VERSION "created by canmatrix"

NS_ :

BS_:

BU_: TCM iBooster HCU CIM SCM Right_Hand_Control Left_Hand_Control GPS VCM IC_2 XM GMRS Radio_CANtool Diagnostic_Tool_Digital_Wrench Information_System_Controller_1 STEERING_CONTROLLER VEHICLE_SECURITY RADIO_Hub ABS Battery_Management_Cntrl_2 Battery_Management_Cntrl_1 Auxiliary_Power_Unit_2 Auxiliary_Power_Unit_1 Electric_Propulsion_Cntrl_Unit_4 Electric_Propulsion_Cntrl_Unit_3 Electric_Propulsion_Cntrl_Unit_2 Electric_Propulsion_Cntrl_Unit_1 ECM IC

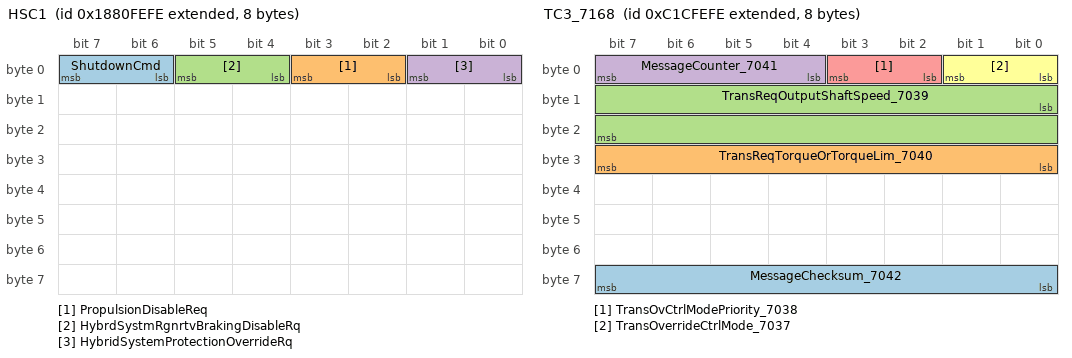
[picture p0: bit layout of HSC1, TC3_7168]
BO_ 2558590718 HSC1: 8 Vector__XXX
 SG_ ShutdownCmd : 6|2@1+ (1,0) [0.0|3.0] "" Vector__XXX
 SG_ PropulsionDisableReq : 2|2@1+ (1,0) [0.0|3.0] "" Vector__XXX
 SG_ HybrdSystmRgnrtvBrakingDisableRq : 4|2@1+ (1,0) [0.0|3.0] "" Vector__XXX
 SG_ HybridSystemProtectionOverrideRq : 0|2@1+ (1,0) [0.0|3.0] "" Vector__XXX

BO_ 2350776062 EIC_7424: 8 Vector__XXX
 SG_ EngTimingAdvance_7355 : 0|16@1+ (0.0078125,-200) [-200.0|301.99] "deg" Vector__XXX

BO_ 2350710526 TC3_7168: 8 Vector__XXX
 SG_ MessageChecksum_7042 : 56|8@1+ (1,0) [0.0|255.0] "" Vector__XXX
 SG_ TransReqTorqueOrTorqueLim_7040 : 24|8@1+ (1,-125) [-125.0|125.0] "%" Vector__XXX
 SG_ TransReqOutputShaftSpeed_7039 : 8|16@1+ (0.25,-8031.75) [-8031.375|8031.375] "rpm" Vector__XXX
 SG_ MessageCounter_7041 : 4|4@1+ (1,0) [0.0|15.0] "" Vector__XXX
 SG_ TransOvCtrlModePriority_7038 : 2|2@1+ (1,0) [0.0|3.0] "" Vector__XXX
 SG_ TransOverrideCtrlMode_7037 : 0|2@1+ (1,0) [0.0|3.0] "" Vector__XXX

BO_ 2582642430 PropA2: 8 Vector__XXX
 SG_ ManufacturerSpecificInformation : 0|64@1+ (1,0) [0.0|0.0] "" Vector__XXX

BO_ 2566836734 DM09: 8 Vector__XXX

BO_ 2566801918 GBSD: 8 Vector__XXX
 SG_ GroundBasedDirection : 56|2@1+ (1,0) [0.0|0.0] "" Vector__XXX
 SG_ GroundBasedImplementDistance : 16|32@1+ (1,0) [0.0|0.0] "" Vector__XXX
 SG_ GroundBasedImplementSpeed : 0|16@1+ (1,0) [0.0|0.0] "" Vector__XXX

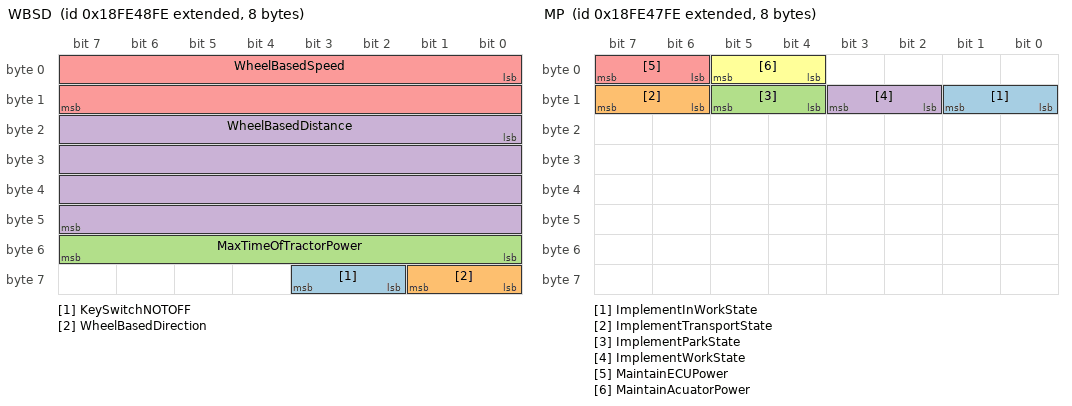
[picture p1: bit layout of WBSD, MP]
BO_ 2566801662 WBSD: 8 Vector__XXX
 SG_ KeySwitchNOTOFF : 58|2@1+ (1,0) [0.0|0.0] "" Vector__XXX
 SG_ WheelBasedDirection : 56|2@1+ (1,0) [0.0|0.0] "" Vector__XXX
 SG_ MaxTimeOfTractorPower : 48|8@1+ (1,0) [0.0|0.0] "" Vector__XXX
 SG_ WheelBasedDistance : 16|32@1+ (1,0) [0.0|0.0] "" Vector__XXX
 SG_ WheelBasedSpeed : 0|16@1+ (1,0) [0.0|0.0] "" Vector__XXX

BO_ 2566801406 MP: 8 Vector__XXX
 SG_ ImplementInWorkState : 8|2@1+ (1,0) [0.0|0.0] "" Vector__XXX
 SG_ ImplementTransportState : 14|2@1+ (1,0) [0.0|0.0] "" Vector__XXX
 SG_ ImplementParkState : 12|2@1+ (1,0) [0.0|0.0] "" Vector__XXX
 SG_ ImplementWorkState : 10|2@1+ (1,0) [0.0|0.0] "" Vector__XXX
 SG_ MaintainECUPower : 6|2@1+ (1,0) [0.0|0.0] "" Vector__XXX
 SG_ MaintainAcuatorPower : 4|2@1+ (1,0) [0.0|0.0] "" Vector__XXX

BO_ 2566801150 FHS: 8 Vector__XXX
 SG_ FrontDraft : 24|16@1+ (1,0) [0.0|0.0] "" Vector__XXX
 SG_ FrontNominalLowerLinkForce : 16|8@1+ (1,0) [0.0|0.0] "" Vector__XXX
 SG_ FrontHitchInworkIndication : 14|2@1+ (1,0) [0.0|0.0] "" Vector__XXX
 SG_ FrontHitchPos : 0|8@1+ (1,0) [0.0|0.0] "" Vector__XXX

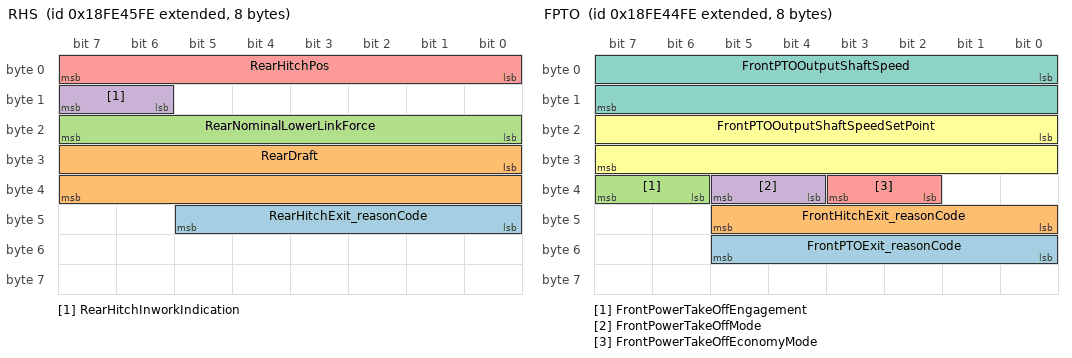
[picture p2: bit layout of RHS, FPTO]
BO_ 2566800894 RHS: 8 Vector__XXX
 SG_ RearHitchExit_reasonCode : 40|6@1+ (1,0) [0.0|0.0] "" Vector__XXX
 SG_ RearDraft : 24|16@1+ (1,0) [0.0|0.0] "" Vector__XXX
 SG_ RearNominalLowerLinkForce : 16|8@1+ (1,0) [0.0|0.0] "" Vector__XXX
 SG_ RearHitchInworkIndication : 14|2@1+ (1,0) [0.0|0.0] "" Vector__XXX
 SG_ RearHitchPos : 0|8@1+ (1,0) [0.0|0.0] "" Vector__XXX

BO_ 2566800638 FPTO: 8 Vector__XXX
 SG_ FrontPTOExit_reasonCode : 48|6@1+ (1,0) [0.0|0.0] "" Vector__XXX
 SG_ FrontHitchExit_reasonCode : 40|6@1+ (1,0) [0.0|0.0] "" Vector__XXX
 SG_ FrontPowerTakeOffEngagement : 38|2@1+ (1,0) [0.0|0.0] "" Vector__XXX
 SG_ FrontPowerTakeOffMode : 36|2@1+ (1,0) [0.0|0.0] "" Vector__XXX
 SG_ FrontPowerTakeOffEconomyMode : 34|2@1+ (1,0) [0.0|0.0] "" Vector__XXX
 SG_ FrontPTOOutputShaftSpeedSetPoint : 16|16@1+ (1,0) [0.0|0.0] "" Vector__XXX
 SG_ FrontPTOOutputShaftSpeed : 0|16@1+ (1,0) [0.0|0.0] "" Vector__XXX

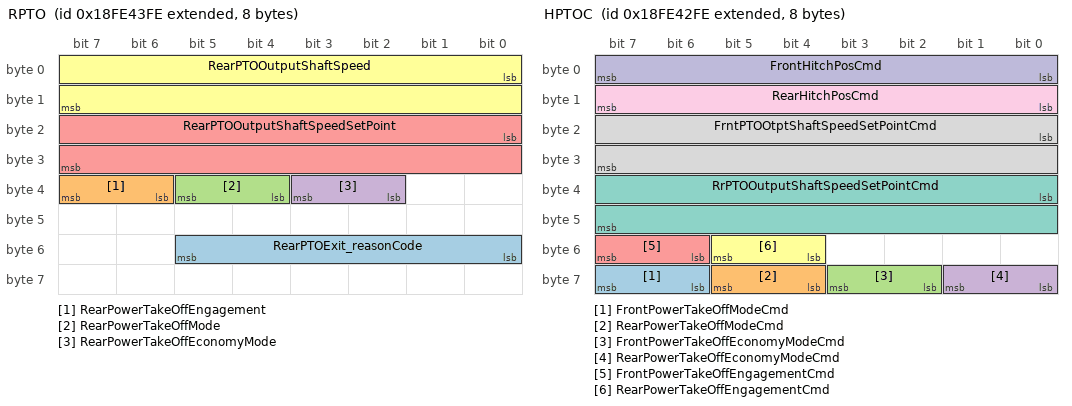
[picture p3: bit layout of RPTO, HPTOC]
BO_ 2566800382 RPTO: 8 Vector__XXX
 SG_ RearPTOExit_reasonCode : 48|6@1+ (1,0) [0.0|0.0] "" Vector__XXX
 SG_ RearPowerTakeOffEngagement : 38|2@1+ (1,0) [0.0|0.0] "" Vector__XXX
 SG_ RearPowerTakeOffMode : 36|2@1+ (1,0) [0.0|0.0] "" Vector__XXX
 SG_ RearPowerTakeOffEconomyMode : 34|2@1+ (1,0) [0.0|0.0] "" Vector__XXX
 SG_ RearPTOOutputShaftSpeedSetPoint : 16|16@1+ (1,0) [0.0|0.0] "" Vector__XXX
 SG_ RearPTOOutputShaftSpeed : 0|16@1+ (1,0) [0.0|0.0] "" Vector__XXX

BO_ 2566800126 HPTOC: 8 Vector__XXX
 SG_ FrontPowerTakeOffModeCmd : 62|2@1+ (1,0) [0.0|0.0] "" Vector__XXX
 SG_ RearPowerTakeOffModeCmd : 60|2@1+ (1,0) [0.0|0.0] "" Vector__XXX
 SG_ FrontPowerTakeOffEconomyModeCmd : 58|2@1+ (1,0) [0.0|0.0] "" Vector__XXX
 SG_ RearPowerTakeOffEconomyModeCmd : 56|2@1+ (1,0) [0.0|0.0] "" Vector__XXX
 SG_ FrontPowerTakeOffEngagementCmd : 54|2@1+ (1,0) [0.0|0.0] "" Vector__XXX
 SG_ RearPowerTakeOffEngagementCmd : 52|2@1+ (1,0) [0.0|0.0] "" Vector__XXX
 SG_ RrPTOOutputShaftSpeedSetPointCmd : 32|16@1+ (1,0) [0.0|0.0] "" Vector__XXX
 SG_ FrntPTOOtptShaftSpeedSetPointCmd : 16|16@1+ (1,0) [0.0|0.0] "" Vector__XXX
 SG_ RearHitchPosCmd : 8|8@1+ (1,0) [0.0|0.0] "" Vector__XXX
 SG_ FrontHitchPosCmd : 0|8@1+ (1,0) [0.0|0.0] "" Vector__XXX

BO_ 2566799358 AV15C: 8 Vector__XXX
 SG_ AuxValve15FailSafeModeCmd : 22|2@1+ (1,0) [0.0|0.0] "" Vector__XXX
 SG_ AuxValve15StateCmd : 16|4@1+ (1,0) [0.0|0.0] "" Vector__XXX
 SG_ AuxValve15PortFlowCmd : 0|8@1+ (1,0) [0.0|0.0] "" Vector__XXX

BO_ 2566799102 AV14C: 8 Vector__XXX
 SG_ AuxValve14FailSafeModeCmd : 22|2@1+ (1,0) [0.0|0.0] "" Vector__XXX
 SG_ AuxValve14StateCmd : 16|4@1+ (1,0) [0.0|0.0] "" Vector__XXX
 SG_ AuxValve14PortFlowCmd : 0|8@1+ (1,0) [0.0|0.0] "" Vector__XXX

BO_ 2566798846 AV13C: 8 Vector__XXX
 SG_ AuxValve13FailSafeModeCmd : 22|2@1+ (1,0) [0.0|0.0] "" Vector__XXX
 SG_ AuxValve13StateCmd : 16|4@1+ (1,0) [0.0|0.0] "" Vector__XXX
 SG_ AuxValve13PortFlowCmd : 0|8@1+ (1,0) [0.0|0.0] "" Vector__XXX

BO_ 2566798590 AV12C: 8 Vector__XXX
 SG_ AuxValve12FailSafeModeCmd : 22|2@1+ (1,0) [0.0|0.0] "" Vector__XXX
 SG_ AuxValve12StateCmd : 16|4@1+ (1,0) [0.0|0.0] "" Vector__XXX
 SG_ AuxValve12PortFlowCmd : 0|8@1+ (1,0) [0.0|0.0] "" Vector__XXX

BO_ 2566798334 AV11C: 8 Vector__XXX
 SG_ AuxValve11FailSafeModeCmd : 22|2@1+ (1,0) [0.0|0.0] "" Vector__XXX
 SG_ AuxValve11StateCmd : 16|4@1+ (1,0) [0.0|0.0] "" Vector__XXX
 SG_ AuxValve11PortFlowCmd : 0|8@1+ (1,0) [0.0|0.0] "" Vector__XXX

BO_ 2566798078 AV10C: 8 Vector__XXX
 SG_ AuxValve10FailSafeModeCmd : 22|2@1+ (1,0) [0.0|0.0] "" Vector__XXX
 SG_ AuxValve10StateCmd : 16|4@1+ (1,0) [0.0|0.0] "" Vector__XXX
 SG_ AuxValve10PortFlowCmd : 0|8@1+ (1,0) [0.0|0.0] "" Vector__XXX

BO_ 2566797822 AV09C: 8 Vector__XXX
 SG_ AuxValve9FailSafeModeCmd : 22|2@1+ (1,0) [0.0|0.0] "" Vector__XXX
 SG_ AuxValve9StateCmd : 16|4@1+ (1,0) [0.0|0.0] "" Vector__XXX
 SG_ AuxValve9PortFlowCmd : 0|8@1+ (1,0) [0.0|0.0] "" Vector__XXX

BO_ 2566797566 AV08C: 8 Vector__XXX
 SG_ AuxValve8FailSafeModeCmd : 22|2@1+ (1,0) [0.0|0.0] "" Vector__XXX
 SG_ AuxValve8StateCmd : 16|4@1+ (1,0) [0.0|0.0] "" Vector__XXX
 SG_ AuxValve8PortFlowCmd : 0|8@1+ (1,0) [0.0|0.0] "" Vector__XXX

BO_ 2566797310 AV07C: 8 Vector__XXX
 SG_ AuxValve7FailSafeModeCmd : 22|2@1+ (1,0) [0.0|0.0] "" Vector__XXX
 SG_ AuxValve7StateCmd : 16|4@1+ (1,0) [0.0|0.0] "" Vector__XXX
 SG_ AuxValve7PortFlowCmd : 0|8@1+ (1,0) [0.0|0.0] "" Vector__XXX

BO_ 2566797054 AV06C: 8 Vector__XXX
 SG_ AuxValve6FailSafeModeCmd : 22|2@1+ (1,0) [0.0|0.0] "" Vector__XXX
 SG_ AuxValve6StateCmd : 16|4@1+ (1,0) [0.0|0.0] "" Vector__XXX
 SG_ AuxValve6PortFlowCmd : 0|8@1+ (1,0) [0.0|0.0] "" Vector__XXX

BO_ 2566796798 AV05C: 8 Vector__XXX
 SG_ AuxValve5FailSafeModeCmd : 22|2@1+ (1,0) [0.0|0.0] "" Vector__XXX
 SG_ AuxValve5StateCmd : 16|4@1+ (1,0) [0.0|0.0] "" Vector__XXX
 SG_ AuxValve5PortFlowCmd : 0|8@1+ (1,0) [0.0|0.0] "" Vector__XXX

BO_ 2566796542 AV04C: 8 Vector__XXX
 SG_ AuxValve4FailSafeModeCmd : 22|2@1+ (1,0) [0.0|0.0] "" Vector__XXX
 SG_ AuxValve4StateCmd : 16|4@1+ (1,0) [0.0|0.0] "" Vector__XXX
 SG_ AuxValve4PortFlowCmd : 0|8@1+ (1,0) [0.0|0.0] "" Vector__XXX

BO_ 2566796286 AV03C: 8 Vector__XXX
 SG_ AuxValve3FailSafeModeCmd : 22|2@1+ (1,0) [0.0|0.0] "" Vector__XXX
 SG_ AuxValve3StateCmd : 16|4@1+ (1,0) [0.0|0.0] "" Vector__XXX
 SG_ AuxValve3PortFlowCmd : 0|8@1+ (1,0) [0.0|0.0] "" Vector__XXX

BO_ 2566796030 AV02C: 8 Vector__XXX
 SG_ AuxValve2FailSafeModeCmd : 22|2@1+ (1,0) [0.0|0.0] "" Vector__XXX
 SG_ AuxValve2StateCmd : 16|4@1+ (1,0) [0.0|0.0] "" Vector__XXX
 SG_ AuxValve2PortFlowCmd : 0|8@1+ (1,0) [0.0|0.0] "" Vector__XXX

BO_ 2566795774 AV01C: 8 Vector__XXX
 SG_ AuxValve1FailSafeModeCmd : 22|2@1+ (1,0) [0.0|0.0] "" Vector__XXX
 SG_ AuxValve1StateCmd : 16|4@1+ (1,0) [0.0|0.0] "" Vector__XXX
 SG_ AuxValve1PortFlowCmd : 0|8@1+ (1,0) [0.0|0.0] "" Vector__XXX

BO_ 2566795518 AV00C: 8 Vector__XXX
 SG_ AuxValve0FailSafeModeCmd : 22|2@1+ (1,0) [0.0|0.0] "" Vector__XXX
 SG_ AuxValve0StateCmd : 16|4@1+ (1,0) [0.0|0.0] "" Vector__XXX
 SG_ AuxValve0PortFlowCmd : 0|8@1+ (1,0) [0.0|0.0] "" Vector__XXX

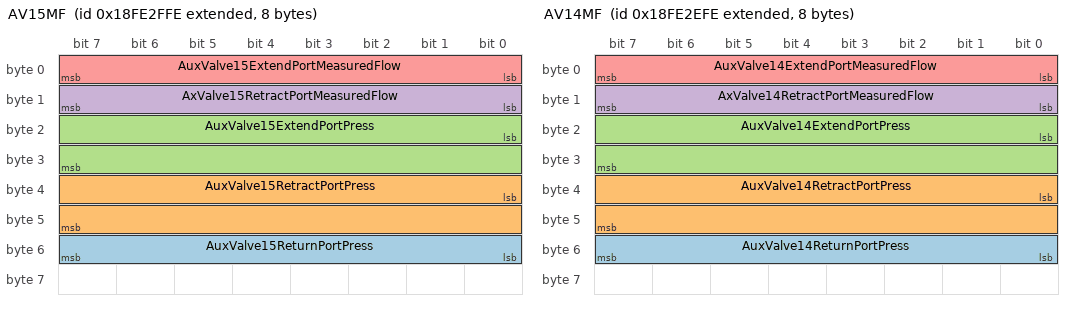
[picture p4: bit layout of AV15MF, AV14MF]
BO_ 2566795262 AV15MF: 8 Vector__XXX
 SG_ AuxValve15ReturnPortPress : 48|8@1+ (1,0) [0.0|0.0] "" Vector__XXX
 SG_ AuxValve15RetractPortPress : 32|16@1+ (1,0) [0.0|0.0] "" Vector__XXX
 SG_ AuxValve15ExtendPortPress : 16|16@1+ (1,0) [0.0|0.0] "" Vector__XXX
 SG_ AxValve15RetractPortMeasuredFlow : 8|8@1+ (1,0) [0.0|0.0] "" Vector__XXX
 SG_ AuxValve15ExtendPortMeasuredFlow : 0|8@1+ (1,0) [0.0|0.0] "" Vector__XXX

BO_ 2566795006 AV14MF: 8 Vector__XXX
 SG_ AuxValve14ReturnPortPress : 48|8@1+ (1,0) [0.0|0.0] "" Vector__XXX
 SG_ AuxValve14RetractPortPress : 32|16@1+ (1,0) [0.0|0.0] "" Vector__XXX
 SG_ AuxValve14ExtendPortPress : 16|16@1+ (1,0) [0.0|0.0] "" Vector__XXX
 SG_ AxValve14RetractPortMeasuredFlow : 8|8@1+ (1,0) [0.0|0.0] "" Vector__XXX
 SG_ AuxValve14ExtendPortMeasuredFlow : 0|8@1+ (1,0) [0.0|0.0] "" Vector__XXX

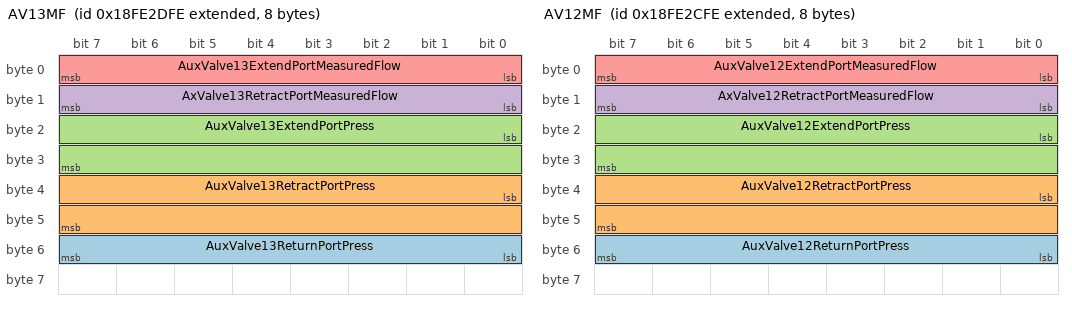
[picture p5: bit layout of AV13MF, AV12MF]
BO_ 2566794750 AV13MF: 8 Vector__XXX
 SG_ AuxValve13ReturnPortPress : 48|8@1+ (1,0) [0.0|0.0] "" Vector__XXX
 SG_ AuxValve13RetractPortPress : 32|16@1+ (1,0) [0.0|0.0] "" Vector__XXX
 SG_ AuxValve13ExtendPortPress : 16|16@1+ (1,0) [0.0|0.0] "" Vector__XXX
 SG_ AxValve13RetractPortMeasuredFlow : 8|8@1+ (1,0) [0.0|0.0] "" Vector__XXX
 SG_ AuxValve13ExtendPortMeasuredFlow : 0|8@1+ (1,0) [0.0|0.0] "" Vector__XXX

BO_ 2566794494 AV12MF: 8 Vector__XXX
 SG_ AuxValve12ReturnPortPress : 48|8@1+ (1,0) [0.0|0.0] "" Vector__XXX
 SG_ AuxValve12RetractPortPress : 32|16@1+ (1,0) [0.0|0.0] "" Vector__XXX
 SG_ AuxValve12ExtendPortPress : 16|16@1+ (1,0) [0.0|0.0] "" Vector__XXX
 SG_ AxValve12RetractPortMeasuredFlow : 8|8@1+ (1,0) [0.0|0.0] "" Vector__XXX
 SG_ AuxValve12ExtendPortMeasuredFlow : 0|8@1+ (1,0) [0.0|0.0] "" Vector__XXX

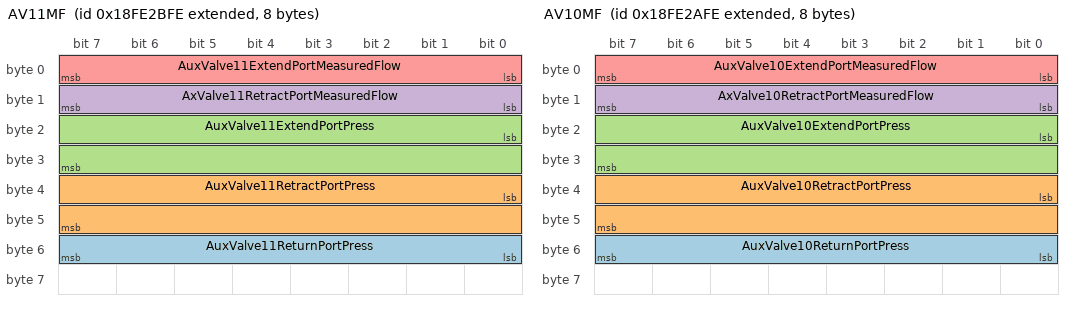
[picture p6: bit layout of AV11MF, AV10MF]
BO_ 2566794238 AV11MF: 8 Vector__XXX
 SG_ AuxValve11ReturnPortPress : 48|8@1+ (1,0) [0.0|0.0] "" Vector__XXX
 SG_ AuxValve11RetractPortPress : 32|16@1+ (1,0) [0.0|0.0] "" Vector__XXX
 SG_ AuxValve11ExtendPortPress : 16|16@1+ (1,0) [0.0|0.0] "" Vector__XXX
 SG_ AxValve11RetractPortMeasuredFlow : 8|8@1+ (1,0) [0.0|0.0] "" Vector__XXX
 SG_ AuxValve11ExtendPortMeasuredFlow : 0|8@1+ (1,0) [0.0|0.0] "" Vector__XXX

BO_ 2566793982 AV10MF: 8 Vector__XXX
 SG_ AuxValve10ReturnPortPress : 48|8@1+ (1,0) [0.0|0.0] "" Vector__XXX
 SG_ AuxValve10RetractPortPress : 32|16@1+ (1,0) [0.0|0.0] "" Vector__XXX
 SG_ AuxValve10ExtendPortPress : 16|16@1+ (1,0) [0.0|0.0] "" Vector__XXX
 SG_ AxValve10RetractPortMeasuredFlow : 8|8@1+ (1,0) [0.0|0.0] "" Vector__XXX
 SG_ AuxValve10ExtendPortMeasuredFlow : 0|8@1+ (1,0) [0.0|0.0] "" Vector__XXX

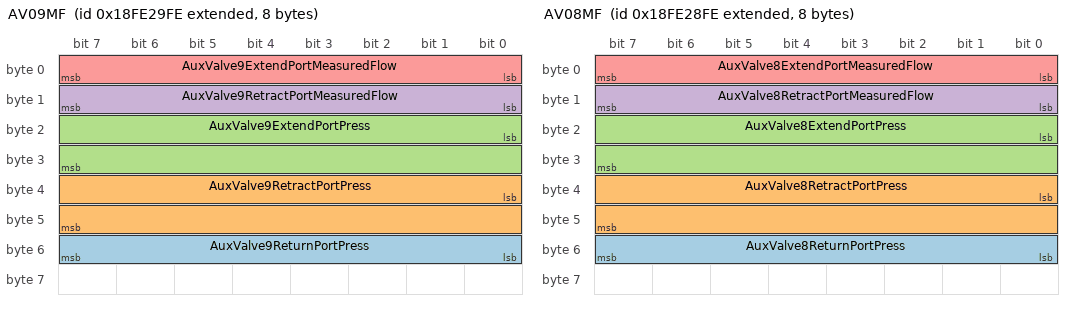
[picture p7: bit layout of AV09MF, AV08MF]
BO_ 2566793726 AV09MF: 8 Vector__XXX
 SG_ AuxValve9ReturnPortPress : 48|8@1+ (1,0) [0.0|0.0] "" Vector__XXX
 SG_ AuxValve9RetractPortPress : 32|16@1+ (1,0) [0.0|0.0] "" Vector__XXX
 SG_ AuxValve9ExtendPortPress : 16|16@1+ (1,0) [0.0|0.0] "" Vector__XXX
 SG_ AuxValve9RetractPortMeasuredFlow : 8|8@1+ (1,0) [0.0|0.0] "" Vector__XXX
 SG_ AuxValve9ExtendPortMeasuredFlow : 0|8@1+ (1,0) [0.0|0.0] "" Vector__XXX

BO_ 2566793470 AV08MF: 8 Vector__XXX
 SG_ AuxValve8ReturnPortPress : 48|8@1+ (1,0) [0.0|0.0] "" Vector__XXX
 SG_ AuxValve8RetractPortPress : 32|16@1+ (1,0) [0.0|0.0] "" Vector__XXX
 SG_ AuxValve8ExtendPortPress : 16|16@1+ (1,0) [0.0|0.0] "" Vector__XXX
 SG_ AuxValve8RetractPortMeasuredFlow : 8|8@1+ (1,0) [0.0|0.0] "" Vector__XXX
 SG_ AuxValve8ExtendPortMeasuredFlow : 0|8@1+ (1,0) [0.0|0.0] "" Vector__XXX

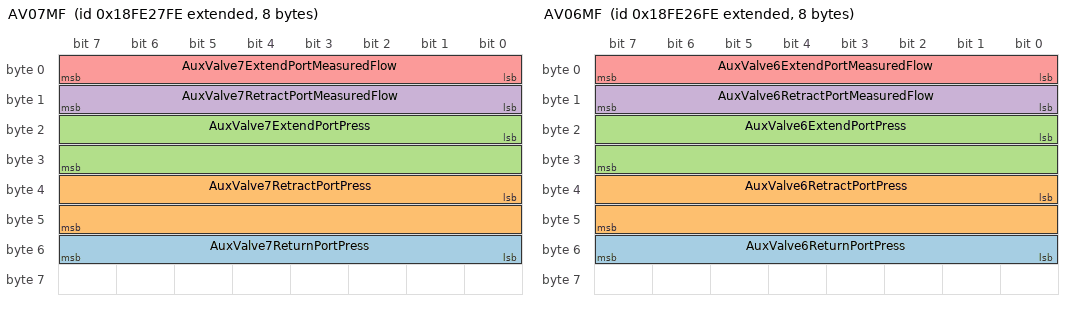
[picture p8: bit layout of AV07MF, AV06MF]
BO_ 2566793214 AV07MF: 8 Vector__XXX
 SG_ AuxValve7ReturnPortPress : 48|8@1+ (1,0) [0.0|0.0] "" Vector__XXX
 SG_ AuxValve7RetractPortPress : 32|16@1+ (1,0) [0.0|0.0] "" Vector__XXX
 SG_ AuxValve7ExtendPortPress : 16|16@1+ (1,0) [0.0|0.0] "" Vector__XXX
 SG_ AuxValve7RetractPortMeasuredFlow : 8|8@1+ (1,0) [0.0|0.0] "" Vector__XXX
 SG_ AuxValve7ExtendPortMeasuredFlow : 0|8@1+ (1,0) [0.0|0.0] "" Vector__XXX

BO_ 2566792958 AV06MF: 8 Vector__XXX
 SG_ AuxValve6ReturnPortPress : 48|8@1+ (1,0) [0.0|0.0] "" Vector__XXX
 SG_ AuxValve6RetractPortPress : 32|16@1+ (1,0) [0.0|0.0] "" Vector__XXX
 SG_ AuxValve6ExtendPortPress : 16|16@1+ (1,0) [0.0|0.0] "" Vector__XXX
 SG_ AuxValve6RetractPortMeasuredFlow : 8|8@1+ (1,0) [0.0|0.0] "" Vector__XXX
 SG_ AuxValve6ExtendPortMeasuredFlow : 0|8@1+ (1,0) [0.0|0.0] "" Vector__XXX

BO_ 2566792702 AV05MF: 8 Vector__XXX
 SG_ AuxValve5ReturnPortPress : 48|8@1+ (1,0) [0.0|0.0] "" Vector__XXX
 SG_ AuxValve5RetractPortPress : 32|16@1+ (1,0) [0.0|0.0] "" Vector__XXX
 SG_ AuxValve5ExtendPortPress : 16|16@1+ (1,0) [0.0|0.0] "" Vector__XXX
 SG_ AuxValve5RetractPortMeasuredFlow : 8|8@1+ (1,0) [0.0|0.0] "" Vector__XXX
 SG_ AuxValve5ExtendPortMeasuredFlow : 0|8@1+ (1,0) [0.0|0.0] "" Vector__XXX

BO_ 2566792446 AV04MF: 8 Vector__XXX
 SG_ AuxValve4ReturnPortPress : 48|8@1+ (1,0) [0.0|0.0] "" Vector__XXX
 SG_ AuxValve4RetractPortPress : 32|16@1+ (1,0) [0.0|0.0] "" Vector__XXX
 SG_ AuxValve4ExtendPortPress : 16|16@1+ (1,0) [0.0|0.0] "" Vector__XXX
 SG_ AuxValve4RetractPortMeasuredFlow : 8|8@1+ (1,0) [0.0|0.0] "" Vector__XXX
 SG_ AuxValve4ExtendPortMeasuredFlow : 0|8@1+ (1,0) [0.0|0.0] "" Vector__XXX

BO_ 2566792190 AV03MF: 8 Vector__XXX
 SG_ AuxValve3ReturnPortPress : 48|8@1+ (1,0) [0.0|0.0] "" Vector__XXX
 SG_ AuxValve3RetractPortPress : 32|16@1+ (1,0) [0.0|0.0] "" Vector__XXX
 SG_ AuxValve3ExtendPortPress : 16|16@1+ (1,0) [0.0|0.0] "" Vector__XXX
 SG_ AuxValve3RetractPortMeasuredFlow : 8|8@1+ (1,0) [0.0|0.0] "" Vector__XXX
 SG_ AuxValve3ExtendPortMeasuredFlow : 0|8@1+ (1,0) [0.0|0.0] "" Vector__XXX

BO_ 2566791934 AV02MF: 8 Vector__XXX
 SG_ AuxValve2ReturnPortPress : 48|8@1+ (1,0) [0.0|0.0] "" Vector__XXX
 SG_ AuxValve2RetractPortPress : 32|16@1+ (1,0) [0.0|0.0] "" Vector__XXX
 SG_ AuxValve2ExtendPortPress : 16|16@1+ (1,0) [0.0|0.0] "" Vector__XXX
 SG_ AuxValve2RetractPortMeasuredFlow : 8|8@1+ (1,0) [0.0|0.0] "" Vector__XXX
 SG_ AuxValve2ExtendPortMeasuredFlow : 0|8@1+ (1,0) [0.0|0.0] "" Vector__XXX

BO_ 2566791678 AV01MF: 8 Vector__XXX
 SG_ AuxValve1ReturnPortPress : 48|8@1+ (1,0) [0.0|0.0] "" Vector__XXX
 SG_ AuxValve1RetractPortPress : 32|16@1+ (1,0) [0.0|0.0] "" Vector__XXX
 SG_ AuxValve1ExtendPortPress : 16|16@1+ (1,0) [0.0|0.0] "" Vector__XXX
 SG_ AuxValve1RetractPortMeasuredFlow : 8|8@1+ (1,0) [0.0|0.0] "" Vector__XXX
 SG_ AuxValve1ExtendPortMeasuredFlow : 0|8@1+ (1,0) [0.0|0.0] "" Vector__XXX

BO_ 2566791422 AV00MF: 8 Vector__XXX
 SG_ AuxValve0ReturnPortPress : 48|8@1+ (1,0) [0.0|0.0] "" Vector__XXX
 SG_ AuxValve0RetractPortPress : 32|16@1+ (1,0) [0.0|0.0] "" Vector__XXX
 SG_ AuxValve0ExtendPortPress : 16|16@1+ (1,0) [0.0|0.0] "" Vector__XXX
 SG_ AuxValve0RetractPortMeasuredFlow : 8|8@1+ (1,0) [0.0|0.0] "" Vector__XXX
 SG_ AuxValve0ExtendPortMeasuredFlow : 0|8@1+ (1,0) [0.0|0.0] "" Vector__XXX

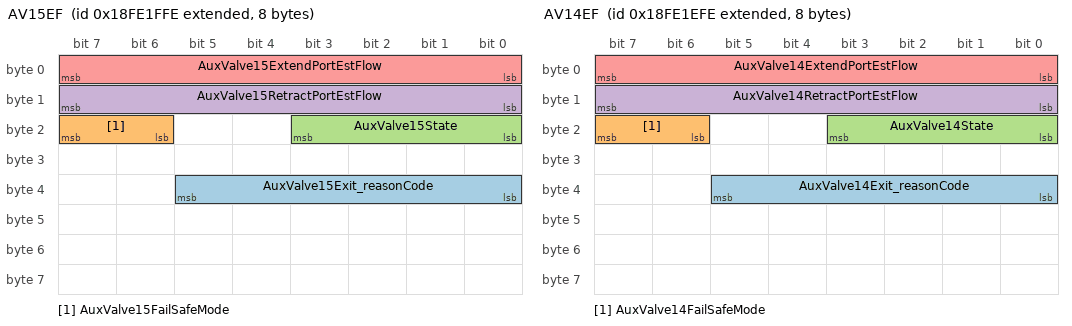
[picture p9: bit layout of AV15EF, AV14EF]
BO_ 2566791166 AV15EF: 8 Vector__XXX
 SG_ AuxValve15Exit_reasonCode : 32|6@1+ (1,0) [0.0|0.0] "" Vector__XXX
 SG_ AuxValve15FailSafeMode : 22|2@1+ (1,0) [0.0|0.0] "" Vector__XXX
 SG_ AuxValve15State : 16|4@1+ (1,0) [0.0|0.0] "" Vector__XXX
 SG_ AuxValve15RetractPortEstFlow : 8|8@1+ (1,0) [0.0|0.0] "" Vector__XXX
 SG_ AuxValve15ExtendPortEstFlow : 0|8@1+ (1,0) [0.0|0.0] "" Vector__XXX

BO_ 2566790910 AV14EF: 8 Vector__XXX
 SG_ AuxValve14Exit_reasonCode : 32|6@1+ (1,0) [0.0|0.0] "" Vector__XXX
 SG_ AuxValve14FailSafeMode : 22|2@1+ (1,0) [0.0|0.0] "" Vector__XXX
 SG_ AuxValve14State : 16|4@1+ (1,0) [0.0|0.0] "" Vector__XXX
 SG_ AuxValve14RetractPortEstFlow : 8|8@1+ (1,0) [0.0|0.0] "" Vector__XXX
 SG_ AuxValve14ExtendPortEstFlow : 0|8@1+ (1,0) [0.0|0.0] "" Vector__XXX

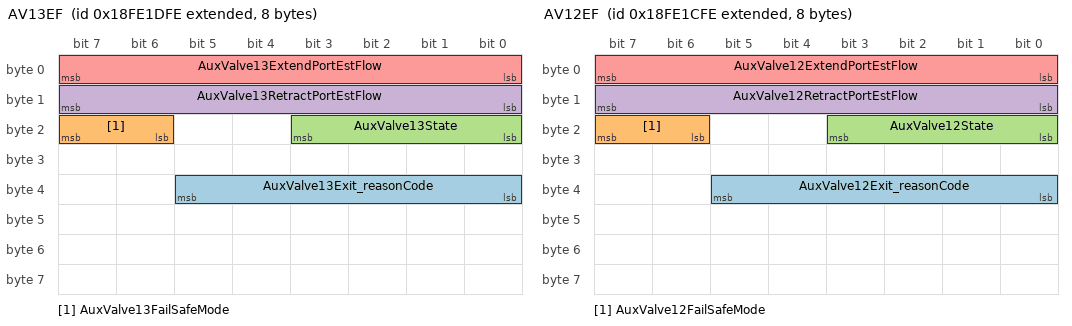
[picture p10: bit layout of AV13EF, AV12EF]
BO_ 2566790654 AV13EF: 8 Vector__XXX
 SG_ AuxValve13Exit_reasonCode : 32|6@1+ (1,0) [0.0|0.0] "" Vector__XXX
 SG_ AuxValve13FailSafeMode : 22|2@1+ (1,0) [0.0|0.0] "" Vector__XXX
 SG_ AuxValve13State : 16|4@1+ (1,0) [0.0|0.0] "" Vector__XXX
 SG_ AuxValve13RetractPortEstFlow : 8|8@1+ (1,0) [0.0|0.0] "" Vector__XXX
 SG_ AuxValve13ExtendPortEstFlow : 0|8@1+ (1,0) [0.0|0.0] "" Vector__XXX

BO_ 2566790398 AV12EF: 8 Vector__XXX
 SG_ AuxValve12Exit_reasonCode : 32|6@1+ (1,0) [0.0|0.0] "" Vector__XXX
 SG_ AuxValve12FailSafeMode : 22|2@1+ (1,0) [0.0|0.0] "" Vector__XXX
 SG_ AuxValve12State : 16|4@1+ (1,0) [0.0|0.0] "" Vector__XXX
 SG_ AuxValve12RetractPortEstFlow : 8|8@1+ (1,0) [0.0|0.0] "" Vector__XXX
 SG_ AuxValve12ExtendPortEstFlow : 0|8@1+ (1,0) [0.0|0.0] "" Vector__XXX

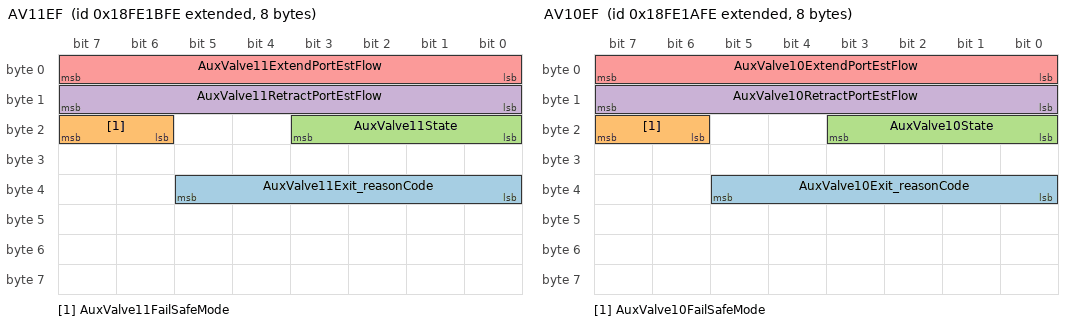
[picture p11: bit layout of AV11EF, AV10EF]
BO_ 2566790142 AV11EF: 8 Vector__XXX
 SG_ AuxValve11Exit_reasonCode : 32|6@1+ (1,0) [0.0|0.0] "" Vector__XXX
 SG_ AuxValve11FailSafeMode : 22|2@1+ (1,0) [0.0|0.0] "" Vector__XXX
 SG_ AuxValve11State : 16|4@1+ (1,0) [0.0|0.0] "" Vector__XXX
 SG_ AuxValve11RetractPortEstFlow : 8|8@1+ (1,0) [0.0|0.0] "" Vector__XXX
 SG_ AuxValve11ExtendPortEstFlow : 0|8@1+ (1,0) [0.0|0.0] "" Vector__XXX

BO_ 2566789886 AV10EF: 8 Vector__XXX
 SG_ AuxValve10Exit_reasonCode : 32|6@1+ (1,0) [0.0|0.0] "" Vector__XXX
 SG_ AuxValve10FailSafeMode : 22|2@1+ (1,0) [0.0|0.0] "" Vector__XXX
 SG_ AuxValve10State : 16|4@1+ (1,0) [0.0|0.0] "" Vector__XXX
 SG_ AuxValve10RetractPortEstFlow : 8|8@1+ (1,0) [0.0|0.0] "" Vector__XXX
 SG_ AuxValve10ExtendPortEstFlow : 0|8@1+ (1,0) [0.0|0.0] "" Vector__XXX

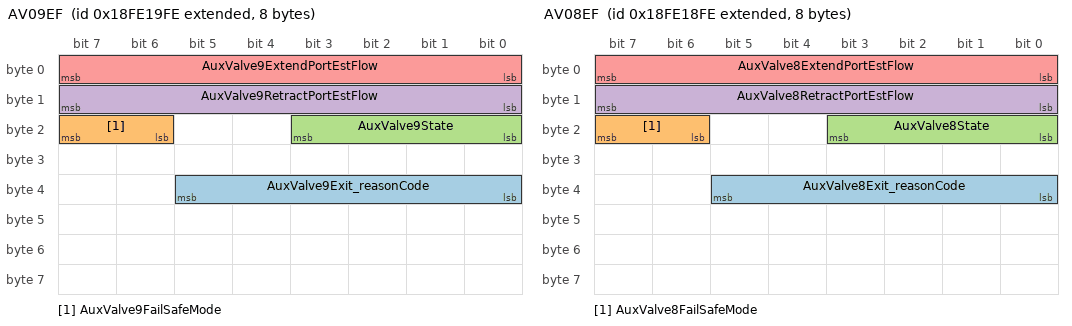
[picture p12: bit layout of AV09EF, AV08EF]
BO_ 2566789630 AV09EF: 8 Vector__XXX
 SG_ AuxValve9Exit_reasonCode : 32|6@1+ (1,0) [0.0|0.0] "" Vector__XXX
 SG_ AuxValve9FailSafeMode : 22|2@1+ (1,0) [0.0|0.0] "" Vector__XXX
 SG_ AuxValve9State : 16|4@1+ (1,0) [0.0|0.0] "" Vector__XXX
 SG_ AuxValve9RetractPortEstFlow : 8|8@1+ (1,0) [0.0|0.0] "" Vector__XXX
 SG_ AuxValve9ExtendPortEstFlow : 0|8@1+ (1,0) [0.0|0.0] "" Vector__XXX

BO_ 2566789374 AV08EF: 8 Vector__XXX
 SG_ AuxValve8Exit_reasonCode : 32|6@1+ (1,0) [0.0|0.0] "" Vector__XXX
 SG_ AuxValve8FailSafeMode : 22|2@1+ (1,0) [0.0|0.0] "" Vector__XXX
 SG_ AuxValve8State : 16|4@1+ (1,0) [0.0|0.0] "" Vector__XXX
 SG_ AuxValve8RetractPortEstFlow : 8|8@1+ (1,0) [0.0|0.0] "" Vector__XXX
 SG_ AuxValve8ExtendPortEstFlow : 0|8@1+ (1,0) [0.0|0.0] "" Vector__XXX

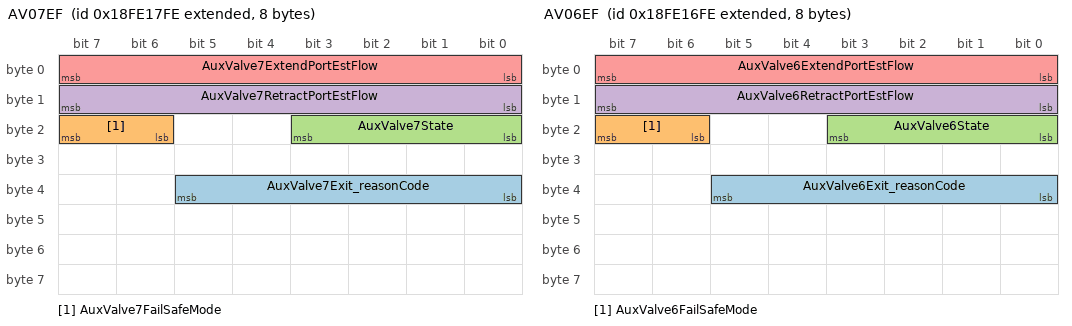
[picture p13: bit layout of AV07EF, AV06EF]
BO_ 2566789118 AV07EF: 8 Vector__XXX
 SG_ AuxValve7Exit_reasonCode : 32|6@1+ (1,0) [0.0|0.0] "" Vector__XXX
 SG_ AuxValve7FailSafeMode : 22|2@1+ (1,0) [0.0|0.0] "" Vector__XXX
 SG_ AuxValve7State : 16|4@1+ (1,0) [0.0|0.0] "" Vector__XXX
 SG_ AuxValve7RetractPortEstFlow : 8|8@1+ (1,0) [0.0|0.0] "" Vector__XXX
 SG_ AuxValve7ExtendPortEstFlow : 0|8@1+ (1,0) [0.0|0.0] "" Vector__XXX

BO_ 2566788862 AV06EF: 8 Vector__XXX
 SG_ AuxValve6Exit_reasonCode : 32|6@1+ (1,0) [0.0|0.0] "" Vector__XXX
 SG_ AuxValve6FailSafeMode : 22|2@1+ (1,0) [0.0|0.0] "" Vector__XXX
 SG_ AuxValve6State : 16|4@1+ (1,0) [0.0|0.0] "" Vector__XXX
 SG_ AuxValve6RetractPortEstFlow : 8|8@1+ (1,0) [0.0|0.0] "" Vector__XXX
 SG_ AuxValve6ExtendPortEstFlow : 0|8@1+ (1,0) [0.0|0.0] "" Vector__XXX

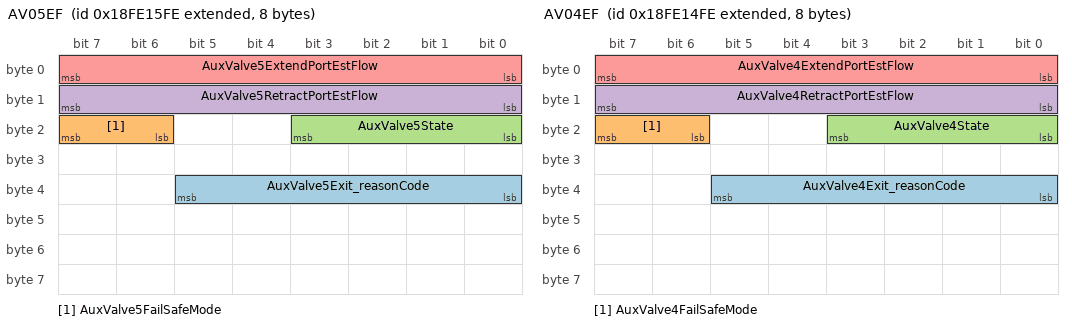
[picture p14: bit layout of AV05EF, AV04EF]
BO_ 2566788606 AV05EF: 8 Vector__XXX
 SG_ AuxValve5Exit_reasonCode : 32|6@1+ (1,0) [0.0|0.0] "" Vector__XXX
 SG_ AuxValve5FailSafeMode : 22|2@1+ (1,0) [0.0|0.0] "" Vector__XXX
 SG_ AuxValve5State : 16|4@1+ (1,0) [0.0|0.0] "" Vector__XXX
 SG_ AuxValve5RetractPortEstFlow : 8|8@1+ (1,0) [0.0|0.0] "" Vector__XXX
 SG_ AuxValve5ExtendPortEstFlow : 0|8@1+ (1,0) [0.0|0.0] "" Vector__XXX

BO_ 2566788350 AV04EF: 8 Vector__XXX
 SG_ AuxValve4Exit_reasonCode : 32|6@1+ (1,0) [0.0|0.0] "" Vector__XXX
 SG_ AuxValve4FailSafeMode : 22|2@1+ (1,0) [0.0|0.0] "" Vector__XXX
 SG_ AuxValve4State : 16|4@1+ (1,0) [0.0|0.0] "" Vector__XXX
 SG_ AuxValve4RetractPortEstFlow : 8|8@1+ (1,0) [0.0|0.0] "" Vector__XXX
 SG_ AuxValve4ExtendPortEstFlow : 0|8@1+ (1,0) [0.0|0.0] "" Vector__XXX

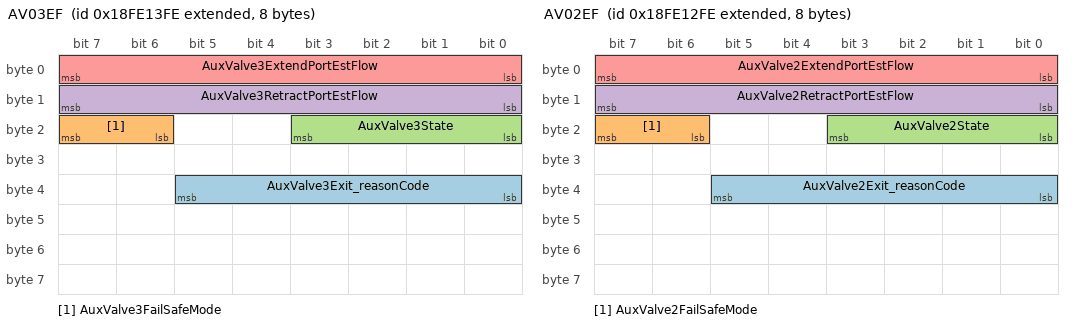
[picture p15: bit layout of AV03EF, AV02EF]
BO_ 2566788094 AV03EF: 8 Vector__XXX
 SG_ AuxValve3Exit_reasonCode : 32|6@1+ (1,0) [0.0|0.0] "" Vector__XXX
 SG_ AuxValve3FailSafeMode : 22|2@1+ (1,0) [0.0|0.0] "" Vector__XXX
 SG_ AuxValve3State : 16|4@1+ (1,0) [0.0|0.0] "" Vector__XXX
 SG_ AuxValve3RetractPortEstFlow : 8|8@1+ (1,0) [0.0|0.0] "" Vector__XXX
 SG_ AuxValve3ExtendPortEstFlow : 0|8@1+ (1,0) [0.0|0.0] "" Vector__XXX

BO_ 2566787838 AV02EF: 8 Vector__XXX
 SG_ AuxValve2Exit_reasonCode : 32|6@1+ (1,0) [0.0|0.0] "" Vector__XXX
 SG_ AuxValve2FailSafeMode : 22|2@1+ (1,0) [0.0|0.0] "" Vector__XXX
 SG_ AuxValve2State : 16|4@1+ (1,0) [0.0|0.0] "" Vector__XXX
 SG_ AuxValve2RetractPortEstFlow : 8|8@1+ (1,0) [0.0|0.0] "" Vector__XXX
 SG_ AuxValve2ExtendPortEstFlow : 0|8@1+ (1,0) [0.0|0.0] "" Vector__XXX

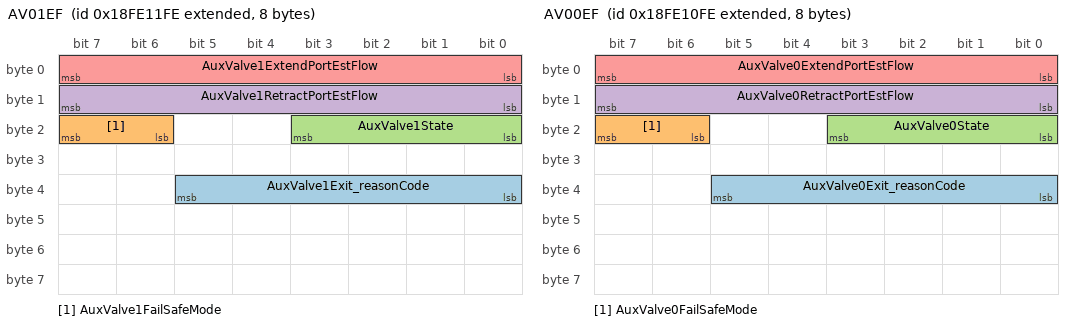
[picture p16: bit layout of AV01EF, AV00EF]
BO_ 2566787582 AV01EF: 8 Vector__XXX
 SG_ AuxValve1Exit_reasonCode : 32|6@1+ (1,0) [0.0|0.0] "" Vector__XXX
 SG_ AuxValve1FailSafeMode : 22|2@1+ (1,0) [0.0|0.0] "" Vector__XXX
 SG_ AuxValve1State : 16|4@1+ (1,0) [0.0|0.0] "" Vector__XXX
 SG_ AuxValve1RetractPortEstFlow : 8|8@1+ (1,0) [0.0|0.0] "" Vector__XXX
 SG_ AuxValve1ExtendPortEstFlow : 0|8@1+ (1,0) [0.0|0.0] "" Vector__XXX

BO_ 2566787326 AV00EF: 8 Vector__XXX
 SG_ AuxValve0Exit_reasonCode : 32|6@1+ (1,0) [0.0|0.0] "" Vector__XXX
 SG_ AuxValve0FailSafeMode : 22|2@1+ (1,0) [0.0|0.0] "" Vector__XXX
 SG_ AuxValve0State : 16|4@1+ (1,0) [0.0|0.0] "" Vector__XXX
 SG_ AuxValve0RetractPortEstFlow : 8|8@1+ (1,0) [0.0|0.0] "" Vector__XXX
 SG_ AuxValve0ExtendPortEstFlow : 0|8@1+ (1,0) [0.0|0.0] "" Vector__XXX

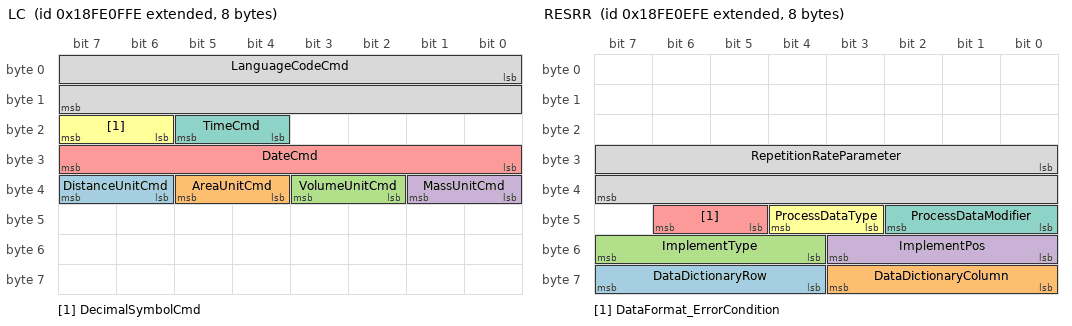
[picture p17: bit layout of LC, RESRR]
BO_ 2566787070 LC: 8 Vector__XXX
 SG_ DistanceUnitCmd : 38|2@1+ (1,0) [0.0|0.0] "" Vector__XXX
 SG_ AreaUnitCmd : 36|2@1+ (1,0) [0.0|0.0] "" Vector__XXX
 SG_ VolumeUnitCmd : 34|2@1+ (1,0) [0.0|0.0] "" Vector__XXX
 SG_ MassUnitCmd : 32|2@1+ (1,0) [0.0|0.0] "" Vector__XXX
 SG_ DateCmd : 24|8@1+ (1,0) [0.0|0.0] "" Vector__XXX
 SG_ DecimalSymbolCmd : 22|2@1+ (1,0) [0.0|0.0] "" Vector__XXX
 SG_ TimeCmd : 20|2@1+ (1,0) [0.0|0.0] "" Vector__XXX
 SG_ LanguageCodeCmd : 0|16@1+ (1,0) [0.0|0.0] "" Vector__XXX

BO_ 2566786814 RESRR: 8 Vector__XXX
 SG_ DataDictionaryRow : 60|4@1+ (1,0) [0.0|0.0] "" Vector__XXX
 SG_ DataDictionaryColumn : 56|4@1+ (1,0) [0.0|0.0] "" Vector__XXX
 SG_ ImplementType : 52|4@1+ (1,0) [0.0|0.0] "" Vector__XXX
 SG_ ImplementPos : 48|4@1+ (1,0) [0.0|0.0] "" Vector__XXX
 SG_ DataFormat_ErrorCondition : 45|2@1+ (1,0) [0.0|0.0] "" Vector__XXX
 SG_ ProcessDataType : 43|2@1+ (1,0) [0.0|0.0] "" Vector__XXX
 SG_ ProcessDataModifier : 40|3@1+ (1,0) [0.0|0.0] "" Vector__XXX
 SG_ RepetitionRateParameter : 24|16@1+ (1,0) [0.0|0.0] "" Vector__XXX

BO_ 2566786046 IRC: 8 Vector__XXX

BO_ 2566785790 IRCR: 8 Vector__XXX

BO_ 2566785534 TFR: 8 Vector__XXX
 SG_ TrctrFcltyRspLmt_RqstSttsRprting : 27|1@1+ (1,0) [0.0|0.0] "" Vector__XXX

BO_ 2566785278 RTF: 8 Vector__XXX
 SG_ TrctrFcltyRqLmt_RqstSttsRporting : 27|1@1+ (1,0) [0.0|0.0] "" Vector__XXX

BO_ 2566774526 MAM21: 8 Vector__XXX

BO_ 2566774270 MAM11: 8 Vector__XXX

BO_ 2566770686 WSM: 8 Vector__XXX
 SG_ NumberOfMembers : 0|8@1+ (1,0) [0.0|0.0] "" Vector__XXX

BO_ 2566770430 WSMM: 8 Vector__XXX
 SG_ NAMEOfWorkingSetMember : 0|64@1+ (1,0) [0.0|0.0] "" Vector__XXX

BO_ 2566761470 RCMS: 8 Vector__XXX
 SG_ PGNOfConfigurableMessageDesired : 8|24@1+ (1,0) [0.0|16777215.0] "" Vector__XXX
 SG_ MessageSelectionCtrl : 0|8@1+ (1,0) [0.0|250.0] "" Vector__XXX

BO_ 2566754814 ACS: 8 Vector__XXX
 SG_ AutomaticTransferSwitchStatus : 8|3@1+ (1,0) [0.0|7.0] "" Vector__XXX
 SG_ UtilityCircuitBreakerStatus : 3|3@1+ (1,0) [0.0|7.0] "" Vector__XXX
 SG_ GeneratorCircuitBreakerStatus : 0|3@1+ (1,0) [0.0|7.0] "" Vector__XXX

BO_ 2566754302 GTACPP: 8 Vector__XXX
 SG_ GeneratorTotalPercentKVAr : 32|16@1+ (0.0078125,-251) [-251.0|250.99] "%" Vector__XXX
 SG_ GeneratorTotalPercentKVA : 16|16@1+ (0.0078125,-251) [-251.0|250.99] "%" Vector__XXX
 SG_ GeneratorTotalPercentKW : 0|16@1+ (0.0078125,-251) [-251.0|250.99] "%" Vector__XXX

BO_ 2566754046 GTACER: 8 Vector__XXX
 SG_ GeneratorTotalKVArHoursImport : 32|32@1+ (1,0) [0.0|4211081215.0] "kVArh" Vector__XXX
 SG_ GeneratorTotalKVArHoursExport : 0|32@1+ (1,0) [0.0|4211081215.0] "kVArh" Vector__XXX

BO_ 2566753790 UTACER: 8 Vector__XXX
 SG_ UtilityTotalKVArHoursImport : 32|32@1+ (1,0) [0.0|4211081215.0] "kVArh" Vector__XXX
 SG_ UtilityTotalKVArHoursExport : 0|32@1+ (1,0) [0.0|4211081215.0] "kVArh" Vector__XXX

BO_ 2566738174 GPM19: 8 Vector__XXX

BO_ 2566737918 GPM26: 8 Vector__XXX

BO_ 2566737662 GPM27: 8 Vector__XXX

BO_ 2566737406 GPM28: 8 Vector__XXX

BO_ 2566737150 GPM29: 8 Vector__XXX

BO_ 2566736894 GPM210: 8 Vector__XXX

BO_ 2566736638 GPM211: 8 Vector__XXX

BO_ 2566734846 MSSC: 8 Vector__XXX
 SG_ MachineSelectedDirectionCmd : 56|2@1+ (1,0) [0.0|0.0] "" Vector__XXX
 SG_ MchnSelectedSpeedExit_reasonCode : 48|6@1+ (1,0) [0.0|0.0] "" Vector__XXX
 SG_ MchineSelectedSpeedSetpointLimit : 16|16@1+ (1,0) [0.0|0.0] "" Vector__XXX
 SG_ MachineSelectedSpeedSetpointCmd : 0|16@1+ (1,0) [0.0|0.0] "" Vector__XXX

BO_ 2566734590 ICC: 8 Vector__XXX
 SG_ ISOBUSCmplncCrtfctnMssgeRevision : 47|1@1+ (1,0) [0.0|0.0] "" Vector__XXX
 SG_ ISOBUSCmplncCrtfctnRfrenceNumber : 48|16@1+ (1,0) [0.0|0.0] "" Vector__XXX
 SG_ ISOBUSCmplncCrtfctonTypeTaskCtrl : 39|1@1+ (1,0) [0.0|0.0] "" Vector__XXX
 SG_ ISOBUSCmplncCrtfctnTypTCWrkn4326 : 38|1@1+ (1,0) [0.0|0.0] "" Vector__XXX
 SG_ ISOBUSCmplncCrtfctnTypTCWrkngStM : 37|1@1+ (1,0) [0.0|0.0] "" Vector__XXX
 SG_ ISOBUSCmplncCrtfctnTypFileServer : 36|1@1+ (1,0) [0.0|0.0] "" Vector__XXX
 SG_ ISOBUSCmplncCrtfctnTypGPSRceiver : 35|1@1+ (1,0) [0.0|0.0] "" Vector__XXX
 SG_ ISOBUSCmplncCrtfcationTypeMinECU : 31|1@1+ (1,0) [0.0|0.0] "" Vector__XXX
 SG_ ISOBUSCmplncCrtfctnTypTECUClass1 : 30|1@1+ (1,0) [0.0|0.0] "" Vector__XXX
 SG_ ISOBUSCmplncCrtfctnTypTECUClass2 : 29|1@1+ (1,0) [0.0|0.0] "" Vector__XXX
 SG_ ISOBUSCmplncCrtfctnTypTECUClass3 : 28|1@1+ (1,0) [0.0|0.0] "" Vector__XXX
 SG_ ISOBUSCmplncCrtfctnTypeClass3ECU : 27|1@1+ (1,0) [0.0|0.0] "" Vector__XXX
 SG_ ISOBUSCmplncCrtfctnTypVrtlTrmnal : 26|1@1+ (1,0) [0.0|0.0] "" Vector__XXX
 SG_ ISOBUSCmplncCrtfctnTypVTWrkn4323 : 25|1@1+ (1,0) [0.0|0.0] "" Vector__XXX
 SG_ ISOBUSCmplncCrtfctnTypVTWrkngStM : 24|1@1+ (1,0) [0.0|0.0] "" Vector__XXX
 SG_ ISOBUSCmplncCrtfctonLaboratoryID : 13|11@1+ (1,0) [0.0|0.0] "" Vector__XXX
 SG_ ISOBUSCmplncCrtfctLaboratoryType : 9|3@1+ (1,0) [0.0|0.0] "" Vector__XXX
 SG_ ISOBUSCmplnceCertificateRevision : 6|3@1+ (1,0) [0.0|0.0] "" Vector__XXX
 SG_ ISOBUSCmplianceCertificationYear : 0|6@1+ (1,0) [0.0|0.0] "" Vector__XXX

BO_ 2566730494 TBD: 8 Vector__XXX

BO_ 2566718462 IOS: 8 Vector__XXX
 SG_ ImplementOperatingStateCmd : 56|2@1+ (1,0) [0.0|0.0] "" Vector__XXX

BO_ 2566718206 AISO: 8 Vector__XXX
 SG_ StpAllImplmntOprtnsTrnstonNumber : 48|8@1+ (1,0) [0.0|0.0] "" Vector__XXX
 SG_ AllImplmntStpOprtngOprtnsSwtchSt : 56|2@1+ (1,0) [0.0|0.0] "" Vector__XXX

BO_ 2566706430 XCP_ID: 8 Vector__XXX

BO_ 2566704894 DSC: 8 Vector__XXX

BO_ 2566704638 DSS: 8 Vector__XXX

BO_ 2566701566 TRF3: 8 Vector__XXX
 SG_ TransOilTransCoolerOutletTemp : 8|8@1+ (1,-40) [-40.0|210.0] "°C" Vector__XXX
 SG_ TransClutch2Press : 0|8@1+ (16,0) [0.0|4000.0] "kPa" Vector__XXX

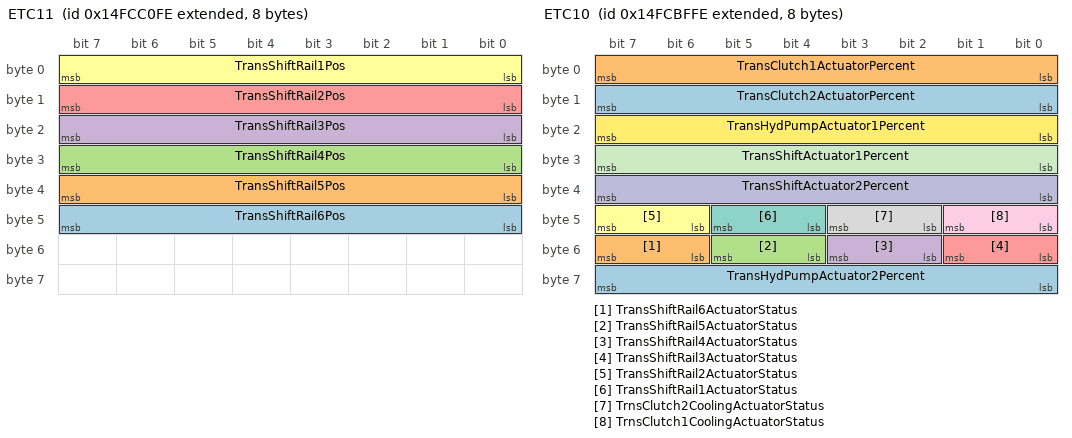
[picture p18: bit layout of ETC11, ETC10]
BO_ 2499592446 ETC11: 8 Vector__XXX
 SG_ TransShiftRail6Pos : 40|8@1+ (0.4,0) [0.0|100.0] "%" Vector__XXX
 SG_ TransShiftRail5Pos : 32|8@1+ (0.4,0) [0.0|100.0] "%" Vector__XXX
 SG_ TransShiftRail4Pos : 24|8@1+ (0.4,0) [0.0|100.0] "%" Vector__XXX
 SG_ TransShiftRail3Pos : 16|8@1+ (0.4,0) [0.0|100.0] "%" Vector__XXX
 SG_ TransShiftRail2Pos : 8|8@1+ (0.4,0) [0.0|100.0] "%" Vector__XXX
 SG_ TransShiftRail1Pos : 0|8@1+ (0.4,0) [0.0|100.0] "%" Vector__XXX

BO_ 2499592190 ETC10: 8 Vector__XXX
 SG_ TransHydPumpActuator2Percent : 56|8@1+ (0.4,0) [0.0|100.0] "%" Vector__XXX
 SG_ TransShiftRail6ActuatorStatus : 54|2@1+ (1,0) [0.0|3.0] "" Vector__XXX
 SG_ TransShiftRail5ActuatorStatus : 52|2@1+ (1,0) [0.0|3.0] "" Vector__XXX
 SG_ TransShiftRail4ActuatorStatus : 50|2@1+ (1,0) [0.0|3.0] "" Vector__XXX
 SG_ TransShiftRail3ActuatorStatus : 48|2@1+ (1,0) [0.0|3.0] "" Vector__XXX
 SG_ TransShiftRail2ActuatorStatus : 46|2@1+ (1,0) [0.0|3.0] "" Vector__XXX
 SG_ TransShiftRail1ActuatorStatus : 44|2@1+ (1,0) [0.0|3.0] "" Vector__XXX
 SG_ TrnsClutch2CoolingActuatorStatus : 42|2@1+ (1,0) [0.0|3.0] "" Vector__XXX
 SG_ TrnsClutch1CoolingActuatorStatus : 40|2@1+ (1,0) [0.0|3.0] "" Vector__XXX
 SG_ TransShiftActuator2Percent : 32|8@1+ (0.4,0) [0.0|100.0] "%" Vector__XXX
 SG_ TransShiftActuator1Percent : 24|8@1+ (0.4,0) [0.0|100.0] "%" Vector__XXX
 SG_ TransHydPumpActuator1Percent : 16|8@1+ (0.4,0) [0.0|100.0] "%" Vector__XXX
 SG_ TransClutch2ActuatorPercent : 8|8@1+ (0.4,0) [0.0|100.0] "%" Vector__XXX
 SG_ TransClutch1ActuatorPercent : 0|8@1+ (0.4,0) [0.0|100.0] "%" Vector__XXX

BO_ 2365374206 ETC9: 8 Vector__XXX
 SG_ DlCltchTrnsCrrntPreselectionGear : 40|8@1+ (1,-125) [-125.0|125.0] "" Vector__XXX
 SG_ DlCltchTrnsSlctdPreselectionGear : 32|8@1+ (1,-125) [-125.0|125.0] "" Vector__XXX
 SG_ DualClutchTransInputShaft2Speed : 16|16@1+ (0.125,0) [0.0|8031.875] "rpm" Vector__XXX
 SG_ DualClutchTransInputShaft1Speed : 0|16@1+ (0.125,0) [0.0|8031.875] "rpm" Vector__XXX

BO_ 2566700542 A1SCRSI2: 8 Vector__XXX
 SG_ TripDEF : 32|32@1+ (0.05,0) [0.0|210554060.75] "L" Vector__XXX
 SG_ TotalDEFUsed : 0|32@1+ (0.5,0) [0.0|2105540607.5] "L" Vector__XXX

BO_ 2566700286 A2SCRSI2: 8 Vector__XXX
 SG_ TotalDEFUsed : 0|32@1+ (0.5,0) [0.0|2105540607.5] "L" Vector__XXX

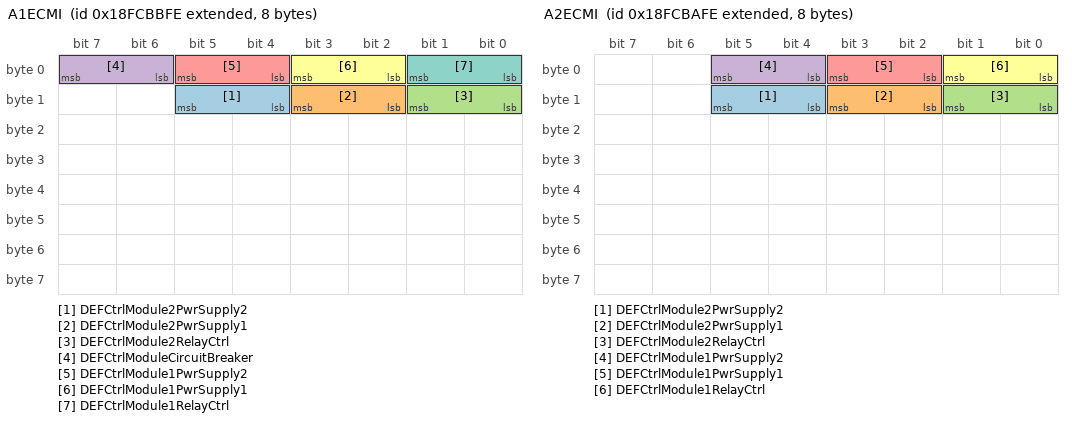
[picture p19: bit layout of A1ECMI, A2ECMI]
BO_ 2566700030 A1ECMI: 8 Vector__XXX
 SG_ DEFCtrlModule2PwrSupply2 : 12|2@1+ (1,0) [0.0|3.0] "" Vector__XXX
 SG_ DEFCtrlModule2PwrSupply1 : 10|2@1+ (1,0) [0.0|3.0] "" Vector__XXX
 SG_ DEFCtrlModule2RelayCtrl : 8|2@1+ (1,0) [0.0|3.0] "" Vector__XXX
 SG_ DEFCtrlModuleCircuitBreaker : 6|2@1+ (1,0) [0.0|3.0] "" Vector__XXX
 SG_ DEFCtrlModule1PwrSupply2 : 4|2@1+ (1,0) [0.0|3.0] "" Vector__XXX
 SG_ DEFCtrlModule1PwrSupply1 : 2|2@1+ (1,0) [0.0|3.0] "" Vector__XXX
 SG_ DEFCtrlModule1RelayCtrl : 0|2@1+ (1,0) [0.0|3.0] "" Vector__XXX

BO_ 2566699774 A2ECMI: 8 Vector__XXX
 SG_ DEFCtrlModule2PwrSupply2 : 12|2@1+ (1,0) [0.0|3.0] "" Vector__XXX
 SG_ DEFCtrlModule2PwrSupply1 : 10|2@1+ (1,0) [0.0|3.0] "" Vector__XXX
 SG_ DEFCtrlModule2RelayCtrl : 8|2@1+ (1,0) [0.0|3.0] "" Vector__XXX
 SG_ DEFCtrlModule1PwrSupply2 : 4|2@1+ (1,0) [0.0|3.0] "" Vector__XXX
 SG_ DEFCtrlModule1PwrSupply1 : 2|2@1+ (1,0) [0.0|3.0] "" Vector__XXX
 SG_ DEFCtrlModule1RelayCtrl : 0|2@1+ (1,0) [0.0|3.0] "" Vector__XXX

BO_ 2566699518 AT1S2: 8 Vector__XXX
 SG_ SCRSysTimeSinceLastSysCleanEvent : 32|32@1+ (1,0) [0.0|4211081215.0] "s" Vector__XXX
 SG_ DPFTimeToNextActiveRegen : 0|32@1+ (1,0) [0.0|4211081215.0] "s" Vector__XXX

BO_ 2566699262 AT2S2: 8 Vector__XXX
 SG_ SCRSysTimeSinceLastSysCleanEvent : 32|32@1+ (1,0) [0.0|4211081215.0] "s" Vector__XXX
 SG_ DPFTimeToNextActiveRegen : 0|32@1+ (1,0) [0.0|4211081215.0] "s" Vector__XXX

BO_ 2566698750 VEP5: 8 Vector__XXX
 SG_ SLICrnkngPrdctdMinBatteryVoltage : 40|8@1+ (0.2,0) [0.0|50.0] "V" Vector__XXX
 SG_ SLIBatteryPackHealth : 32|8@1+ (0.5,0) [0.0|100.0] "%" Vector__XXX
 SG_ SLIBatteryPackCapacity : 16|16@1+ (1,0) [0.0|64255.0] "Ah" Vector__XXX
 SG_ SLIBatteryPackStateOfCharge : 0|16@1+ (0.0025,0) [0.0|160.6375] "%" Vector__XXX

BO_ 2566698494 FPOS: 8 Vector__XXX
 SG_ FusedOutput29 : 62|2@1+ (1,0) [0.0|3.0] "" Vector__XXX
 SG_ FusedOutput30 : 60|2@1+ (1,0) [0.0|3.0] "" Vector__XXX
 SG_ FusedOutput31 : 58|2@1+ (1,0) [0.0|3.0] "" Vector__XXX
 SG_ FusedOutput32 : 56|2@1+ (1,0) [0.0|3.0] "" Vector__XXX
 SG_ FusedOutput25 : 54|2@1+ (1,0) [0.0|3.0] "" Vector__XXX
 SG_ FusedOutput26 : 52|2@1+ (1,0) [0.0|3.0] "" Vector__XXX
 SG_ FusedOutput27 : 50|2@1+ (1,0) [0.0|3.0] "" Vector__XXX
 SG_ FusedOutput28 : 48|2@1+ (1,0) [0.0|3.0] "" Vector__XXX
 SG_ FusedOutput21 : 46|2@1+ (1,0) [0.0|3.0] "" Vector__XXX
 SG_ FusedOutput22 : 44|2@1+ (1,0) [0.0|3.0] "" Vector__XXX
 SG_ FusedOutput23 : 42|2@1+ (1,0) [0.0|3.0] "" Vector__XXX
 SG_ FusedOutput24 : 40|2@1+ (1,0) [0.0|3.0] "" Vector__XXX
 SG_ FusedOutput17 : 38|2@1+ (1,0) [0.0|3.0] "" Vector__XXX
 SG_ FusedOutput18 : 36|2@1+ (1,0) [0.0|3.0] "" Vector__XXX
 SG_ FusedOutput19 : 34|2@1+ (1,0) [0.0|3.0] "" Vector__XXX
 SG_ FusedOutput20 : 32|2@1+ (1,0) [0.0|3.0] "" Vector__XXX
 SG_ FusedOutput13 : 30|2@1+ (1,0) [0.0|3.0] "" Vector__XXX
 SG_ FusedOutput14 : 27|2@1+ (1,0) [0.0|3.0] "" Vector__XXX
 SG_ FusedOutput15 : 26|2@1+ (1,0) [0.0|3.0] "" Vector__XXX
 SG_ FusedOutput16 : 24|2@1+ (1,0) [0.0|3.0] "" Vector__XXX
 SG_ FusedOutput9 : 22|2@1+ (1,0) [0.0|3.0] "" Vector__XXX
 SG_ FusedOutput10 : 20|2@1+ (1,0) [0.0|3.0] "" Vector__XXX
 SG_ FusedOutput11 : 18|2@1+ (1,0) [0.0|3.0] "" Vector__XXX
 SG_ FusedOutput12 : 16|2@1+ (1,0) [0.0|3.0] "" Vector__XXX
 SG_ FusedOutput5 : 14|2@1+ (1,0) [0.0|3.0] "" Vector__XXX
 SG_ FusedOutput6 : 12|2@1+ (1,0) [0.0|3.0] "" Vector__XXX
 SG_ FusedOutput7 : 10|2@1+ (1,0) [0.0|3.0] "" Vector__XXX
 SG_ FusedOutput8 : 8|2@1+ (1,0) [0.0|3.0] "" Vector__XXX
 SG_ FusedOutput1 : 6|2@1+ (1,0) [0.0|3.0] "" Vector__XXX
 SG_ FusedOutput2 : 4|2@1+ (1,0) [0.0|3.0] "" Vector__XXX
 SG_ FusedOutput3 : 2|2@1+ (1,0) [0.0|3.0] "" Vector__XXX
 SG_ FusedOutput4 : 0|2@1+ (1,0) [0.0|3.0] "" Vector__XXX

CM_ BO_ 2558590718  "Hybrid System Control 1
This messages is sent to the hybrid system to control hybrid related features.";
CM_ BO_ 2350776062  "Engine Ignition Controller - Commanded engine ignition timing advance";
CM_ BO_ 2350710526  "Transmission Control 3
This message is used to control the output speed and/or torque of a transmission.
For example, this message could be directed toward a continuously variable transmission (CVT) where output speed and torque are not directly ...";
CM_ BO_ 2582642430  "Proprietary A2
This proprietary PG uses the Destination Specific PDU Format allowing manufacturers to direct their proprietary communications to a specific destination node.";
CM_ BO_ 2566836734  "Oxygen Sensor Test Results
SAE J1939 will not specify an implementation for this DM.  Oxygen sensor test and results should be communicated using DM7 and DM8";
CM_ BO_ 2566801918  "Ground-based Speed and Distance
This message is normally sent by the Tractor ECU on the implement bus on construction and agricultural implements and provides to connected systems, the current measured ground speed.";
CM_ BO_ 2566801662  "Wheel-based Speed and Distance
This message is sent by the Tractor ECU on the implement bus on construction and agricultural implements and provides to connected systems, the current measured wheel-based speed.";
CM_ BO_ 2566801406  "Maintain Power
This message is sent by any ECU connected to the implement bus requesting that the Tractor ECU not switch off the power for the next 2 seconds.";
CM_ BO_ 2566801150  "Secondary or Front Hitch Status
This message provides the measurement of the current front hitch parameters.";
CM_ BO_ 2566800894  "Primary or Rear Hitch Status
This message provides the measurement of the current rear hitch parameters.";
CM_ BO_ 2566800638  "Secondary or Front Power Take off Output Shaft
This message provides the measurement of the current secondary or front PTO output shaft parameters.";
CM_ BO_ 2566800382  "Primary or Rear Power Take off Output Shaft
This message provides the measurement of the current primary or rear PTO output shaft parameters.";
CM_ BO_ 2566800126  "Hitch and PTO Commands
This message provides control of the hitch position, PTO shaft set point speed and PTO engagement.";
CM_ BO_ 2566799358  "Auxiliary Valve Number 15 Command
This message provides control of the flow through the auxiliary valves.";
CM_ BO_ 2566799102  "Auxiliary Valve Number 14 Command
This message provides control of the flow through the auxiliary valves.";
CM_ BO_ 2566798846  "Auxiliary Valve Number 13 Command
This message provides control of the flow through the auxiliary valves.";
CM_ BO_ 2566798590  "Auxiliary Valve Number 12 Command
This message provides control of the flow through the auxiliary valves.";
CM_ BO_ 2566798334  "Auxiliary Valve Number 11 Command
This message provides control of the flow through the auxiliary valves.";
CM_ BO_ 2566798078  "Auxiliary Valve Number 10 Command
This message provides control of the flow through the auxiliary valves.";
CM_ BO_ 2566797822  "Auxiliary Valve Number 9 Command
This message provides control of the flow through the auxiliary valves.";
CM_ BO_ 2566797566  "Auxiliary Valve Number 8 Command
This message provides control of the flow through the auxiliary valves.";
CM_ BO_ 2566797310  "Auxiliary Valve Number 7 Command
This message provides control of the flow through the auxiliary valves.";
CM_ BO_ 2566797054  "Auxiliary Valve Number 6 Command
This message provides control of the flow through the auxiliary valves.";
CM_ BO_ 2566796798  "Auxiliary Valve Number 5 Command
This message provides control of the flow through the auxiliary valves.";
CM_ BO_ 2566796542  "Auxiliary Valve Number 4 Command
This message provides control of the flow through the auxiliary valves.";
CM_ BO_ 2566796286  "Auxiliary Valve Number 3 Command
This message provides control of the flow through the auxiliary valves.";
CM_ BO_ 2566796030  "Auxiliary Valve Number 2 Command
This message provides control of the flow through the auxiliary valves.";
CM_ BO_ 2566795774  "Auxiliary Valve Number 1 Command
This message provides control of the flow through the auxiliary valves.";
CM_ BO_ 2566795518  "Auxiliary Valve Number 0 Command
This message provides control of the flow through the auxiliary valves.";
CM_ BO_ 2566795262  "Auxiliary Valve Number 15 Measured Flow
This message provides the measurement of specified auxiliary valve.";
CM_ BO_ 2566795006  "Auxiliary Valve Number 14 Measured Flow
This message provides the measurement of specified auxiliary valve.";
CM_ BO_ 2566794750  "Auxiliary Valve Number 13 Measured Flow
This message provides the measurement of specified auxiliary valve.";
CM_ BO_ 2566794494  "Auxiliary Valve Number 12 Measured Flow
This message provides the measurement of specified auxiliary valve.";
CM_ BO_ 2566794238  "Auxiliary Valve Number 11 Measured Flow
This message provides the measurement of specified auxiliary valve.";
CM_ BO_ 2566793982  "Auxiliary Valve Number 10 Measured Flow
This message provides the measurement of specified auxiliary valve.";
CM_ BO_ 2566793726  "Auxiliary Valve Number 9 Measured Flow
This message provides the measurement of specified auxiliary valve.";
CM_ BO_ 2566793470  "Auxiliary Valve Number 8 Measured Flow
This message provides the measurement of specified auxiliary valve.";
CM_ BO_ 2566793214  "Auxiliary Valve Number 7 Measured Flow
This message provides the measurement of specified auxiliary valve.";
CM_ BO_ 2566792958  "Auxiliary Valve Number 6 Measured Flow
This message provides the measurement of specified auxiliary valve.";
CM_ BO_ 2566792702  "Auxiliary Valve Number 5 Measured Flow
This message provides the measurement of specified auxiliary valve.";
CM_ BO_ 2566792446  "Auxiliary Valve Number 4 Measured Flow
This message provides the measurement of specified auxiliary valve.";
CM_ BO_ 2566792190  "Auxiliary Valve Number 3 Measured Flow
This message provides the measurement of specified auxiliary valve.";
CM_ BO_ 2566791934  "Auxiliary Valve Number 2 Measured Flow
This message provides the measurement of specified auxiliary valve.";
CM_ BO_ 2566791678  "Auxiliary Valve Number 1 Measured Flow
This message provides the measurement of specified auxiliary valve.";
CM_ BO_ 2566791422  "Auxiliary Valve Number 0 Measured Flow
This message provides the measurement of specified auxiliary valve.";
CM_ BO_ 2566791166  "Auxiliary Valve Number 15 Estimated Flow
This message provides the estimated flow of specified auxiliary valve.";
CM_ BO_ 2566790910  "Auxiliary Valve Number 14 Estimated Flow
This message provides the estimated flow of specified auxiliary valve.";
CM_ BO_ 2566790654  "Auxiliary Valve Number 13 Estimated Flow
This message provides the estimated flow of specified auxiliary valve.";
CM_ BO_ 2566790398  "Auxiliary Valve Number 12 Estimated Flow
This message provides the estimated flow of specified auxiliary valve.";
CM_ BO_ 2566790142  "Auxiliary Valve Number 11 Estimated Flow
This message provides the estimated flow of specified auxiliary valve.";
CM_ BO_ 2566789886  "Auxiliary Valve Number 10 Estimated Flow
This message provides the estimated flow of specified auxiliary valve.";
CM_ BO_ 2566789630  "Auxiliary Valve Number 9 Estimated Flow
This message provides the estimated flow of specified auxiliary valve.";
CM_ BO_ 2566789374  "Auxiliary Valve Number 8 Estimated Flow
This message provides the estimated flow of specified auxiliary valve.";
CM_ BO_ 2566789118  "Auxiliary Valve Number 7 Estimated Flow
This message provides the estimated flow of specified auxiliary valve.";
CM_ BO_ 2566788862  "Auxiliary Valve Number 6 Estimated Flow
This message provides the estimated flow of specified auxiliary valve.";
CM_ BO_ 2566788606  "Auxiliary Valve Number 5 Estimated Flow
This message provides the estimated flow of specified auxiliary valve.";
CM_ BO_ 2566788350  "Auxiliary Valve Number 4 Estimated Flow
This message provides the estimated flow of specified auxiliary valve.";
CM_ BO_ 2566788094  "Auxiliary Valve Number 3 Estimated Flow
This message provides the estimated flow of specified auxiliary valve.";
CM_ BO_ 2566787838  "Auxiliary Valve Number 2 Estimated Flow
This message provides the estimated flow of specified auxiliary valve.";
CM_ BO_ 2566787582  "Auxiliary Valve Number 1 Estimated Flow
This message provides the estimated flow of specified auxiliary valve.";
CM_ BO_ 2566787326  "Auxiliary Valve Number 0 Estimated Flow
This message provides the estimated flow of specified auxiliary valve.";
CM_ BO_ 2566787070  "Language Command
The language message has been defined as a global message to inform all ECUs on the 11783 bus the language that the operator wants to use, the date and time format and the units of measure with which the connected system should ...";
CM_ BO_ 2566786814  "Response for Repetition Rate
This global message is the response of the request of a specific user to change the repetition rate.";
CM_ BO_ 2566786046  "Implement Remote Control Command
This command is a task controller or an implement ECU to tractor ECU message.";
CM_ BO_ 2566785790  "Implement Remote Control Command Tractor Response
This command is a task controller or an implement ECU to tractor ECU message.";
CM_ BO_ 2566785534  "Tractor Facilities response message
Tractor response to an implement ECU or task controller tractor classification and facilities request";
CM_ BO_ 2566785278  "Required Tractor Facilities message
Implement response to task controller or Tractor ECU desired tractor classification and facilities";
CM_ BO_ 2566774526  "Military Application Message #2/1
Message to transmit data of the towed vehicle to the towing vehicle. See ISO 11992-3.";
CM_ BO_ 2566774270  "Military Application Message #1/1
Message to transmit data of the towing vehicle to the towed vehicle. See ISO 11992-3.";
CM_ BO_ 2566770686  "Working Set Master Message
Message sent by the Master of a Working Set to identify how many members  there are  in said set.";
CM_ BO_ 2566770430  "Working Set Member Message
Message sent by the Master of a Working Set to identify an individual member of a specific Working Set.";
CM_ BO_ 2566761470  "Request For Complete Configurable Message Set (no longer used)
This message is designed to cause all CAs to respond with the complete sequence of configuration identification messages for a particular one or all of the configurable messages that ...";
CM_ BO_ 2566754814  "AC Switching Device Status
This contains parameters indicating the status of various breakers throughout a power generation system.  These include: Generator Circuit Breaker Status, Utility Circuit Breaker Status, and Automatic Transfer Switch ...";
CM_ BO_ 2566754302  "Generator Total AC Percent Power
This PGN contains quantities for the instantaneous AC power from the generator, as percentages of rated power";
CM_ BO_ 2566754046  "Generator Total AC Reactive Energy
This PGN contains quantities for the cumulative AC reactive energy from the generator.";
CM_ BO_ 2566753790  "Utility Total AC Reactive Energy
This PGN contains quantities for the cumulative AC reactive energy from the utility.";
CM_ BO_ 2566738174  "General Purpose Message #1/9
Message to transmit data of the towing vehicle to the towed vehicle. See ISO 11992-3.";
CM_ BO_ 2566737918  "General Purpose Message #2/6
Message to transmit data of the towed vehicle to the towing vehicle. See ISO 11992-3.";
CM_ BO_ 2566737662  "General Purpose Message #2/7
Message to transmit data of the towed vehicle to the towing vehicle. See ISO 11992-3.";
CM_ BO_ 2566737406  "General Purpose Message #2/8
Message to transmit data of the towed vehicle to the towing vehicle. See ISO 11992-3.";
CM_ BO_ 2566737150  "General Purpose Message #2/9
Message to transmit data of the towed vehicle to the towing vehicle. See ISO 11992-3.";
CM_ BO_ 2566736894  "General Purpose Message #2/10
Message to transmit data of the towed vehicle to the towing vehicle. See ISO 11992-3.";
CM_ BO_ 2566736638  "General Purpose Message #2/11
Message to transmit data of the towed vehicle to the towing vehicle. See ISO 11992-3.";
CM_ BO_ 2566734846  "Machine Selected Speed Command
Message that provides the control of the machine speed and direction.";
CM_ BO_ 2566734590  "ISOBUS compliance certification
This message reports the compliance certification status of a specific electronic control unit.";
CM_ BO_ 2566730494  "Reserved for ISOBUS ECU diagnostic protocol
The ECU level 1 diagnostic protocol message identifies the diagnostic protocol required by a service tool to troubleshoot a fault.";
CM_ BO_ 2566718462  "Implement Operating State Command
Message sent by the tractor ECU on the implement bus on forestry or agriculture implements providing to connected systems the current commanded implement operating state.";
CM_ BO_ 2566718206  "All Implements Stop Operations Switch State
This message may be sent by any ECU connected to the implement bus on forestry or agriculture implements providing the current state of the 'all implements stop operations' switch to connected systems.";
CM_ BO_ 2566706430  "XCP Get Slave ID
Used by the XCP master (tool) to identify all XCP slaves on the network.";
CM_ BO_ 2566704894  "Drive Strategy Command
Message from to the tractor used to alter the powertrain DriveStrategy priority structure, which determines the balance between fuel economy/consumption and the torque reserve of the engine.";
CM_ BO_ 2566704638  "Drive Strategy Status
Message from the tractor to the implement showing the current status of the Drive Strategy priority structure, which indicates the priority of the multiple powertrain functions.";
CM_ BO_ 2566701566  "Transmission Fluids 3";
CM_ BO_ 2499592446  "Electronic Transmission Controller #11
Electronic Transmission Controller #11";
CM_ BO_ 2499592190  "Electronic Transmission Controller #10
Electronic Transmission Controller #10";
CM_ BO_ 2365374206  "Electronic Transmission Controller #9
Electronic Transmission Controller #9
Note:
Single input shaft transmissions should use SPN 161 (Transmission Input Shaft Speed).
Multiple input shaft transmissions should use SPN 5960 and 5961 (DCT Input ...";
CM_ BO_ 2566700542  "Aftertreatment 1 SCR Service Information 2
This message contains SCR service information for aftertreatment system 1 (or bank 1).";
CM_ BO_ 2566700286  "Aftertreatment 2 SCR Service Information 2
This message contains SCR service information for aftertreatment system 2 (or bank 2).";
CM_ BO_ 2566700030  "Aftertreatment 1 SCR Electronic Control Module Information
Information relating to SCR electronic control module of aftertreatment 1 (bank 1).";
CM_ BO_ 2566699774  "Aftertreatment 2 SCR Electronic Control Module Information
Information relating to SCR electronic control module of aftertreatment 2 (bank 2).";
CM_ BO_ 2566699518  "Aftertreatment 1 Service 2
This PGN contains information about the aftertreatment 1.";
CM_ BO_ 2566699262  "Aftertreatment 2 Service 2
This PGN contains information about the aftertreatment 2.";
CM_ BO_ 2566698750  "Vehicle Electrical Power #5
PGN containing vehicle electrical power information for the battery pack used for starting, lighting, and ignition.";
CM_ BO_ 2566698494  "Fused Power Output Status
Fused power output status is sent by the Power Distribution Module (PDM) to indicate the state of the PDM's fused outputs.
This message is sent once every second (1000ms) and on change of any fused power output status, ...";
CM_ SG_ 2558590718 ShutdownCmd "Indicates the Hybrid System Shutdown Request state.  The signal gives network controllers the ability to disable all hybrid system functionality including propulsion, regenerative braking, and hybrid powered accessories.  For electric hybrids, the ...";
CM_ SG_ 2558590718 PropulsionDisableReq "Indicates the Hybrid System Disable Request state.  The signal gives network controllers the ability to disable the propulsion aspect of hybrid system operation when this request is on.  However, hybrid powered accessories may be on and the engine ...";
CM_ SG_ 2558590718 HybrdSystmRgnrtvBrakingDisableRq "Indicates the hybrid system regenerative braking disable request state.  This signal gives network controllers the ability to disable all regenerative braking.  This is not the operator controlled switch that performs regenerative braking disable ...";
CM_ SG_ 2558590718 HybridSystemProtectionOverrideRq "Indicates the hybrid system protection override request state.  This request allows overriding of hybrid system protection
features and failure modes allowing hybrid systems to continue to operate, if possible. This is not the physical switch that ...";
CM_ SG_ 2350776062 EngTimingAdvance_7355 "Ignition timing as a command to the ignition control module.  Positive values command an increasingly advanced timing from TDC. The same timing applies to all cylinders. Use SPN 7356 - SPN 7379 for cylinder specific timing offsets from this timing.";
CM_ SG_ 2350710526 MessageChecksum_7042 "The message checksum is used to verify the signal path from the transmitting device to the receiving device.
The message checksum is calculated using the first 7 data bytes, the message counter and the bytes of the message identifier. It is ...";
CM_ SG_ 2350710526 TransReqTorqueOrTorqueLim_7040 "Parameter provided to the transmission in the torque/speed control message for controlling or limiting the output torque.
Note:  0% to 125% for (positive) powered torque requests, -125% to 0% for (negative) retarding torque requests.  Does not ...";
CM_ SG_ 2350710526 TransReqOutputShaftSpeed_7039 "Used to request output shaft speed of the transmission which has a output through a driveline to the wheels of a machine/vehicle.";
CM_ SG_ 2350710526 MessageCounter_7041 "The message counter is used to detect situations where the transmitting ECU malfunction repeats the same frame all the time.  The receiver of the information may use the counter parameter to detect this situation.
Note:  The initial value of the 4 ...";
CM_ SG_ 2350710526 TransOvCtrlModePriority_7038 "This field is used as an input to the transmission to determine the priority of the Override Control Mode received in the Torque/Speed Control message.  The default is 11 (Low priority).  It is not required to use the same priority during the entire ...";
CM_ SG_ 2350710526 TransOverrideCtrlMode_7037 "The override control mode defines the type of control mode used to control transmission operation.
00 = Override disabled - Disable any existing control commanded by the source of this command.
01 = Speed control - Control speed to the included ...";
CM_ SG_ 2566801918 GroundBasedDirection "A measured signal indicating either forward or reverse as the direction of travel.  When speed is zero, indicate the last travel direction until a different direction is detected.
00 Reverse
01 Forward
10 Error indication
11 Not available";
CM_ SG_ 2566801918 GroundBasedImplementDistance "Actual distance travelled by a machine based on measurements from a sensor such as RADAR.  When distance exceeds 4 211 081.215 m, the value should be reset to zero and incremented as additional distance accrues.";
CM_ SG_ 2566801918 GroundBasedImplementSpeed "Actual ground speed of a machine, measured by a sensor such as RADAR.";
CM_ SG_ 2566801662 KeySwitchNOTOFF "Indicates the Key Switch of the tractor or power unit is NOT in the Off position. This does not indicate unforeseen power interruption such as those caused by starting the engine or due to connector intermittents.
00 Key Switch Off
01 Key Switch ...";
CM_ SG_ 2566801662 WheelBasedDirection "A measured signal indicating either forward or reverse as the direction of travel.  When speed is zero, indicate the last travel direction until a different direction is detected or selected and engaged.
00 Reverse
01 Forward
10 Error indication
...";
CM_ SG_ 2566801662 MaxTimeOfTractorPower "The maximum time of remaining tractor or power unit supplied electrical power at the current load.";
CM_ SG_ 2566801662 WheelBasedDistance "The distance travelled by a machine as calculated from wheel or tail shaft speed.  When distance exceeds 4211081,215 m, the value should be reset to zero and incremented as additional distance accrues.";
CM_ SG_ 2566801662 WheelBasedSpeed "A value of the speed of a machine as calculated from the measured wheel or tail shaft speed.";
CM_ SG_ 2566801406 ImplementInWorkState "Indicates that an implement is connected to a tractor or power unit and is “in-work”.
00   Implement is “out of work”
01   Implement is “in-work”
10   Error indication
11   Not available";
CM_ SG_ 2566801406 ImplementTransportState "Indicates the transport state of an implement connected to a tractor or power unit.
00 Implement may Not be transported
01 Implement may be transported
10 Error indication
11 Not available";
CM_ SG_ 2566801406 ImplementParkState "Indicates the state of an implement where it may be disconnected from a tractor or power unit.
00 Implement may Not be disconnected
01 Implement may be disconnected
10 Error indication
11 Not available";
CM_ SG_ 2566801406 ImplementWorkState "Indicates that an implement is connected to a tractor or power unit and is ready for work
00 Implement is Not ready for field work
01 Implement is ready for field work
10 Error indication
11 Not available";
CM_ SG_ 2566801406 MaintainECUPower "Request to the Tractor ECU to maintain ECU_PWR power for the next 2 seconds.
00 No Further Requirement for ECU_PWR
01 Requirement for 2 more seconds of ECU_PWR
10 Reserved
11 Don’t Care";
CM_ SG_ 2566801406 MaintainAcuatorPower "Request to the Tractor ECU to maintain PWR power for the next 2 seconds.
00 No Further Requirement for PWR
01 Requirement for 2 more seconds of PWR
10 Reserved
11 Don’t Care";
CM_ SG_ 2566801150 FrontDraft "The apparent horizontal force applied to the front hitch by an implement.  A positive value indicates force applied to the tractor opposed to heading.";
CM_ SG_ 2566801150 FrontNominalLowerLinkForce "This measurement provides an indication of draft at the lower links of the front three point hitch. Nominal lower link force may be expected to be approximately linear with respect to draft and may be proportional to draft for a single hitch ...";
CM_ SG_ 2566801150 FrontHitchInworkIndication "A measured signal indicating that the front hitch is positioned below (in-work) or above (out-of-work) an adjustable switching threshold.
00 Hitch position is out-of-work
01 Hitch position is in-work
10 Error indication
11 Not available";
CM_ SG_ 2566801150 FrontHitchPos "The measured position of the front three-point-hitch.  Expressed as a percentage of full travel.  Zero percent indicates the full down position, and 100%, the full up position.";
CM_ SG_ 2566800894 RearHitchExit_reasonCode "This parameter indicates why the Rear Hitch cannot accept remote commands or has most recently stopped accepting remote commands.
0-No reason/all clear
1-Operator presence not detected
2-Implement released control of function
3-Operator override ...";
CM_ SG_ 2566800894 RearDraft "The apparent horizontal force applied to the rear hitch by an implement.  A positive value indicates force applied to the tractor opposed to heading.";
CM_ SG_ 2566800894 RearNominalLowerLinkForce "This measurement provides an indication of draft at the lower links of the rear three point hitch. Nominal lower link force may be expected to be approximately linear with respect to draft and may be proportional to draft for a single hitch ...";
CM_ SG_ 2566800894 RearHitchInworkIndication "A measured signal indicating that the rear hitch is positioned below (in-work) or above (out-of-work) an adjustable switching threshold.  The method of determining switching threshold is not standardise and will be determined by machine designers.
...";
CM_ SG_ 2566800894 RearHitchPos "The measured position of the rear three-point-hitch.  Expressed as a percentage of full travel.  Zero percent indicates the full down position, and 100%, the full up position.";
CM_ SG_ 2566800638 FrontPTOExit_reasonCode "This parameter indicates why the Front PTO cannot accept remote commands or has most recently stopped accepting remote commands.
0-No reason/all clear
1-Operator presence not detected
2-Implement released control of function
3-Operator override ...";
CM_ SG_ 2566800638 FrontHitchExit_reasonCode "This parameter indicates why the Front Hitch cannot accept remote commands or has most recently stopped accepting remote commands.
0-No reason/all clear
1-Operator presence not detected
2-Implement released control of function
3-Operator ...";
CM_ SG_ 2566800638 FrontPowerTakeOffEngagement "A measured signal indicating that the front power take off is engaged or disengage.
00 Power take off disengaged
01 Power take off engaged
10 Error indication
11 Not available";
CM_ SG_ 2566800638 FrontPowerTakeOffMode "A measured signal indicating that the front power take off mode is either 540 or 1000 rpm.
00 Power take off mode is 540
01 Power take off mode is 1000
10 Error indication
11 Not available";
CM_ SG_ 2566800638 FrontPowerTakeOffEconomyMode "A measured signal indicating that the front power take off economy mode is engaged or disengaged. Economy mode PTO operate at 540 or 1000 rpm at a lower engine rpm.
00 Power take off economy mode is disengaged
01 Power take off economy mode is ...";
CM_ SG_ 2566800638 FrontPTOOutputShaftSpeedSetPoint "The measured value of the set point of the rotational speed of the front power take off (PTO) output shaft.";
CM_ SG_ 2566800638 FrontPTOOutputShaftSpeed "The measured rotational speed of the front power take off (PTO) output shaft. For existing tractors that monitor PTO speed prior to the engagement clutch, the PTO speed would only be valid when PTO is engaged and not available when PTO disengaged.";
CM_ SG_ 2566800382 RearPTOExit_reasonCode "This parameter indicates why the Rear PTO cannot accept remote commands or has most recently stopped accepting remote commands.
0-No reason/all clear
1-Operator presence not detected
2-Implement released control of function
3-Operator override ...";
CM_ SG_ 2566800382 RearPowerTakeOffEngagement "A measured signal indicating that the rear power take off is engaged or disengage.
00 Power take off disengaged
01 Power take off engaged
10 Error indication
11 Not available";
CM_ SG_ 2566800382 RearPowerTakeOffMode "A measured signal indicating that the rear power take off mode is either 540 or 1000 rpm.
00 Power take off mode is 540
01 Power take off mode is 1000
10 Error indication
11 Not available";
CM_ SG_ 2566800382 RearPowerTakeOffEconomyMode "A measured signal indicating that the rear power take off economy mode is engaged or disengaged. Economy mode PTO operate at 540 or 1000 rpm at a lower engine rpm.
00 Power take off economy mode is disengaged
01 Power take off economy mode is ...";
CM_ SG_ 2566800382 RearPTOOutputShaftSpeedSetPoint "The measured value of the set point of the rotational speed of the rear power take off (PTO) output shaft.";
CM_ SG_ 2566800382 RearPTOOutputShaftSpeed "The measured rotational speed of the rear power take off (PTO) output shaft. For existing tractors that monitor PTO speed prior to the engagement clutch, the PTO speed would only be valid when PTO is engaged and not available when PTO disengaged.";
CM_ SG_ 2566800126 FrontPowerTakeOffModeCmd "The command to select the mode of the front power take off .
00 Select 540 rpm mode
01 Select 1000 rpm mode
10 Reserved
11 Don’t Care";
CM_ SG_ 2566800126 RearPowerTakeOffModeCmd "The command to select the mode of the rear power take off .
00 Select 540 rpm mode
01 Select 1000 rpm mode
10 Reserved
11 Don’t Care";
CM_ SG_ 2566800126 FrontPowerTakeOffEconomyModeCmd "The command to engage or disengage the front power take off‘s economy mode.
00 Disengage Power take off‘s economy mode
01 Engage Power take off‘s economy mode
10 Reserved
11 Don’t Care";
CM_ SG_ 2566800126 RearPowerTakeOffEconomyModeCmd "The command to engage or disengage the rear power take off‘s economy mode.
00 Disengage Power take off‘s economy mode
01 Engage Power take off‘s economy mode
10 Reserved
11 Don’t Care";
CM_ SG_ 2566800126 FrontPowerTakeOffEngagementCmd "The command to engage or disengage the front power take off .
00 Disengage Power take off
01 Engage Power take off
10 Reserved
11 Don’t Care";
CM_ SG_ 2566800126 RearPowerTakeOffEngagementCmd "The command to engage or disengage the rear power take off .
00 Disengage Power take off
01 Engage Power take off
10 Reserved
11 Don’t Care";
CM_ SG_ 2566800126 RrPTOOutputShaftSpeedSetPointCmd "The command to set the rotational speed of the rear power take off (PTO) output shaft.";
CM_ SG_ 2566800126 FrntPTOOtptShaftSpeedSetPointCmd "The command to set the rotational speed of the front power take off (PTO) output shaft.";
CM_ SG_ 2566800126 RearHitchPosCmd "Command to allow the position of the rear three-point-hitch to be set.  Expressed as a percentage of full travel.  Zero percent indicates the full down position, and 100%, the full up position.";
CM_ SG_ 2566800126 FrontHitchPosCmd "Command to allow the position of the front three-point-hitch to be set.  Expressed as a percentage of full travel.  Zero percent indicates the full down position, and 100%, the full up position.";
CM_ SG_ 2566799358 AuxValve15FailSafeModeCmd "Command for setting the fail safe mode of an auxiliary valve.
00 Block
01 Float
10 Reserved
11 Don’t Care";
CM_ SG_ 2566799358 AuxValve15StateCmd "Command for setting the auxiliary valve state.  With float enabled, hydraulic fluid may flow to or from the tractor as driven by the implement.
0000 Block
0001 Extend
0010 Retract
0011 Float
0100-1110 Reserved
1111 Don’t Care";
CM_ SG_ 2566799358 AuxValve15PortFlowCmd "The command to set the flow through the  extend or retract port of an auxiliary valve of a tractor, expressed as a percentage of full flow.  Zero percent indicates no flow, 100% indicates maximum flow, flow returns to the tractor through the ...";
CM_ SG_ 2566799102 AuxValve14FailSafeModeCmd "Command for setting the fail safe mode of an auxiliary valve.
00 Block
01 Float
10 Reserved
11 Don’t Care";
CM_ SG_ 2566799102 AuxValve14StateCmd "Command for setting the auxiliary valve state.  With float enabled, hydraulic fluid may flow to or from the tractor as driven by the implement.
0000 Block
0001 Extend
0010 Retract
0011 Float
0100-1110 Reserved
1111 Don’t Care";
CM_ SG_ 2566799102 AuxValve14PortFlowCmd "The command to set the flow through the  extend or retract port of an auxiliary valve of a tractor, expressed as a percentage of full flow.  Zero percent indicates no flow, 100% indicates maximum flow, flow returns to the tractor through the ...";
CM_ SG_ 2566798846 AuxValve13FailSafeModeCmd "Command for setting the fail safe mode of an auxiliary valve.
00 Block
01 Float
10 Reserved
11 Don’t Care";
CM_ SG_ 2566798846 AuxValve13StateCmd "Command for setting the auxiliary valve state.  With float enabled, hydraulic fluid may flow to or from the tractor as driven by the implement.
0000 Block
0001 Extend
0010 Retract
0011 Float
0100-1110 Reserved
1111 Don’t Care";
CM_ SG_ 2566798846 AuxValve13PortFlowCmd "The command to set the flow through the  extend or retract port of an auxiliary valve of a tractor, expressed as a percentage of full flow.  Zero percent indicates no flow, 100% indicates maximum flow, flow returns to the tractor through the ...";
CM_ SG_ 2566798590 AuxValve12FailSafeModeCmd "Command for setting the fail safe mode of an auxiliary valve.
00 Block
01 Float
10 Reserved
11 Don’t Care";
CM_ SG_ 2566798590 AuxValve12StateCmd "Command for setting the auxiliary valve state.  With float enabled, hydraulic fluid may flow to or from the tractor as driven by the implement.
0000 Block
0001 Extend
0010 Retract
0011 Float
0100-1110 Reserved
1111 Don’t Care";
CM_ SG_ 2566798590 AuxValve12PortFlowCmd "The command to set the flow through the  extend or retract port of an auxiliary valve of a tractor, expressed as a percentage of full flow.  Zero percent indicates no flow, 100% indicates maximum flow, flow returns to the tractor through the ...";
CM_ SG_ 2566798334 AuxValve11FailSafeModeCmd "Command for setting the fail safe mode of an auxiliary valve.
00 Block
01 Float
10 Reserved
11 Don’t Care";
CM_ SG_ 2566798334 AuxValve11StateCmd "Command for setting the auxiliary valve state.  With float enabled, hydraulic fluid may flow to or from the tractor as driven by the implement.
0000 Block
0001 Extend
0010 Retract
0011 Float
0100-1110 Reserved
1111 Don’t Care";
CM_ SG_ 2566798334 AuxValve11PortFlowCmd "The command to set the flow through the  extend or retract port of an auxiliary valve of a tractor, expressed as a percentage of full flow.  Zero percent indicates no flow, 100% indicates maximum flow, flow returns to the tractor through the ...";
CM_ SG_ 2566798078 AuxValve10FailSafeModeCmd "Command for setting the fail safe mode of an auxiliary valve.
00 Block
01 Float
10 Reserved
11 Don’t Care";
CM_ SG_ 2566798078 AuxValve10StateCmd "Command for setting the auxiliary valve state.  With float enabled, hydraulic fluid may flow to or from the tractor as driven by the implement.
0000 Block
0001 Extend
0010 Retract
0011 Float
0100-1110 Reserved
1111 Don’t Care";
CM_ SG_ 2566798078 AuxValve10PortFlowCmd "The command to set the flow through the  extend or retract port of an auxiliary valve of a tractor, expressed as a percentage of full flow.  Zero percent indicates no flow, 100% indicates maximum flow, flow returns to the tractor through the ...";
CM_ SG_ 2566797822 AuxValve9FailSafeModeCmd "Command for setting the fail safe mode of an auxiliary valve.
00 Block
01 Float
10 Reserved
11 Don’t Care";
CM_ SG_ 2566797822 AuxValve9StateCmd "Command for setting the auxiliary valve state.  With float enabled, hydraulic fluid may flow to or from the tractor as driven by the implement.
0000 Block
0001 Extend
0010 Retract
0011 Float
0100-1110 Reserved
1111 Don’t Care";
CM_ SG_ 2566797822 AuxValve9PortFlowCmd "The command to set the flow through the  extend or retract port of an auxiliary valve of a tractor, expressed as a percentage of full flow.  Zero percent indicates no flow, 100% indicates maximum flow, flow returns to the tractor through the ...";
CM_ SG_ 2566797566 AuxValve8FailSafeModeCmd "Command for setting the fail safe mode of an auxiliary valve.
00 Block
01 Float
10 Reserved
11 Don’t Care";
CM_ SG_ 2566797566 AuxValve8StateCmd "Command for setting the auxiliary valve state.  With float enabled, hydraulic fluid may flow to or from the tractor as driven by the implement.
0000 Block
0001 Extend
0010 Retract
0011 Float
0100-1110 Reserved
1111 Don’t Care";
CM_ SG_ 2566797566 AuxValve8PortFlowCmd "The command to set the flow through the  extend or retract port of an auxiliary valve of a tractor, expressed as a percentage of full flow.  Zero percent indicates no flow, 100% indicates maximum flow, flow returns to the tractor through the ...";
CM_ SG_ 2566797310 AuxValve7FailSafeModeCmd "Command for setting the fail safe mode of an auxiliary valve.
00 Block
01 Float
10 Reserved
11 Don’t Care";
CM_ SG_ 2566797310 AuxValve7StateCmd "Command for setting the auxiliary valve state.  With float enabled, hydraulic fluid may flow to or from the tractor as driven by the implement.
0000 Block
0001 Extend
0010 Retract
0011 Float
0100-1110 Reserved
1111 Don’t Care";
CM_ SG_ 2566797310 AuxValve7PortFlowCmd "The command to set the flow through the  extend or retract port of an auxiliary valve of a tractor, expressed as a percentage of full flow.  Zero percent indicates no flow, 100% indicates maximum flow, flow returns to the tractor through the ...";
CM_ SG_ 2566797054 AuxValve6FailSafeModeCmd "Command for setting the fail safe mode of an auxiliary valve.
00 Block
01 Float
10 Reserved
11 Don’t Care";
CM_ SG_ 2566797054 AuxValve6StateCmd "Command for setting the auxiliary valve state.  With float enabled, hydraulic fluid may flow to or from the tractor as driven by the implement.
0000 Block
0001 Extend
0010 Retract
0011 Float
0100-1110 Reserved
1111 Don’t Care";
CM_ SG_ 2566797054 AuxValve6PortFlowCmd "The command to set the flow through the  extend or retract port of an auxiliary valve of a tractor, expressed as a percentage of full flow.  Zero percent indicates no flow, 100% indicates maximum flow, flow returns to the tractor through the ...";
CM_ SG_ 2566796798 AuxValve5FailSafeModeCmd "Command for setting the fail safe mode of an auxiliary valve.
00 Block
01 Float
10 Reserved
11 Don’t Care";
CM_ SG_ 2566796798 AuxValve5StateCmd "Command for setting the auxiliary valve state.  With float enabled, hydraulic fluid may flow to or from the tractor as driven by the implement.
0000 Block
0001 Extend
0010 Retract
0011 Float
0100-1110 Reserved
1111 Don’t Care";
CM_ SG_ 2566796798 AuxValve5PortFlowCmd "The command to set the flow through the  extend or retract port of an auxiliary valve of a tractor, expressed as a percentage of full flow.  Zero percent indicates no flow, 100% indicates maximum flow, flow returns to the tractor through the ...";
CM_ SG_ 2566796542 AuxValve4FailSafeModeCmd "Command for setting the fail safe mode of an auxiliary valve.
00 Block
01 Float
10 Reserved
11 Don’t Care";
CM_ SG_ 2566796542 AuxValve4StateCmd "Command for setting the auxiliary valve state.  With float enabled, hydraulic fluid may flow to or from the tractor as driven by the implement.
0000 Block
0001 Extend
0010 Retract
0011 Float
0100-1110 Reserved
1111 Don’t Care";
CM_ SG_ 2566796542 AuxValve4PortFlowCmd "The command to set the flow through the  extend or retract port of an auxiliary valve of a tractor, expressed as a percentage of full flow.  Zero percent indicates no flow, 100% indicates maximum flow, flow returns to the tractor through the ...";
CM_ SG_ 2566796286 AuxValve3FailSafeModeCmd "Command for setting the fail safe mode of an auxiliary valve.
00 Block
01 Float
10 Reserved
11 Don’t Care";
CM_ SG_ 2566796286 AuxValve3StateCmd "Command for setting the auxiliary valve state.  With float enabled, hydraulic fluid may flow to or from the tractor as driven by the implement.
0000 Block
0001 Extend
0010 Retract
0011 Float
0100-1110 Reserved
1111 Don’t Care";
CM_ SG_ 2566796286 AuxValve3PortFlowCmd "The command to set the flow through the  extend or retract port of an auxiliary valve of a tractor, expressed as a percentage of full flow.  Zero percent indicates no flow, 100% indicates maximum flow, flow returns to the tractor through the ...";
CM_ SG_ 2566796030 AuxValve2FailSafeModeCmd "Command for setting the fail safe mode of an auxiliary valve.
00 Block
01 Float
10 Reserved
11 Don’t Care";
CM_ SG_ 2566796030 AuxValve2StateCmd "Command for setting the auxiliary valve state.  With float enabled, hydraulic fluid may flow to or from the tractor as driven by the implement.
0000 Block
0001 Extend
0010 Retract
0011 Float
0100-1110 Reserved
1111 Don’t Care";
CM_ SG_ 2566796030 AuxValve2PortFlowCmd "The command to set the flow through the  extend or retract port of an auxiliary valve of a tractor, expressed as a percentage of full flow.  Zero percent indicates no flow, 100% indicates maximum flow, flow returns to the tractor through the ...";
CM_ SG_ 2566795774 AuxValve1FailSafeModeCmd "Command for setting the fail safe mode of an auxiliary valve.
00 Block
01 Float
10 Reserved
11 Don’t Care";
CM_ SG_ 2566795774 AuxValve1StateCmd "Command for setting the auxiliary valve state.  With float enabled, hydraulic fluid may flow to or from the tractor as driven by the implement.
0000 Block
0001 Extend
0010 Retract
0011 Float
0100-1110 Reserved
1111 Don’t Care";
CM_ SG_ 2566795774 AuxValve1PortFlowCmd "The command to set the flow through the  extend or retract port of an auxiliary valve of a tractor, expressed as a percentage of full flow.  Zero percent indicates no flow, 100% indicates maximum flow, flow returns to the tractor through the ...";
CM_ SG_ 2566795518 AuxValve0FailSafeModeCmd "Command for setting the fail safe mode of an auxiliary valve.
00 Block
01 Float
10 Reserved
11 Don’t Care";
CM_ SG_ 2566795518 AuxValve0StateCmd "Command for setting the auxiliary valve state.  With float enabled, hydraulic fluid may flow to or from the tractor as driven by the implement.
0000 Block
0001 Extend
0010 Retract
0011 Float
0100-1110 Reserved
1111 Don’t Care";
CM_ SG_ 2566795518 AuxValve0PortFlowCmd "The command to set the flow through the  extend or retract port of an auxiliary valve of a tractor, expressed as a percentage of full flow.  Zero percent indicates no flow, 100% indicates maximum flow, flow returns to the tractor through the ...";
CM_ SG_ 2566795262 AuxValve15ReturnPortPress "The measured nominal pressure at the return port of an auxiliary valve of a tractor.";
CM_ SG_ 2566795262 AuxValve15RetractPortPress "The measured nominal pressure at the retract port of an auxiliary valve of a tractor.";
CM_ SG_ 2566795262 AuxValve15ExtendPortPress "The measured nominal pressure at the extend port of an auxiliary valve of a tractor.";
CM_ SG_ 2566795262 AxValve15RetractPortMeasuredFlow "The measured flow through the retract port of an auxiliary valve of a tractor, expressed as a percentage of full flow.  Zero percent indicates no flow, 100% indicates maximum flow, -100% indicates maximum flow returning to the tractor through the ...";
CM_ SG_ 2566795262 AuxValve15ExtendPortMeasuredFlow "The measured flow through the extend port of an auxiliary valve of a tractor, expressed as a percentage of full flow.  Zero percent indicates no flow, 100% indicates maximum flow, -100% indicates maximum flow returning to the tractor through the ...";
CM_ SG_ 2566795006 AuxValve14ReturnPortPress "The measured nominal pressure at the return port of an auxiliary valve of a tractor.";
CM_ SG_ 2566795006 AuxValve14RetractPortPress "The measured nominal pressure at the retract port of an auxiliary valve of a tractor.";
CM_ SG_ 2566795006 AuxValve14ExtendPortPress "The measured nominal pressure at the extend port of an auxiliary valve of a tractor.";
CM_ SG_ 2566795006 AxValve14RetractPortMeasuredFlow "The measured flow through the retract port of an auxiliary valve of a tractor, expressed as a percentage of full flow.  Zero percent indicates no flow, 100% indicates maximum flow, -100% indicates maximum flow returning to the tractor through the ...";
CM_ SG_ 2566795006 AuxValve14ExtendPortMeasuredFlow "The measured flow through the extend port of an auxiliary valve of a tractor, expressed as a percentage of full flow.  Zero percent indicates no flow, 100% indicates maximum flow, -100% indicates maximum flow returning to the tractor through the ...";
CM_ SG_ 2566794750 AuxValve13ReturnPortPress "The measured nominal pressure at the return port of an auxiliary valve of a tractor.";
CM_ SG_ 2566794750 AuxValve13RetractPortPress "The measured nominal pressure at the retract port of an auxiliary valve of a tractor.";
CM_ SG_ 2566794750 AuxValve13ExtendPortPress "The measured nominal pressure at the extend port of an auxiliary valve of a tractor.";
CM_ SG_ 2566794750 AxValve13RetractPortMeasuredFlow "The measured flow through the retract port of an auxiliary valve of a tractor, expressed as a percentage of full flow.  Zero percent indicates no flow, 100% indicates maximum flow, -100% indicates maximum flow returning to the tractor through the ...";
CM_ SG_ 2566794750 AuxValve13ExtendPortMeasuredFlow "The measured flow through the extend port of an auxiliary valve of a tractor, expressed as a percentage of full flow.  Zero percent indicates no flow, 100% indicates maximum flow, -100% indicates maximum flow returning to the tractor through the ...";
CM_ SG_ 2566794494 AuxValve12ReturnPortPress "The measured nominal pressure at the return port of an auxiliary valve of a tractor.";
CM_ SG_ 2566794494 AuxValve12RetractPortPress "The measured nominal pressure at the retract port of an auxiliary valve of a tractor.";
CM_ SG_ 2566794494 AuxValve12ExtendPortPress "The measured nominal pressure at the extend port of an auxiliary valve of a tractor.";
CM_ SG_ 2566794494 AxValve12RetractPortMeasuredFlow "The measured flow through the retract port of an auxiliary valve of a tractor, expressed as a percentage of full flow.  Zero percent indicates no flow, 100% indicates maximum flow, -100% indicates maximum flow returning to the tractor through the ...";
CM_ SG_ 2566794494 AuxValve12ExtendPortMeasuredFlow "The measured flow through the extend port of an auxiliary valve of a tractor, expressed as a percentage of full flow.  Zero percent indicates no flow, 100% indicates maximum flow, -100% indicates maximum flow returning to the tractor through the ...";
CM_ SG_ 2566794238 AuxValve11ReturnPortPress "The measured nominal pressure at the return port of an auxiliary valve of a tractor.";
CM_ SG_ 2566794238 AuxValve11RetractPortPress "The measured nominal pressure at the retract port of an auxiliary valve of a tractor.";
CM_ SG_ 2566794238 AuxValve11ExtendPortPress "The measured nominal pressure at the extend port of an auxiliary valve of a tractor.";
CM_ SG_ 2566794238 AxValve11RetractPortMeasuredFlow "The measured flow through the retract port of an auxiliary valve of a tractor, expressed as a percentage of full flow.  Zero percent indicates no flow, 100% indicates maximum flow, -100% indicates maximum flow returning to the tractor through the ...";
CM_ SG_ 2566794238 AuxValve11ExtendPortMeasuredFlow "The measured flow through the extend port of an auxiliary valve of a tractor, expressed as a percentage of full flow.  Zero percent indicates no flow, 100% indicates maximum flow, -100% indicates maximum flow returning to the tractor through the ...";
CM_ SG_ 2566793982 AuxValve10ReturnPortPress "The measured nominal pressure at the return port of an auxiliary valve of a tractor.";
CM_ SG_ 2566793982 AuxValve10RetractPortPress "The measured nominal pressure at the retract port of an auxiliary valve of a tractor.";
CM_ SG_ 2566793982 AuxValve10ExtendPortPress "The measured nominal pressure at the extend port of an auxiliary valve of a tractor.";
CM_ SG_ 2566793982 AxValve10RetractPortMeasuredFlow "The measured flow through the retract port of an auxiliary valve of a tractor, expressed as a percentage of full flow.  Zero percent indicates no flow, 100% indicates maximum flow, -100% indicates maximum flow returning to the tractor through the ...";
CM_ SG_ 2566793982 AuxValve10ExtendPortMeasuredFlow "The measured flow through the extend port of an auxiliary valve of a tractor, expressed as a percentage of full flow.  Zero percent indicates no flow, 100% indicates maximum flow, -100% indicates maximum flow returning to the tractor through the ...";
CM_ SG_ 2566793726 AuxValve9ReturnPortPress "The measured nominal pressure at the return port of an auxiliary valve of a tractor.";
CM_ SG_ 2566793726 AuxValve9RetractPortPress "The measured nominal pressure at the retract port of an auxiliary valve of a tractor.";
CM_ SG_ 2566793726 AuxValve9ExtendPortPress "The measured nominal pressure at the extend port of an auxiliary valve of a tractor.";
CM_ SG_ 2566793726 AuxValve9RetractPortMeasuredFlow "The measured flow through the retract port of an auxiliary valve of a tractor, expressed as a percentage of full flow.  Zero percent indicates no flow, 100% indicates maximum flow, -100% indicates maximum flow returning to the tractor through the ...";
CM_ SG_ 2566793726 AuxValve9ExtendPortMeasuredFlow "The measured flow through the extend port of an auxiliary valve of a tractor, expressed as a percentage of full flow.  Zero percent indicates no flow, 100% indicates maximum flow, -100% indicates maximum flow returning to the tractor through the ...";
CM_ SG_ 2566793470 AuxValve8ReturnPortPress "The measured nominal pressure at the return port of an auxiliary valve of a tractor.";
CM_ SG_ 2566793470 AuxValve8RetractPortPress "The measured nominal pressure at the retract port of an auxiliary valve of a tractor.";
CM_ SG_ 2566793470 AuxValve8ExtendPortPress "The measured nominal pressure at the extend port of an auxiliary valve of a tractor.";
CM_ SG_ 2566793470 AuxValve8RetractPortMeasuredFlow "The measured flow through the retract port of an auxiliary valve of a tractor, expressed as a percentage of full flow.  Zero percent indicates no flow, 100% indicates maximum flow, -100% indicates maximum flow returning to the tractor through the ...";
CM_ SG_ 2566793470 AuxValve8ExtendPortMeasuredFlow "The measured flow through the extend port of an auxiliary valve of a tractor, expressed as a percentage of full flow.  Zero percent indicates no flow, 100% indicates maximum flow, -100% indicates maximum flow returning to the tractor through the ...";
CM_ SG_ 2566793214 AuxValve7ReturnPortPress "The measured nominal pressure at the return port of an auxiliary valve of a tractor.";
CM_ SG_ 2566793214 AuxValve7RetractPortPress "The measured nominal pressure at the retract port of an auxiliary valve of a tractor.";
CM_ SG_ 2566793214 AuxValve7ExtendPortPress "The measured nominal pressure at the extend port of an auxiliary valve of a tractor.";
CM_ SG_ 2566793214 AuxValve7RetractPortMeasuredFlow "The measured flow through the retract port of an auxiliary valve of a tractor, expressed as a percentage of full flow.  Zero percent indicates no flow, 100% indicates maximum flow, -100% indicates maximum flow returning to the tractor through the ...";
CM_ SG_ 2566793214 AuxValve7ExtendPortMeasuredFlow "The measured flow through the extend port of an auxiliary valve of a tractor, expressed as a percentage of full flow.  Zero percent indicates no flow, 100% indicates maximum flow, -100% indicates maximum flow returning to the tractor through the ...";
CM_ SG_ 2566792958 AuxValve6ReturnPortPress "The measured nominal pressure at the return port of an auxiliary valve of a tractor.";
CM_ SG_ 2566792958 AuxValve6RetractPortPress "The measured nominal pressure at the retract port of an auxiliary valve of a tractor.";
CM_ SG_ 2566792958 AuxValve6ExtendPortPress "The measured nominal pressure at the extend port of an auxiliary valve of a tractor.";
CM_ SG_ 2566792958 AuxValve6RetractPortMeasuredFlow "The measured flow through the retract port of an auxiliary valve of a tractor, expressed as a percentage of full flow.  Zero percent indicates no flow, 100% indicates maximum flow, -100% indicates maximum flow returning to the tractor through the ...";
CM_ SG_ 2566792958 AuxValve6ExtendPortMeasuredFlow "The measured flow through the extend port of an auxiliary valve of a tractor, expressed as a percentage of full flow.  Zero percent indicates no flow, 100% indicates maximum flow, -100% indicates maximum flow returning to the tractor through the ...";
CM_ SG_ 2566792702 AuxValve5ReturnPortPress "The measured nominal pressure at the return port of an auxiliary valve of a tractor.";
CM_ SG_ 2566792702 AuxValve5RetractPortPress "The measured nominal pressure at the retract port of an auxiliary valve of a tractor.";
CM_ SG_ 2566792702 AuxValve5ExtendPortPress "The measured nominal pressure at the extend port of an auxiliary valve of a tractor.";
CM_ SG_ 2566792702 AuxValve5RetractPortMeasuredFlow "The measured flow through the retract port of an auxiliary valve of a tractor, expressed as a percentage of full flow.  Zero percent indicates no flow, 100% indicates maximum flow, -100% indicates maximum flow returning to the tractor through the ...";
CM_ SG_ 2566792702 AuxValve5ExtendPortMeasuredFlow "The measured flow through the extend port of an auxiliary valve of a tractor, expressed as a percentage of full flow.  Zero percent indicates no flow, 100% indicates maximum flow, -100% indicates maximum flow returning to the tractor through the ...";
CM_ SG_ 2566792446 AuxValve4ReturnPortPress "The measured nominal pressure at the return port of an auxiliary valve of a tractor.";
CM_ SG_ 2566792446 AuxValve4RetractPortPress "The measured nominal pressure at the retract port of an auxiliary valve of a tractor.";
CM_ SG_ 2566792446 AuxValve4ExtendPortPress "The measured nominal pressure at the extend port of an auxiliary valve of a tractor.";
CM_ SG_ 2566792446 AuxValve4RetractPortMeasuredFlow "The measured flow through the retract port of an auxiliary valve of a tractor, expressed as a percentage of full flow.  Zero percent indicates no flow, 100% indicates maximum flow, -100% indicates maximum flow returning to the tractor through the ...";
CM_ SG_ 2566792446 AuxValve4ExtendPortMeasuredFlow "The measured flow through the extend port of an auxiliary valve of a tractor, expressed as a percentage of full flow.  Zero percent indicates no flow, 100% indicates maximum flow, -100% indicates maximum flow returning to the tractor through the ...";
CM_ SG_ 2566792190 AuxValve3ReturnPortPress "The measured nominal pressure at the return port of an auxiliary valve of a tractor.";
CM_ SG_ 2566792190 AuxValve3RetractPortPress "The measured nominal pressure at the retract port of an auxiliary valve of a tractor.";
CM_ SG_ 2566792190 AuxValve3ExtendPortPress "The measured nominal pressure at the extend port of an auxiliary valve of a tractor.";
CM_ SG_ 2566792190 AuxValve3RetractPortMeasuredFlow "The measured flow through the retract port of an auxiliary valve of a tractor, expressed as a percentage of full flow.  Zero percent indicates no flow, 100% indicates maximum flow, -100% indicates maximum flow returning to the tractor through the ...";
CM_ SG_ 2566792190 AuxValve3ExtendPortMeasuredFlow "The measured flow through the extend port of an auxiliary valve of a tractor, expressed as a percentage of full flow.  Zero percent indicates no flow, 100% indicates maximum flow, -100% indicates maximum flow returning to the tractor through the ...";
CM_ SG_ 2566791934 AuxValve2ReturnPortPress "The measured nominal pressure at the return port of an auxiliary valve of a tractor.";
CM_ SG_ 2566791934 AuxValve2RetractPortPress "The measured nominal pressure at the retract port of an auxiliary valve of a tractor.";
CM_ SG_ 2566791934 AuxValve2ExtendPortPress "The measured nominal pressure at the extend port of an auxiliary valve of a tractor.";
CM_ SG_ 2566791934 AuxValve2RetractPortMeasuredFlow "The measured flow through the retract port of an auxiliary valve of a tractor, expressed as a percentage of full flow.  Zero percent indicates no flow, 100% indicates maximum flow, -100% indicates maximum flow returning to the tractor through the ...";
CM_ SG_ 2566791934 AuxValve2ExtendPortMeasuredFlow "The measured flow through the extend port of an auxiliary valve of a tractor, expressed as a percentage of full flow.  Zero percent indicates no flow, 100% indicates maximum flow, -100% indicates maximum flow returning to the tractor through the ...";
CM_ SG_ 2566791678 AuxValve1ReturnPortPress "The measured nominal pressure at the return port of an auxiliary valve of a tractor.";
CM_ SG_ 2566791678 AuxValve1RetractPortPress "The measured nominal pressure at the retract port of an auxiliary valve of a tractor.";
CM_ SG_ 2566791678 AuxValve1ExtendPortPress "The measured nominal pressure at the extend port of an auxiliary valve of a tractor.";
CM_ SG_ 2566791678 AuxValve1RetractPortMeasuredFlow "The measured flow through the retract port of an auxiliary valve of a tractor, expressed as a percentage of full flow.  Zero percent indicates no flow, 100% indicates maximum flow, -100% indicates maximum flow returning to the tractor through the ...";
CM_ SG_ 2566791678 AuxValve1ExtendPortMeasuredFlow "The measured flow through the extend port of an auxiliary valve of a tractor, expressed as a percentage of full flow.  Zero percent indicates no flow, 100% indicates maximum flow, -100% indicates maximum flow returning to the tractor through the ...";
CM_ SG_ 2566791422 AuxValve0ReturnPortPress "The measured nominal pressure at the return port of an auxiliary valve of a tractor.";
CM_ SG_ 2566791422 AuxValve0RetractPortPress "The measured nominal pressure at the retract port of an auxiliary valve of a tractor.";
CM_ SG_ 2566791422 AuxValve0ExtendPortPress "The measured nominal pressure at the extend port of an auxiliary valve of a tractor.";
CM_ SG_ 2566791422 AuxValve0RetractPortMeasuredFlow "The measured flow through the retract port of an auxiliary valve of a tractor, expressed as a percentage of full flow.  Zero percent indicates no flow, 100% indicates maximum flow, -100% indicates maximum flow returning to the tractor through the ...";
CM_ SG_ 2566791422 AuxValve0ExtendPortMeasuredFlow "The measured flow through the extend port of an auxiliary valve of a tractor, expressed as a percentage of full flow.  Zero percent indicates no flow, 100% indicates maximum flow, -100% indicates maximum flow returning to the tractor through the ...";
CM_ SG_ 2566791166 AuxValve15Exit_reasonCode "This parameter indicates why the Auxiliary Valve 15 cannot accept remote commands or has most recently stopped accepting remote commands.
0-No reason/all clear
1-Operator presence not detected
2-Implement released control of function
3-Operator ...";
CM_ SG_ 2566791166 AuxValve15FailSafeMode "The measured state the fail safe mode of an auxiliary valve.
00 Block
01 Float
10 Error
11 Not available";
CM_ SG_ 2566791166 AuxValve15State "The measured state of the auxiliary valve.   With float enabled, hydraulic fluid may flow to or from the tractor as driven by the implement.
0000 Blocked
0001 Extend
0010 Retract
0011 Floating
0100-1110 Reserved
1111 Don’t Care";
CM_ SG_ 2566791166 AuxValve15RetractPortEstFlow "The value reported by the controller of flow through the retract port of an auxiliary valve of a tractor which could be based on the commanded position of the valve.  Zero percent indicates no flow, 100%, maximum flow, -100% maximum flow returning ...";
CM_ SG_ 2566791166 AuxValve15ExtendPortEstFlow "The value reported by the controller of flow through the extend port of an auxiliary valve of a tractor which could be based on the commanded position of the valve.  Zero percent indicates no flow, 100%, maximum flow, -100% maximum flow returning to ...";
CM_ SG_ 2566790910 AuxValve14Exit_reasonCode "This parameter indicates why the Auxiliary Valve 14 cannot accept remote commands or has most recently stopped accepting remote commands.
0-No reason/all clear
1-Operator presence not detected
2-Implement released control of function
3-Operator ...";
CM_ SG_ 2566790910 AuxValve14FailSafeMode "The measured state the fail safe mode of an auxiliary valve.
00 Block
01 Float
10 Error indication
11 Not available";
CM_ SG_ 2566790910 AuxValve14State "The measured state of the auxiliary valve.   With float enabled, hydraulic fluid may flow to or from the tractor as driven by the implement.
0000 Blocked
0001 Extend
0010 Retract
0011 Floating
0100-1110 Reserved
1111 Don’t Care";
CM_ SG_ 2566790910 AuxValve14RetractPortEstFlow "The value reported by the controller of flow through the retract port of an auxiliary valve of a tractor which could be based on the commanded position of the valve.  Zero percent indicates no flow, 100%, maximum flow, -100% maximum flow returning ...";
CM_ SG_ 2566790910 AuxValve14ExtendPortEstFlow "The value reported by the controller of flow through the extend port of an auxiliary valve of a tractor which could be based on the commanded position of the valve.  Zero percent indicates no flow, 100%, maximum flow, -100% maximum flow returning to ...";
CM_ SG_ 2566790654 AuxValve13Exit_reasonCode "This parameter indicates why the Auxiliary Valve 13 cannot accept remote commands or has most recently stopped accepting remote commands.
0-No reason/all clear
1-Operator presence not detected
2-Implement released control of function
3-Operator ...";
CM_ SG_ 2566790654 AuxValve13FailSafeMode "The measured state the fail safe mode of an auxiliary valve.
00 Block
01 Float
10 Error indication
11 Not available";
CM_ SG_ 2566790654 AuxValve13State "The measured state of the auxiliary valve.   With float enabled, hydraulic fluid may flow to or from the tractor as driven by the implement.
0000 Blocked
0001 Extend
0010 Retract
0011 Floating
0100-1110 Reserved
1111 Don’t Care";
CM_ SG_ 2566790654 AuxValve13RetractPortEstFlow "The value reported by the controller of flow through the retract port of an auxiliary valve of a tractor which could be based on the commanded position of the valve.  Zero percent indicates no flow, 100%, maximum flow, -100% maximum flow returning ...";
CM_ SG_ 2566790654 AuxValve13ExtendPortEstFlow "The value reported by the controller of flow through the extend port of an auxiliary valve of a tractor which could be based on the commanded position of the valve.  Zero percent indicates no flow, 100%, maximum flow, -100% maximum flow returning to ...";
CM_ SG_ 2566790398 AuxValve12Exit_reasonCode "This parameter indicates why the Auxiliary Valve 12 cannot accept remote commands or has most recently stopped accepting remote commands.
0-No reason/all clear
1-Operator presence not detected
2-Implement released control of function
3-Operator ...";
CM_ SG_ 2566790398 AuxValve12FailSafeMode "The measured state the fail safe mode of an auxiliary valve.
00 Block
01 Float
10 Error indication
11 Not available";
CM_ SG_ 2566790398 AuxValve12State "The measured state of the auxiliary valve.   With float enabled, hydraulic fluid may flow to or from the tractor as driven by the implement.
0000 Blocked
0001 Extend
0010 Retract
0011 Floating
0100-1110 Reserved
1111 Don’t Care";
CM_ SG_ 2566790398 AuxValve12RetractPortEstFlow "The value reported by the controller of flow through the retract port of an auxiliary valve of a tractor which could be based on the commanded position of the valve.  Zero percent indicates no flow, 100%, maximum flow, -100% maximum flow returning ...";
CM_ SG_ 2566790398 AuxValve12ExtendPortEstFlow "The value reported by the controller of flow through the extend port of an auxiliary valve of a tractor which could be based on the commanded position of the valve.  Zero percent indicates no flow, 100%, maximum flow, -100% maximum flow returning to ...";
CM_ SG_ 2566790142 AuxValve11Exit_reasonCode "This parameter indicates why the Auxiliary Valve 11 cannot accept remote commands or has most recently stopped accepting remote commands.
0-No reason/all clear
1-Operator presence not detected
2-Implement released control of function
3-Operator ...";
CM_ SG_ 2566790142 AuxValve11FailSafeMode "The measured state the fail safe mode of an auxiliary valve.
00 Block
01 Float
10 Error indication
11 Not available";
CM_ SG_ 2566790142 AuxValve11State "The measured state of the auxiliary valve.   With float enabled, hydraulic fluid may flow to or from the tractor as driven by the implement.
0000 Blocked
0001 Extend
0010 Retract
0011 Floating
0100-1110 Reserved
1111 Don’t Care";
CM_ SG_ 2566790142 AuxValve11RetractPortEstFlow "The value reported by the controller of flow through the retract port of an auxiliary valve of a tractor which could be based on the commanded position of the valve.  Zero percent indicates no flow, 100%, maximum flow, -100% maximum flow returning ...";
CM_ SG_ 2566790142 AuxValve11ExtendPortEstFlow "The value reported by the controller of flow through the extend port of an auxiliary valve of a tractor which could be based on the commanded position of the valve.  Zero percent indicates no flow, 100%, maximum flow, -100% maximum flow returning to ...";
CM_ SG_ 2566789886 AuxValve10Exit_reasonCode "This parameter indicates why the Auxiliary Valve 10 cannot accept remote commands or has most recently stopped accepting remote commands.
0-No reason/all clear
1-Operator presence not detected
2-Implement released control of function
3-Operator ...";
CM_ SG_ 2566789886 AuxValve10FailSafeMode "The measured state the fail safe mode of an auxiliary valve.
00 Block
01 Float
10 Error indication
11 Not available";
CM_ SG_ 2566789886 AuxValve10State "The measured state of the auxiliary valve.   With float enabled, hydraulic fluid may flow to or from the tractor as driven by the implement.
0000 Blocked
0001 Extend
0010 Retract
0011 Floating
0100-1110 Reserved
1111 Don’t Care";
CM_ SG_ 2566789886 AuxValve10RetractPortEstFlow "The value reported by the controller of flow through the retract port of an auxiliary valve of a tractor which could be based on the commanded position of the valve.  Zero percent indicates no flow, 100%, maximum flow, -100% maximum flow returning ...";
CM_ SG_ 2566789886 AuxValve10ExtendPortEstFlow "The value reported by the controller of flow through the extend port of an auxiliary valve of a tractor which could be based on the commanded position of the valve.  Zero percent indicates no flow, 100%, maximum flow, -100% maximum flow returning to ...";
CM_ SG_ 2566789630 AuxValve9Exit_reasonCode "This parameter indicates why the Auxiliary Valve 9 cannot accept remote commands or has most recently stopped accepting remote commands.
0-No reason/all clear
1-Operator presence not detected
2-Implement released control of function
3-Operator ...";
CM_ SG_ 2566789630 AuxValve9FailSafeMode "The measured state the fail safe mode of an auxiliary valve.
00 Block
01 Float
10 Error indication
11 Not available";
CM_ SG_ 2566789630 AuxValve9State "The measured state of the auxiliary valve.   With float enabled, hydraulic fluid may flow to or from the tractor as driven by the implement.
0000 Blocked
0001 Extend
0010 Retract
0011 Floating
0100-1110 Reserved
1111 Don’t Care";
CM_ SG_ 2566789630 AuxValve9RetractPortEstFlow "The value reported by the controller of flow through the retract port of an auxiliary valve of a tractor which could be based on the commanded position of the valve.  Zero percent indicates no flow, 100%, maximum flow, -100% maximum flow returning ...";
CM_ SG_ 2566789630 AuxValve9ExtendPortEstFlow "The value reported by the controller of flow through the extend port of an auxiliary valve of a tractor which could be based on the commanded position of the valve.  Zero percent indicates no flow, 100%, maximum flow, -100% maximum flow returning to ...";
CM_ SG_ 2566789374 AuxValve8Exit_reasonCode "This parameter indicates why the Auxiliary Valve 8 cannot accept remote commands or has most recently stopped accepting remote commands.
0-No reason/all clear
1-Operator presence not detected
2-Implement released control of function
3-Operator ...";
CM_ SG_ 2566789374 AuxValve8FailSafeMode "The measured state the fail safe mode of an auxiliary valve.
00 Block
01 Float
10 Error indication
11 Not available";
CM_ SG_ 2566789374 AuxValve8State "The measured state of the auxiliary valve.   With float enabled, hydraulic fluid may flow to or from the tractor as driven by the implement.
0000 Blocked
0001 Extend
0010 Retract
0011 Floating
0100-1110 Reserved
1111 Don’t Care";
CM_ SG_ 2566789374 AuxValve8RetractPortEstFlow "The value reported by the controller of flow through the retract port of an auxiliary valve of a tractor which could be based on the commanded position of the valve.  Zero percent indicates no flow, 100%, maximum flow, -100% maximum flow returning ...";
CM_ SG_ 2566789374 AuxValve8ExtendPortEstFlow "The value reported by the controller of flow through the extend port of an auxiliary valve of a tractor which could be based on the commanded position of the valve.  Zero percent indicates no flow, 100%, maximum flow, -100% maximum flow returning to ...";
CM_ SG_ 2566789118 AuxValve7Exit_reasonCode "This parameter indicates why the Auxiliary Valve 7 cannot accept remote commands or has most recently stopped accepting remote commands.
0-No reason/all clear
1-Operator presence not detected
2-Implement released control of function
3-Operator ...";
CM_ SG_ 2566789118 AuxValve7FailSafeMode "The measured state the fail safe mode of an auxiliary valve.
00 Block
01 Float
10 Error indication
11 Not available";
CM_ SG_ 2566789118 AuxValve7State "The measured state of the auxiliary valve.   With float enabled, hydraulic fluid may flow to or from the tractor as driven by the implement.
0000 Blocked
0001 Extend
0010 Retract
0011 Floating
0100-1110 Reserved
1111 Don’t Care";
CM_ SG_ 2566789118 AuxValve7RetractPortEstFlow "The value reported by the controller of flow through the retract port of an auxiliary valve of a tractor which could be based on the commanded position of the valve.  Zero percent indicates no flow, 100%, maximum flow, -100% maximum flow returning ...";
CM_ SG_ 2566789118 AuxValve7ExtendPortEstFlow "The value reported by the controller of flow through the extend port of an auxiliary valve of a tractor which could be based on the commanded position of the valve.  Zero percent indicates no flow, 100%, maximum flow, -100% maximum flow returning to ...";
CM_ SG_ 2566788862 AuxValve6Exit_reasonCode "This parameter indicates why the Auxiliary Valve 6 cannot accept remote commands or has most recently stopped accepting remote commands.
0-No reason/all clear
1-Operator presence not detected
2-Implement released control of function
3-Operator ...";
CM_ SG_ 2566788862 AuxValve6FailSafeMode "The measured state the fail safe mode of an auxiliary valve.
00 Block
01 Float
10 Error indication
11 Not available";
CM_ SG_ 2566788862 AuxValve6State "The measured state of the auxiliary valve.   With float enabled, hydraulic fluid may flow to or from the tractor as driven by the implement.
0000 Blocked
0001 Extend
0010 Retract
0011 Floating
0100-1110 Reserved
1111 Don’t Care";
CM_ SG_ 2566788862 AuxValve6RetractPortEstFlow "The value reported by the controller of flow through the retract port of an auxiliary valve of a tractor which could be based on the commanded position of the valve.  Zero percent indicates no flow, 100%, maximum flow, -100% maximum flow returning ...";
CM_ SG_ 2566788862 AuxValve6ExtendPortEstFlow "The value reported by the controller of flow through the extend port of an auxiliary valve of a tractor which could be based on the commanded position of the valve.  Zero percent indicates no flow, 100%, maximum flow, -100% maximum flow returning to ...";
CM_ SG_ 2566788606 AuxValve5Exit_reasonCode "This parameter indicates why the Auxiliary Valve 5 cannot accept remote commands or has most recently stopped accepting remote commands.
0-No reason/all clear
1-Operator presence not detected
2-Implement released control of function
3-Operator ...";
CM_ SG_ 2566788606 AuxValve5FailSafeMode "The measured state the fail safe mode of an auxiliary valve.
00 Block
01 Float
10 Error indication
11 Not available";
CM_ SG_ 2566788606 AuxValve5State "The measured state of the auxiliary valve.   With float enabled, hydraulic fluid may flow to or from the tractor as driven by the implement.
0000 Blocked
0001 Extend
0010 Retract
0011 Floating
0100-1110 Reserved
1111 Don’t Care";
CM_ SG_ 2566788606 AuxValve5RetractPortEstFlow "The value reported by the controller of flow through the retract port of an auxiliary valve of a tractor which could be based on the commanded position of the valve.  Zero percent indicates no flow, 100%, maximum flow, -100% maximum flow returning ...";
CM_ SG_ 2566788606 AuxValve5ExtendPortEstFlow "The value reported by the controller of flow through the extend port of an auxiliary valve of a tractor which could be based on the commanded position of the valve.  Zero percent indicates no flow, 100%, maximum flow, -100% maximum flow returning to ...";
CM_ SG_ 2566788350 AuxValve4Exit_reasonCode "This parameter indicates why the Auxiliary Valve 4 cannot accept remote commands or has most recently stopped accepting remote commands.
0-No reason/all clear
1-Operator presence not detected
2-Implement released control of function
3-Operator ...";
CM_ SG_ 2566788350 AuxValve4FailSafeMode "The measured state the fail safe mode of an auxiliary valve.
00 Block
01 Float
10 Error indication
11 Not available";
CM_ SG_ 2566788350 AuxValve4State "The measured state of the auxiliary valve.   With float enabled, hydraulic fluid may flow to or from the tractor as driven by the implement.
0000 Blocked
0001 Extend
0010 Retract
0011 Floating
0100-1110 Reserved
1111 Don’t Care";
CM_ SG_ 2566788350 AuxValve4RetractPortEstFlow "The value reported by the controller of flow through the retract port of an auxiliary valve of a tractor which could be based on the commanded position of the valve.  Zero percent indicates no flow, 100%, maximum flow, -100% maximum flow returning ...";
CM_ SG_ 2566788350 AuxValve4ExtendPortEstFlow "The value reported by the controller of flow through the extend port of an auxiliary valve of a tractor which could be based on the commanded position of the valve.  Zero percent indicates no flow, 100%, maximum flow, -100% maximum flow returning to ...";
CM_ SG_ 2566788094 AuxValve3Exit_reasonCode "This parameter indicates why the Auxiliary Valve 3 cannot accept remote commands or has most recently stopped accepting remote commands.
0-No reason/all clear
1-Operator presence not detected
2-Implement released control of function
3-Operator ...";
CM_ SG_ 2566788094 AuxValve3FailSafeMode "The measured state the fail safe mode of an auxiliary valve.
00 Block
01 Float
10 Error indication
11 Not available";
CM_ SG_ 2566788094 AuxValve3State "The measured state of the auxiliary valve.   With float enabled, hydraulic fluid may flow to or from the tractor as driven by the implement.
0000 Blocked
0001 Extend
0010 Retract
0011 Floating
0100-1110 Reserved
1111 Don’t Care";
CM_ SG_ 2566788094 AuxValve3RetractPortEstFlow "The value reported by the controller of flow through the retract port of an auxiliary valve of a tractor which could be based on the commanded position of the valve.  Zero percent indicates no flow, 100%, maximum flow, -100% maximum flow returning ...";
CM_ SG_ 2566788094 AuxValve3ExtendPortEstFlow "The value reported by the controller of flow through the extend port of an auxiliary valve of a tractor which could be based on the commanded position of the valve.  Zero percent indicates no flow, 100%, maximum flow, -100% maximum flow returning to ...";
CM_ SG_ 2566787838 AuxValve2Exit_reasonCode "This parameter indicates why the Auxiliary Valve 2 cannot accept remote commands or has most recently stopped accepting remote commands.
0-No reason/all clear
1-Operator presence not detected
2-Implement released control of function
3-Operator ...";
CM_ SG_ 2566787838 AuxValve2FailSafeMode "The measured state the fail safe mode of an auxiliary valve.
00 Block
01 Float
10 Error indication
11 Not available";
CM_ SG_ 2566787838 AuxValve2State "The measured state of the auxiliary valve.   With float enabled, hydraulic fluid may flow to or from the tractor as driven by the implement.
0000 Blocked
0001 Extend
0010 Retract
0011 Floating
0100-1110 Reserved
1111 Don’t Care";
CM_ SG_ 2566787838 AuxValve2RetractPortEstFlow "The value reported by the controller of flow through the retract port of an auxiliary valve of a tractor which could be based on the commanded position of the valve.  Zero percent indicates no flow, 100%, maximum flow, -100% maximum flow returning ...";
CM_ SG_ 2566787838 AuxValve2ExtendPortEstFlow "The value reported by the controller of flow through the extend port of an auxiliary valve of a tractor which could be based on the commanded position of the valve.  Zero percent indicates no flow, 100%, maximum flow, -100% maximum flow returning to ...";
CM_ SG_ 2566787582 AuxValve1Exit_reasonCode "This parameter indicates why the Auxiliary Valve 1 cannot accept remote commands or has most recently stopped accepting remote commands.
0-No reason/all clear
1-Operator presence not detected
2-Implement released control of function
3-Operator ...";
CM_ SG_ 2566787582 AuxValve1FailSafeMode "The measured state the fail safe mode of an auxiliary valve.
00 Block
01 Float
10 Error indication
11 Not available";
CM_ SG_ 2566787582 AuxValve1State "The measured state of the auxiliary valve.   With float enabled, hydraulic fluid may flow to or from the tractor as driven by the implement.
0000 Blocked
0001 Extend
0010 Retract
0011 Floating
0100-1110 Reserved
1111 Don’t Care";
CM_ SG_ 2566787582 AuxValve1RetractPortEstFlow "The value reported by the controller of flow through the retract port of an auxiliary valve of a tractor which could be based on the commanded position of the valve.  Zero percent indicates no flow, 100%, maximum flow, -100% maximum flow returning ...";
CM_ SG_ 2566787582 AuxValve1ExtendPortEstFlow "The value reported by the controller of flow through the extend port of an auxiliary valve of a tractor which could be based on the commanded position of the valve.  Zero percent indicates no flow, 100%, maximum flow, -100% maximum flow returning to ...";
CM_ SG_ 2566787326 AuxValve0Exit_reasonCode "This parameter indicates why the Auxiliary Valve 0 cannot accept remote commands or has most recently stopped accepting remote commands.
0-No reason/all clear
1-Operator presence not detected
2-Implement released control of function
3-Operator ...";
CM_ SG_ 2566787326 AuxValve0FailSafeMode "The measured state the fail safe mode of an auxiliary valve.
00 Block
01 Float
10 Error indication
11 Not available";
CM_ SG_ 2566787326 AuxValve0State "The measured state of the auxiliary valve.   With float enabled, hydraulic fluid may flow to or from the tractor as driven by the implement.
0000 Blocked
0001 Extend
0010 Retract
0011 Floating
0100-1110 Reserved
1111 Don’t Care";
CM_ SG_ 2566787326 AuxValve0RetractPortEstFlow "The value reported by the controller of flow through the retract port of an auxiliary valve of a tractor which could be based on the commanded position of the valve.  Zero percent indicates no flow, 100%, maximum flow, -100% maximum flow returning ...";
CM_ SG_ 2566787326 AuxValve0ExtendPortEstFlow "The value reported by the controller of flow through the extend port of an auxiliary valve of a tractor which could be based on the commanded position of the valve.  Zero percent indicates no flow, 100%, maximum flow, -100% maximum flow returning to ...";
CM_ SG_ 2566787070 DistanceUnitCmd "Command to specify the distance units
00 Metric (km, m, …)
01 Imperial (miles, feet, ..)
10 Reserved
11 No action";
CM_ SG_ 2566787070 AreaUnitCmd "Command to specify the area units
00 Metric (ha or m2)
01 Imperial (acres or feet2)
10 Reserved
11 No action";
CM_ SG_ 2566787070 VolumeUnitCmd "Command to specify the volume units
00 Metric (litre)
01 Imperial (gallon)
10 US (gallon)
11 No action";
CM_ SG_ 2566787070 MassUnitCmd "Command to specify the mass units
00 Metric (tonne, kg, …)
01 Imperial (long tons-UK, pounds, ….)
10 Tons/pounds (short tons-US, pounds, …)
11 No action";
CM_ SG_ 2566787070 DateCmd "Command sent to all ECUs which specifies the displayed order of the date.
0 ddmmyyyy
1 ddyyyymm
2 mmyyyydd
3 mmddyyyy
4 yyyymmdd
5 yyyyddmm
6-255 Reserved";
CM_ SG_ 2566787070 DecimalSymbolCmd "Command sent to all ECUs which specifies that a decimal point or Comma should be displayed.
00 Comma is used
01 Point is used
10 Reserved
11 No action";
CM_ SG_ 2566787070 TimeCmd "Command sent to all ECUs which specifies the displayed format of the time
00 24 hour
01 12 hour (am/ pm)
10 Reserved
11 No action";
CM_ SG_ 2566787070 LanguageCodeCmd "Command sent to all ECUs which specifies the operator’s desired language of information.  ISO 11783 shall use the 2-character string country codes in ISO 639.  Typical examples from ISO 639 are:
Dutch: nl
French: fr
English: en
German: de";
CM_ SG_ 2566786814 DataDictionaryRow "This 4 bit parameter indicates the Row that is to be used within the specific Data Dictionary Table identified by the Implement Type. This is the Group (GRUP) in LBS documents.";
CM_ SG_ 2566786814 DataDictionaryColumn "This 4 bit parameter indicates the Column that is to be used within the specific Data Dictionary Table identified by the Implement Type. This is the Instance (INST) in LBS documents.";
CM_ SG_ 2566786814 ImplementType "This 4 bit parameter indicates which data dictionary page is to be used to locate the identity of the following data.";
CM_ SG_ 2566786814 ImplementPos "This 4 bit parameter of this message will indicate which Implement is referenced within a set of identical Implements.  The numbering is to start with 1 at the leftmost, foremost, bottom most implement.  The numbering will then increment from left ...";
CM_ SG_ 2566786814 DataFormat_ErrorCondition "This 2 bit parameter that indicates the format or availability of the data in the following Process Data Parameter.
00 Data format is Long Integer
01 Data format is Floating
10 Data format is unsigned Long Integer
11 Not Available or error
Data ...";
CM_ SG_ 2566786814 ProcessDataType "This 2 bit parameter indicates what the data in the following Process Data Parameters is to be used for. See Table A.2.
00 Data is Set Point
01 Data is Actual values
10 Message is Set Point request
11 Message is Actual value request
Data is Set ...";
CM_ SG_ 2566786814 ProcessDataModifier "This 3 bit parameter that indicates how the data in the following Process Data Parameters is to be used when combined with the Process Data Type parameter. See Table A.2.
NOTE: Process Data Type is included since MOD is a function of PD";
CM_ SG_ 2566786814 RepetitionRateParameter "This parameter defines the repetition rate of the specified PGN.";
CM_ SG_ 2566785534 TrctrFcltyRspLmt_RqstSttsRprting "Indicates whether the vehicle supports reporting of the limit status and request status parameters in the tractor’s supported status messages.
0   Limit/request status reporting not available
1   Limit/request status reporting available";
CM_ SG_ 2566785278 TrctrFcltyRqLmt_RqstSttsRporting "Indicates whether the requester requires reporting of the limit status and request status parameters in the tractor’s supported status messages.
0  Limit/request status reporting not required
1  Limit/request status reporting required";
CM_ SG_ 2566770430 NAMEOfWorkingSetMember "NAME of Working Set Member
The identifier of the particular CA that is a member of the Working Set identified by the source address of this message.  This parameter is a NAME with the format described in 4.1.1.";
CM_ SG_ 2566761470 PGNOfConfigurableMessageDesired "To identify the configurable message whose configuration is being requested. If the request is for all configurable PGNs then this SPN is set to all ones.";
CM_ SG_ 2566761470 MessageSelectionCtrl "Used to identify all configurable messages.";
CM_ SG_ 2566754814 AutomaticTransferSwitchStatus "This parameter indicates the measured state of the automatic transfer switch.
Bit state 000 = Normal position
Bit state 001 = Emergency position
Bit states 010-101 = available for SAE assignment
Bit state 110 = error
Bit state 111 = not ...";
CM_ SG_ 2566754814 UtilityCircuitBreakerStatus "This parameter indicates the measured state of the utility circuit breaker.
Bit state 000 = Open
Bit state 001 = Closed
Bit state 010 = Locked Out
Bit states 011-101 = available for SAE assignment
Bit state 110 = error
Bit state 111 = not ...";
CM_ SG_ 2566754814 GeneratorCircuitBreakerStatus "This parameter indicates the measured state of the generator circuit breaker.
Bit state 000 = Open
Bit state 001 = Closed
Bit state 010 = Locked Out
Bit states 011-101 = available for SAE assignment
Bit state 110 = error
Bit state 111 = not ...";
CM_ SG_ 2566754302 GeneratorTotalPercentKVAr "This parameter reports the generator total AC reactive power, as a percentage of rated power.";
CM_ SG_ 2566754302 GeneratorTotalPercentKVA "This parameter reports the generator total AC apparent power, as a percentage of rated power.";
CM_ SG_ 2566754302 GeneratorTotalPercentKW "This parameter reports the generator total AC power, as a percentage of rated power.";
CM_ SG_ 2566754046 GeneratorTotalKVArHoursImport "This parameter reports the cumulative total AC reactive energy imported to the generator.";
CM_ SG_ 2566754046 GeneratorTotalKVArHoursExport "This parameter reports the cumulative total AC reactive energy exported from the generator.";
CM_ SG_ 2566753790 UtilityTotalKVArHoursImport "This parameter reports the cumulative total AC reactive energy imported to the utility.";
CM_ SG_ 2566753790 UtilityTotalKVArHoursExport "This parameter reports the cumulative total AC reactive energy exported from the utility.";
CM_ SG_ 2566734846 MachineSelectedDirectionCmd "Commanded direction of travel of the machine.
00 - Reverse
01 - Forward
10 - Reserved
11 - Don't care, take no action";
CM_ SG_ 2566734846 MchnSelectedSpeedExit_reasonCode "This parameter indicates why the Vehicle Speed control unit cannot currently accept remote commands or has most recently stopped accepting remote commands.
0-No reason/all clear
1-Operator presence not detected
2-Implement released control of ...";
CM_ SG_ 2566734846 MchineSelectedSpeedSetpointLimit "The machine's maximum allowed speed communicated to the tractor.";
CM_ SG_ 2566734846 MachineSelectedSpeedSetpointCmd "Commanded set point value of the machine speed as measured by the selected source.";
CM_ SG_ 2566734590 ISOBUSCmplncCrtfctnMssgeRevision "This parameter distinguishes the format ISOBUS Compliance Certification message in the 2nd edition from the format in the 3rd edition (and later).
0   Format of message in 2nd edition
1   Post-2nd edition message revision";
CM_ SG_ 2566734590 ISOBUSCmplncCrtfctnRfrenceNumber "Certificate reference number assigned by Certification laboratory.  Uniquely identifies the test file from the Certification laboratory when use with the Certification laboratory ID and the ECU manufacturer ID.";
CM_ SG_ 2566734590 ISOBUSCmplncCrtfctonTypeTaskCtrl "Parameter used to indicate the type of compliance test performed.
0    Not certified
1    Certified";
CM_ SG_ 2566734590 ISOBUSCmplncCrtfctnTypTCWrkn4326 "Parameter used to indicate the type of compliance test performed.
0    Not certified
1    Certified";
CM_ SG_ 2566734590 ISOBUSCmplncCrtfctnTypTCWrkngStM "Parameter used to indicate the type of compliance test performed.
0    Not certified
1    Certified";
CM_ SG_ 2566734590 ISOBUSCmplncCrtfctnTypFileServer "Parameter used to indicate the type of compliance test performed.
0    Not certified
1    Certified";
CM_ SG_ 2566734590 ISOBUSCmplncCrtfctnTypGPSRceiver "Parameter used to indicate the type of compliance test performed.
0    Not certified
1    Certified";
CM_ SG_ 2566734590 ISOBUSCmplncCrtfcationTypeMinECU "Parameter used to indicate the type of compliance test performed.
0    Not certified
1    Certified";
CM_ SG_ 2566734590 ISOBUSCmplncCrtfctnTypTECUClass1 "Parameter used to indicate the type of compliance test performed.
0    Not certified
1    Certified";
CM_ SG_ 2566734590 ISOBUSCmplncCrtfctnTypTECUClass2 "Parameter used to indicate the type of compliance test performed.
0    Not certified
1    Certified";
CM_ SG_ 2566734590 ISOBUSCmplncCrtfctnTypTECUClass3 "Parameter used to indicate the type of compliance test performed.
0    Not certified
1    Certified";
CM_ SG_ 2566734590 ISOBUSCmplncCrtfctnTypeClass3ECU "Parameter used to indicate the type of compliance test performed.
0    Not certified
1    Certified";
CM_ SG_ 2566734590 ISOBUSCmplncCrtfctnTypVrtlTrmnal "Parameter used to indicate the type of compliance test performed.
0    Not certified
1    Certified";
CM_ SG_ 2566734590 ISOBUSCmplncCrtfctnTypVTWrkn4323 "Parameter used to indicate the type of compliance test performed.
0    Not certified
1    Certified";
CM_ SG_ 2566734590 ISOBUSCmplncCrtfctnTypVTWrkngStM "Parameter used to indicate the type of compliance test performed.
0    Not certified
1    Certified";
CM_ SG_ 2566734590 ISOBUSCmplncCrtfctonLaboratoryID "Manufacturer code of the laboratory that performed the compliance test.  In the case of a self-certified ECU, this matches the manufacturer code contained in the address claim PGN.  See ISO 11783 Part 1 Annex B Table B6.";
CM_ SG_ 2566734590 ISOBUSCmplncCrtfctLaboratoryType "Approving body for the certification laboratory.
000 - Non-certified laboratory/ self certification
001 - EU certified laboratory
010 - NA certified laboratory
011 - 110 - Reserved
111 - Not available (Not certified)";
CM_ SG_ 2566734590 ISOBUSCmplnceCertificateRevision "Revision of the ISOBUS compliance test performed.  In years where there are multiple revisions of the test protocol, an alphabetic suffix is used in addition to the certification year.
000 - First Revision (No Suffix)
001 - Second Revision (Suffix ...";
CM_ SG_ 2566734590 ISOBUSCmplianceCertificationYear "Year of the compliance test protocol to which the certification test was performed.";
CM_ SG_ 2566718462 ImplementOperatingStateCmd "Command for setting the operating state of a connected implement system.
00  Set implement to field working state
01  Set implement to transport state
10  Set implement to park state
11  Take no action";
CM_ SG_ 2566718206 StpAllImplmntOprtnsTrnstonNumber "Indicates the number of transitions from Permit (01) to Stop (00) since power up of the Stop all implement operations parameter. The parameter resets to zero on the next transition after reporting the maximum value.";
CM_ SG_ 2566718206 AllImplmntStpOprtngOprtnsSwtchSt "State of a switch or other operator input for stopping the operation of a connected system.
00  All implements stop operations switch OFF
01  All implements stop operations switch ON
10  Error indication
11  Not available";
CM_ SG_ 2566701566 TransOilTransCoolerOutletTemp "Temperature of transmission lubricant after it exits from the transmission cooler.";
CM_ SG_ 2566701566 TransClutch2Press "Gage pressure of hydraulic actuation fluid of transmission second clutch in a dual clutch application.";
CM_ SG_ 2499592446 TransShiftRail6Pos "The current position of transmission shift rail identified as rail #6.";
CM_ SG_ 2499592446 TransShiftRail5Pos "The current position of transmission shift rail identified as rail #5.";
CM_ SG_ 2499592446 TransShiftRail4Pos "The current position of transmission shift rail identified as rail #4.";
CM_ SG_ 2499592446 TransShiftRail3Pos "The current position of transmission shift rail identified as rail #3.";
CM_ SG_ 2499592446 TransShiftRail2Pos "The current position of transmission shift rail identified as rail #2.";
CM_ SG_ 2499592446 TransShiftRail1Pos "The current position of transmission shift rail identified as rail #1.";
CM_ SG_ 2499592190 TransHydPumpActuator2Percent "The current modulated value for actuator 2 that controls the transmission hydraulic pump, where 0% = no hydraulic pressure and 100% = full hydraulic pressure.";
CM_ SG_ 2499592190 TransShiftRail6ActuatorStatus "Identifies the status of the actuator that moves the transmission shift rail identified as rail #6.
00 = off
01 = on
10 = error
11 = not available";
CM_ SG_ 2499592190 TransShiftRail5ActuatorStatus "Identifies the status of the actuator that moves the transmission shift rail identified as rail #5.
00 = off
01 = on
10 = error
11 = not available";
CM_ SG_ 2499592190 TransShiftRail4ActuatorStatus "Identifies the status of the actuator that moves the transmission shift rail identified as rail #4.
00 = off
01 = on
10 = error
11 = not available";
CM_ SG_ 2499592190 TransShiftRail3ActuatorStatus "Identifies the status of the actuator that moves the transmission shift rail identified as rail #3.
00 = off
01 = on
10 = error
11 = not available";
CM_ SG_ 2499592190 TransShiftRail2ActuatorStatus "Identifies the status of the actuator that moves the transmission shift rail identified as rail #2.
00 = off
01 = on
10 = error
11 = not available";
CM_ SG_ 2499592190 TransShiftRail1ActuatorStatus "Identifies the status of the actuator that moves the transmission shift rail identified as rail #1.
00 = off
01 = on
10 = error
11 = not available";
CM_ SG_ 2499592190 TrnsClutch2CoolingActuatorStatus "Identifies the status of the actuator that cools transmission clutch 2.
00 = off
01 = on
10 = error
11 = not available";
CM_ SG_ 2499592190 TrnsClutch1CoolingActuatorStatus "Identifies the status of the actuator that cools transmission clutch 1.
00 = off
01 = on
10 = error
11 = not available";
CM_ SG_ 2499592190 TransShiftActuator2Percent "The current modulated value for the transmission shift 2 actuator, where 0% = no hydraulic pressure and 100% = full hydraulic pressure.";
CM_ SG_ 2499592190 TransShiftActuator1Percent "The current modulated value for the transmission shift 1 actuator, where 0% = no hydraulic pressure and 100% = full hydraulic pressure.";
CM_ SG_ 2499592190 TransHydPumpActuator1Percent "The current modulated value for the actuator that controls the transmission hydraulic pump, where 0% = no hydraulic pressure and 100% = full hydraulic pressure.";
CM_ SG_ 2499592190 TransClutch2ActuatorPercent "The current modulated value for the transmission clutch 2 actuator, where 0% = no hydraulic pressure and 100% = full hydraulic pressure.";
CM_ SG_ 2499592190 TransClutch1ActuatorPercent "The current modulated value for the transmission clutch 1 actuator, where 0% = no hydraulic pressure and 100% = full hydraulic pressure.";
CM_ SG_ 2365374206 DlCltchTrnsCrrntPreselectionGear "The gear currently engaged on the non-engaged clutch of a dual clutch transmission (DCT) or the last gear engaged on the non-engaged clutch while the transmission is in the process of pre-selecting to the new or selected pre-selection gear on the ...";
CM_ SG_ 2365374206 DlCltchTrnsSlctdPreselectionGear "The gear that the transmission will attempt to achieve during the current pre-selection event (shifting to a new gear on the non-engaged clutch of a dual clutch transmission (DCT)).";
CM_ SG_ 2365374206 DualClutchTransInputShaft2Speed "Rotational velocity of the primary shaft transferring power through clutch 2 into the dual clutch transmission (DCT).";
CM_ SG_ 2365374206 DualClutchTransInputShaft1Speed "Rotational velocity of the primary shaft transferring power through clutch 1 into the dual clutch transmission (DCT).";
CM_ SG_ 2566700542 TripDEF "DEF consumed during all or part of a journey.";
CM_ SG_ 2566700542 TotalDEFUsed "Total amount of DEF used by aftertreatment device 1 over the lifetime of the device.";
CM_ SG_ 2566700286 TotalDEFUsed "Total amount of DEF used by aftertreatment device 2 over the lifetime of the device.";
CM_ SG_ 2566700030 DEFCtrlModule2PwrSupply2 "State signal which indicates when the DEF control module 2 power supply 2 of aftertreatment 1 is being driven. On means the ECU is powering the aftertreatment 1 DEF control module power supply. Note that the control module is external to the ECU.
...";
CM_ SG_ 2566700030 DEFCtrlModule2PwrSupply1 "State signal which indicates when the DEF control module 2 power supply of aftertreatment 1 is being driven. On means the ECU is powering the aftertreatment 1 DEF control module power supply. Note that the control module is external to the ECU.
00 ...";
CM_ SG_ 2566700030 DEFCtrlModule2RelayCtrl "State signal which indicates when the DEF control module 2 relay of aftertreatment 1 is being energized. On means the ECU is powering the Aftertreatment 1 DEF dosing unit relay. Note that the ECU is external to the relay.
00 - Off
01 - On: The ECU ...";
CM_ SG_ 2566700030 DEFCtrlModuleCircuitBreaker "The status of the circuit breaker that is used to power the diesel exhaust control module.
00 off
01 on
10 error
11 not available";
CM_ SG_ 2566700030 DEFCtrlModule1PwrSupply2 "State signal which indicates when the DEF control module 1 power supply 2 of aftertreatment 1 is being driven. On means the ECU is powering the aftertreatment 1 DEF control module 1 power supply. Note that the control module is external to the ECU.
...";
CM_ SG_ 2566700030 DEFCtrlModule1PwrSupply1 "State signal which indicates when the DEF control module power supply of aftertreatment 1 is being driven. On means the ECU is powering the aftertreatment 1 DEF control module power supply. Note that the control module is external to the ECU.
00 - ...";
CM_ SG_ 2566700030 DEFCtrlModule1RelayCtrl "State signal which indicates when the DEF control module relay of aftertreatment 1 is being energized. On means the ECU is powering the Aftertreatment 1 DEF dosing unit relay. Note that the ECU is external to the relay.
00 - Off
01 - On: The ECU ...";
CM_ SG_ 2566699774 DEFCtrlModule2PwrSupply2 "State signal which indicates when the DEF control module 2 power supply 2 of aftertreatment 2 is being driven. On means the ECU is powering the aftertreatment 2 DEF control module power supply. Note that the control module is external to the ECU.
...";
CM_ SG_ 2566699774 DEFCtrlModule2PwrSupply1 "State signal which indicates when the DEF control module 2 power supply of aftertreatment 2 is being driven. On means the ECU is powering the aftertreatment 2 DEF control module power supply. Note that the control module is external to the ECU.
00 ...";
CM_ SG_ 2566699774 DEFCtrlModule2RelayCtrl "State signal which indicates when the DEF control module 2 relay of aftertreatment 2 is being energized. On means the ECU is powering the Aftertreatment 2 DEF dosing unit relay. Note that the ECU is external to the relay.
00 - Off
01 - On: The ECU ...";
CM_ SG_ 2566699774 DEFCtrlModule1PwrSupply2 "State signal which indicates when the DEF control module 1 power supply 2 of aftertreatment 2 is being driven. On means the ECU is powering the aftertreatment 2 DEF control module 1 power supply. Note that the control module is external to the ECU.
...";
CM_ SG_ 2566699774 DEFCtrlModule1PwrSupply1 "State signal which indicates when the DEF control module 1 power supply of aftertreatment 2 is being driven. On means the ECU is powering the aftertreatment 2 DEF control module 1 power supply. Note that the control module is external to the ECU.
...";
CM_ SG_ 2566699774 DEFCtrlModule1RelayCtrl "State signal which indicates when the DEF control module 1 relay of aftertreatment 2 is being energized. On means the ECU is powering the Aftertreatment 2 DEF dosing unit relay. Note that the ECU is external to the relay.
00 - Off
01 - On: The ECU ...";
CM_ SG_ 2566699518 SCRSysTimeSinceLastSysCleanEvent "Indicates the time since the last cleaning event of the SCR system in bank 1.";
CM_ SG_ 2566699518 DPFTimeToNextActiveRegen "Indicates the time to the next active regeneration event of diesel particulate filter 1.";
CM_ SG_ 2566699262 SCRSysTimeSinceLastSysCleanEvent "Indicates the time since the last cleaning event of the SCR system in bank 2.";
CM_ SG_ 2566699262 DPFTimeToNextActiveRegen "Indicates the time to the next active regeneration event of diesel particulate filter 2.";
CM_ SG_ 2566698750 SLICrnkngPrdctdMinBatteryVoltage "Prediction of the minimum battery voltage used for starting the engine, for lighting, and for ignition (SLI) during a crank event, under present battery conditions.";
CM_ SG_ 2566698750 SLIBatteryPackHealth "Capacity of the battery pack relative to its original specification for the battery pack used for starting the engine, for lighting, and for ignition (SLI). 0% means battery pack is not capable of holding any charge, 100% means battery pack is ...";
CM_ SG_ 2566698750 SLIBatteryPackCapacity "Original or rated total reserve capacity of the battery pack used for starting the engine, for lighting, and for ignition (SLI).";
CM_ SG_ 2566698750 SLIBatteryPackStateOfCharge "Indicates the remaining charge of the battery pack used for starting the engine, for lighting, and for ignition (SLI). 0% means no charge remaining, 100% means full capacity at the battery pack's current state of health.   See SPN 5464 for hybrid ...";
CM_ SG_ 2566698494 FusedOutput29 "State of Fused Output #29. Used to indicate the output state.
00 - Output not powered
01 - Output powered
10 - Reserved
11 - Take no action";
CM_ SG_ 2566698494 FusedOutput30 "State of Fused Output #30. Used to indicate the output state.
00 - Output not powered
01 - Output powered
10 - Reserved
11 - Take no action";
CM_ SG_ 2566698494 FusedOutput31 "State of Fused Output #31. Used to indicate the output state.
00 - Output not powered
01 - Output powered
10 - Reserved
11 - Take no action";
CM_ SG_ 2566698494 FusedOutput32 "State of Fused Output #32. Used to indicate the output state.
00 - Output not powered
01 - Output powered
10 - Reserved
11 - Take no action";
CM_ SG_ 2566698494 FusedOutput25 "State of Fused Output #25. Used to indicate the output state.
00 - Output not powered
01 - Output powered
10 - Reserved
11 - Take no action";
CM_ SG_ 2566698494 FusedOutput26 "State of Fused Output #26. Used to indicate the output state.
00 - Output not powered
01 - Output powered
10 - Reserved
11 - Take no action";
CM_ SG_ 2566698494 FusedOutput27 "State of Fused Output #27. Used to indicate the output state.
00 - Output not powered
01 - Output powered
10 - Reserved
11 - Take no action";
CM_ SG_ 2566698494 FusedOutput28 "State of Fused Output #28. Used to indicate the output state.
00 - Output not powered
01 - Output powered
10 - Reserved
11 - Take no action";
CM_ SG_ 2566698494 FusedOutput21 "State of Fused Output #21. Used to indicate the output state.
00 - Output not powered
01 - Output powered
10 - Reserved
11 - Take no action";
CM_ SG_ 2566698494 FusedOutput22 "State of Fused Output #22. Used to indicate the output state.
00 - Output not powered
01 - Output powered
10 - Reserved
11 - Take no action";
CM_ SG_ 2566698494 FusedOutput23 "State of Fused Output #23. Used to indicate the output state.
00 - Output not powered
01 - Output powered
10 - Reserved
11 - Take no action";
CM_ SG_ 2566698494 FusedOutput24 "State of Fused Output #24. Used to indicate the output state.
00 - Output not powered
01 - Output powered
10 - Reserved
11 - Take no action";
CM_ SG_ 2566698494 FusedOutput17 "State of Fused Output #17. Used to indicate the output state.
00 - Output not powered
01 - Output powered
10 - Reserved
11 - Take no action";
CM_ SG_ 2566698494 FusedOutput18 "State of Fused Output #18. Used to indicate the output state.
00 - Output not powered
01 - Output powered
10 - Reserved
11 - Take no action";
CM_ SG_ 2566698494 FusedOutput19 "State of Fused Output #19. Used to indicate the output state.
00 - Output not powered
01 - Output powered
10 - Reserved
11 - Take no action";
CM_ SG_ 2566698494 FusedOutput20 "State of Fused Output #20. Used to indicate the output state.
00 - Output not powered
01 - Output powered
10 - Reserved
11 - Take no action";
CM_ SG_ 2566698494 FusedOutput13 "State of Fused Output #13. Used to indicate the output state.
00 - Output not powered
01 - Output powered
10 - Reserved
11 - Take no action";
CM_ SG_ 2566698494 FusedOutput14 "State of Fused Output #14. Used to indicate the output state.
00 - Output not powered
01 - Output powered
10 - Reserved
11 - Take no action";
CM_ SG_ 2566698494 FusedOutput15 "State of Fused Output #15. Used to indicate the output state.
00 - Output not powered
01 - Output powered
10 - Reserved
11 - Take no action";
CM_ SG_ 2566698494 FusedOutput16 "State of Fused Output #16. Used to indicate the output state.
00 - Output not powered
01 - Output powered
10 - Reserved
11 - Take no action";
CM_ SG_ 2566698494 FusedOutput9 "State of Fused Output #9. Used to indicate the output state.
00 - Output not powered
01 - Output powered
10 - Reserved
11 - Take no action";
CM_ SG_ 2566698494 FusedOutput10 "State of Fused Output #10. Used to indicate the output state.
00 - Output not powered
01 - Output powered
10 - Reserved
11 - Take no action";
CM_ SG_ 2566698494 FusedOutput11 "State of Fused Output #11. Used to indicate the output state.
00 - Output not powered
01 - Output powered
10 - Reserved
11 - Take no action";
CM_ SG_ 2566698494 FusedOutput12 "State of Fused Output #12. Used to indicate the output state.
00 - Output not powered
01 - Output powered
10 - Reserved
11 - Take no action";
CM_ SG_ 2566698494 FusedOutput5 "State of Fused Output #5. Used to indicate the output state.
00 - Output not powered
01 - Output powered
10 - Reserved
11 - Take no action";
CM_ SG_ 2566698494 FusedOutput6 "State of Fused Output #6. Used to indicate the output state.
00 - Output not powered
01 - Output powered
10 - Reserved
11 - Take no action";
CM_ SG_ 2566698494 FusedOutput7 "State of Fused Output #7. Used to indicate the output state.
00 - Output not powered
01 - Output powered
10 - Reserved
11 - Take no action";
CM_ SG_ 2566698494 FusedOutput8 "State of Fused Output #8. Used to indicate the output state.
00 - Output not powered
01 - Output powered
10 - Reserved
11 - Take no action";
CM_ SG_ 2566698494 FusedOutput1 "State of Fused Output #1. Used to indicate the output state.
00 - Output not powered
01 - Output powered
10 - Reserved
11 - Take no action";
CM_ SG_ 2566698494 FusedOutput2 "State of Fused Output #2. Used to indicate the output state.
00 - Output not powered
01 - Output powered
10 - Reserved
11 - Take no action";
CM_ SG_ 2566698494 FusedOutput3 "State of Fused Output #3. Used to indicate the output state.
00 - Output not powered
01 - Output powered
10 - Reserved
11 - Take no action";
CM_ SG_ 2566698494 FusedOutput4 "State of Fused Output #4. Used to indicate the output state.
00 - Output not powered
01 - Output powered
10 - Reserved
11 - Take no action";

BA_DEF_ BO_ "GenMsgCycleTime" INT 0 3600000;
BA_DEF_ BO_ "GenMsgCycleTimeFast" INT 0 3600000;
BA_DEF_ BO_ "GenMsgDelayTime" INT 0 1000;
BA_DEF_ BO_ "GenMsgILSupport" ENUM  "No","Yes";
BA_DEF_ BO_ "GenMsgRequestable" INT 0 1;
BA_DEF_ BO_ "GenMsgSendType" ENUM  "cyclic","spontaneous","cyclicIfActive","spontaneousWithDelay","cyclicAndSpontaneous","cyclicAndSpontaneousWithDelay","spontaneousWithRepetition","cyclicIfActiveAndSpontaneousWD";
BA_DEF_ BO_ "GenMsgStartDelayTime" INT 0 100000;
BA_DEF_ BO_ "J1939PGNameSecSrc0Dest3" STRING;
BA_DEF_ BO_ "J1939PGPrio" INT 0 7;
BA_DEF_ BO_ "J1939PGPrioSrc0Dest3" INT 0 7;
BA_DEF_ BO_ "J1939PGRelationDest3Src0" INT 0 254;
BA_DEF_ BO_ "J1939PGRelationSrc0Dest3" INT 0 254;
BA_DEF_ BO_ "J1939PGRepCycleSrc0Dest3" INT -1 65535;
BA_DEF_ BO_ "J1939PGRepTypeSrc0Dest3" INT 0 4;
BA_DEF_ BO_ "J1939PGRepetitionCycle" INT 0 65535;
BA_DEF_ BO_ "J1939PGRepetitionType" ENUM  "always","when active","on request";
BA_DEF_ BO_ "J1939PGtoECUSrc0Dest3" INT 0 254;
BA_DEF_ BO_ "J1939PGtoWSMSrc0Dest3" INT 0 254;
BA_DEF_ BO_ "TpJ1939VarDlc" ENUM  "No","Yes";
BA_DEF_ BO_ "VFrameFormat" ENUM  "StandardCAN","ExtendedCAN","reserved","J1939PG";
BA_DEF_ SG_ "GenSigEVName" STRING;
BA_DEF_ SG_ "GenSigILSupport" ENUM  "No","Yes";
BA_DEF_ SG_ "GenSigSendType" ENUM  "Cyclic","OnWrite","OnWriteWithRepetition","OnChange","OnChangeWithRepetition","IfActive","IfActiveWithRepetition","NoSigSendType";
BA_DEF_ SG_ "GenSigStartValue" INT 0 10000;
BA_DEF_ SG_ "SPN" INT 0 524287;
BA_DEF_ SG_ "SigType" ENUM  "Default","Range","RangeSigned","ASCII","Discrete","Control","ReferencePGN","DTC","StringDelimiter","StringLength","StringLengthControl","MessageCounter","MessageChecksum";
BA_DEF_ SG_ "SystemSignalLongSymbol" STRING;
BA_DEF_DEF_ "GenMsgCycleTime" 0;
BA_DEF_DEF_ "GenMsgCycleTimeFast" 0;
BA_DEF_DEF_ "GenMsgDelayTime" 0;
BA_DEF_DEF_ "GenMsgILSupport" "Yes";
BA_DEF_DEF_ "GenMsgRequestable" 1;
BA_DEF_DEF_ "GenMsgSendType" "noMsgSendType";
BA_DEF_DEF_ "GenMsgStartDelayTime" 0;
BA_DEF_DEF_ "GenSigEVName" "Env@Nodename_@Signame";
BA_DEF_DEF_ "GenSigILSupport" "Yes";
BA_DEF_DEF_ "GenSigSendType" "NoSigSendType";
BA_DEF_DEF_ "GenSigStartValue" 0;
BA_DEF_DEF_ "J1939PGNameSecSrc0Dest3" "(null)";
BA_DEF_DEF_ "J1939PGPrio" 6;
BA_DEF_DEF_ "J1939PGPrioSrc0Dest3" 6;
BA_DEF_DEF_ "J1939PGRelationDest3Src0" 254;
BA_DEF_DEF_ "J1939PGRelationSrc0Dest3" 254;
BA_DEF_DEF_ "J1939PGRepCycleSrc0Dest3" -1;
BA_DEF_DEF_ "J1939PGRepTypeSrc0Dest3" 3;
BA_DEF_DEF_ "J1939PGRepetitionCycle" 100;
BA_DEF_DEF_ "J1939PGRepetitionType" "always";
BA_DEF_DEF_ "J1939PGtoECUSrc0Dest3" -1;
BA_DEF_DEF_ "J1939PGtoWSMSrc0Dest3" -1;
BA_DEF_DEF_ "SPN" 0;
BA_DEF_DEF_ "SigType" "Default";
BA_DEF_DEF_ "SystemSignalLongSymbol" "";
BA_DEF_DEF_ "TpJ1939VarDlc" "No";
BA_DEF_DEF_ "VFrameFormat" "J1939PG";
BA_ "GenMsgCycleTime" BO_ 2558590718 1000;
BA_ "GenMsgDelayTime" BO_ 2558590718 100;
BA_ "GenMsgSendType" BO_ 2558590718 0;
BA_ "GenMsgCycleTime" BO_ 2350710526 100;
BA_ "GenMsgCycleTimeFast" BO_ 2350710526 10;
BA_ "GenMsgSendType" BO_ 2350710526 0;
BA_ "TpJ1939VarDlc" BO_ 2582642430 1;
BA_ "GenMsgCycleTime" BO_ 2566754814 250;
BA_ "GenMsgSendType" BO_ 2566754814 0;
BA_ "GenMsgCycleTime" BO_ 2566754302 250;
BA_ "GenMsgSendType" BO_ 2566754302 0;
BA_ "GenMsgCycleTime" BO_ 2566754046 250;
BA_ "GenMsgSendType" BO_ 2566754046 0;
BA_ "GenMsgCycleTime" BO_ 2566753790 250;
BA_ "GenMsgSendType" BO_ 2566753790 0;
BA_ "GenMsgCycleTime" BO_ 2566701566 1000;
BA_ "GenMsgSendType" BO_ 2566701566 0;
BA_ "GenMsgCycleTime" BO_ 2499592446 100;
BA_ "GenMsgSendType" BO_ 2499592446 0;
BA_ "GenMsgCycleTime" BO_ 2499592190 100;
BA_ "GenMsgSendType" BO_ 2499592190 0;
BA_ "GenMsgCycleTime" BO_ 2365374206 20;
BA_ "GenMsgSendType" BO_ 2365374206 0;
BA_ "GenMsgCycleTime" BO_ 2566700030 1000;
BA_ "GenMsgSendType" BO_ 2566700030 0;
BA_ "GenMsgCycleTime" BO_ 2566699774 1000;
BA_ "GenMsgSendType" BO_ 2566699774 0;
BA_ "GenMsgCycleTime" BO_ 2566698750 1000;
BA_ "GenMsgSendType" BO_ 2566698750 0;
BA_ "GenMsgCycleTime" BO_ 2566698494 1000;
BA_ "GenMsgDelayTime" BO_ 2566698494 25;
BA_ "GenMsgSendType" BO_ 2566698494 0;
BA_ "SPN" SG_ 2558590718 ShutdownCmd 7560;
BA_ "SigType" SG_ 2558590718 ShutdownCmd 5;
BA_ "SPN" SG_ 2558590718 PropulsionDisableReq 7558;
BA_ "SigType" SG_ 2558590718 PropulsionDisableReq 5;
BA_ "SPN" SG_ 2558590718 HybrdSystmRgnrtvBrakingDisableRq 7559;
BA_ "SigType" SG_ 2558590718 HybrdSystmRgnrtvBrakingDisableRq 5;
BA_ "SPN" SG_ 2558590718 HybridSystemProtectionOverrideRq 7557;
BA_ "SigType" SG_ 2558590718 HybridSystemProtectionOverrideRq 5;
BA_ "SPN" SG_ 2350776062 EngTimingAdvance_7355 7355;
BA_ "SigType" SG_ 2350776062 EngTimingAdvance_7355 1;
BA_ "SPN" SG_ 2350710526 MessageChecksum_7042 7042;
BA_ "SPN" SG_ 2350710526 TransReqTorqueOrTorqueLim_7040 7040;
BA_ "SigType" SG_ 2350710526 TransReqTorqueOrTorqueLim_7040 1;
BA_ "GenSigStartValue" SG_ 2350710526 TransReqOutputShaftSpeed_7039 2;
BA_ "SPN" SG_ 2350710526 TransReqOutputShaftSpeed_7039 7039;
BA_ "SigType" SG_ 2350710526 TransReqOutputShaftSpeed_7039 1;
BA_ "SPN" SG_ 2350710526 MessageCounter_7041 7041;
BA_ "SPN" SG_ 2350710526 TransOvCtrlModePriority_7038 7038;
BA_ "SigType" SG_ 2350710526 TransOvCtrlModePriority_7038 5;
BA_ "SPN" SG_ 2350710526 TransOverrideCtrlMode_7037 7037;
BA_ "SigType" SG_ 2350710526 TransOverrideCtrlMode_7037 5;
BA_ "SPN" SG_ 2582642430 ManufacturerSpecificInformation 3328;
BA_ "SPN" SG_ 2566801918 GroundBasedDirection 1861;
BA_ "SigType" SG_ 2566801918 GroundBasedDirection 4;
BA_ "SPN" SG_ 2566801918 GroundBasedImplementDistance 1860;
BA_ "SPN" SG_ 2566801918 GroundBasedImplementSpeed 1859;
BA_ "SPN" SG_ 2566801662 KeySwitchNOTOFF 1865;
BA_ "SigType" SG_ 2566801662 KeySwitchNOTOFF 4;
BA_ "SPN" SG_ 2566801662 WheelBasedDirection 1864;
BA_ "SigType" SG_ 2566801662 WheelBasedDirection 4;
BA_ "SPN" SG_ 2566801662 MaxTimeOfTractorPower 1866;
BA_ "SPN" SG_ 2566801662 WheelBasedDistance 1863;
BA_ "SPN" SG_ 2566801662 WheelBasedSpeed 1862;
BA_ "SPN" SG_ 2566801406 ImplementInWorkState 7447;
BA_ "SigType" SG_ 2566801406 ImplementInWorkState 4;
BA_ "SPN" SG_ 2566801406 ImplementTransportState 1869;
BA_ "SigType" SG_ 2566801406 ImplementTransportState 4;
BA_ "SPN" SG_ 2566801406 ImplementParkState 1870;
BA_ "SigType" SG_ 2566801406 ImplementParkState 4;
BA_ "SPN" SG_ 2566801406 ImplementWorkState 1871;
BA_ "SigType" SG_ 2566801406 ImplementWorkState 4;
BA_ "SPN" SG_ 2566801406 MaintainECUPower 1867;
BA_ "SigType" SG_ 2566801406 MaintainECUPower 4;
BA_ "SPN" SG_ 2566801406 MaintainAcuatorPower 1868;
BA_ "SigType" SG_ 2566801406 MaintainAcuatorPower 4;
BA_ "SPN" SG_ 2566801150 FrontDraft 1878;
BA_ "SPN" SG_ 2566801150 FrontNominalLowerLinkForce 1880;
BA_ "SPN" SG_ 2566801150 FrontHitchInworkIndication 1876;
BA_ "SigType" SG_ 2566801150 FrontHitchInworkIndication 4;
BA_ "SPN" SG_ 2566801150 FrontHitchPos 1872;
BA_ "SPN" SG_ 2566800894 RearHitchExit_reasonCode 5819;
BA_ "SPN" SG_ 2566800894 RearDraft 1879;
BA_ "SPN" SG_ 2566800894 RearNominalLowerLinkForce 1881;
BA_ "SPN" SG_ 2566800894 RearHitchInworkIndication 1877;
BA_ "SigType" SG_ 2566800894 RearHitchInworkIndication 4;
BA_ "SPN" SG_ 2566800894 RearHitchPos 1873;
BA_ "SPN" SG_ 2566800638 FrontPTOExit_reasonCode 5817;
BA_ "SPN" SG_ 2566800638 FrontHitchExit_reasonCode 5816;
BA_ "SPN" SG_ 2566800638 FrontPowerTakeOffEngagement 1888;
BA_ "SigType" SG_ 2566800638 FrontPowerTakeOffEngagement 4;
BA_ "SPN" SG_ 2566800638 FrontPowerTakeOffMode 1889;
BA_ "SigType" SG_ 2566800638 FrontPowerTakeOffMode 4;
BA_ "SPN" SG_ 2566800638 FrontPowerTakeOffEconomyMode 1891;
BA_ "SigType" SG_ 2566800638 FrontPowerTakeOffEconomyMode 4;
BA_ "SPN" SG_ 2566800638 FrontPTOOutputShaftSpeedSetPoint 1884;
BA_ "SPN" SG_ 2566800638 FrontPTOOutputShaftSpeed 1882;
BA_ "SPN" SG_ 2566800382 RearPTOExit_reasonCode 5820;
BA_ "SPN" SG_ 2566800382 RearPowerTakeOffEngagement 2408;
BA_ "SigType" SG_ 2566800382 RearPowerTakeOffEngagement 4;
BA_ "SPN" SG_ 2566800382 RearPowerTakeOffMode 1890;
BA_ "SigType" SG_ 2566800382 RearPowerTakeOffMode 4;
BA_ "SPN" SG_ 2566800382 RearPowerTakeOffEconomyMode 1892;
BA_ "SigType" SG_ 2566800382 RearPowerTakeOffEconomyMode 4;
BA_ "SPN" SG_ 2566800382 RearPTOOutputShaftSpeedSetPoint 1885;
BA_ "SPN" SG_ 2566800382 RearPTOOutputShaftSpeed 1883;
BA_ "SPN" SG_ 2566800126 FrontPowerTakeOffModeCmd 1895;
BA_ "SigType" SG_ 2566800126 FrontPowerTakeOffModeCmd 4;
BA_ "SPN" SG_ 2566800126 RearPowerTakeOffModeCmd 1896;
BA_ "SigType" SG_ 2566800126 RearPowerTakeOffModeCmd 4;
BA_ "SPN" SG_ 2566800126 FrontPowerTakeOffEconomyModeCmd 1897;
BA_ "SigType" SG_ 2566800126 FrontPowerTakeOffEconomyModeCmd 4;
BA_ "SPN" SG_ 2566800126 RearPowerTakeOffEconomyModeCmd 1898;
BA_ "SigType" SG_ 2566800126 RearPowerTakeOffEconomyModeCmd 4;
BA_ "SPN" SG_ 2566800126 FrontPowerTakeOffEngagementCmd 1893;
BA_ "SigType" SG_ 2566800126 FrontPowerTakeOffEngagementCmd 4;
BA_ "SPN" SG_ 2566800126 RearPowerTakeOffEngagementCmd 1894;
BA_ "SigType" SG_ 2566800126 RearPowerTakeOffEngagementCmd 4;
BA_ "SPN" SG_ 2566800126 RrPTOOutputShaftSpeedSetPointCmd 1887;
BA_ "SPN" SG_ 2566800126 FrntPTOOtptShaftSpeedSetPointCmd 1886;
BA_ "SPN" SG_ 2566800126 RearHitchPosCmd 1875;
BA_ "SPN" SG_ 2566800126 FrontHitchPosCmd 1874;
BA_ "SPN" SG_ 2566799358 AuxValve15FailSafeModeCmd 2345;
BA_ "SigType" SG_ 2566799358 AuxValve15FailSafeModeCmd 4;
BA_ "SPN" SG_ 2566799358 AuxValve15StateCmd 2344;
BA_ "SPN" SG_ 2566799358 AuxValve15PortFlowCmd 2343;
BA_ "SPN" SG_ 2566799102 AuxValve14FailSafeModeCmd 2333;
BA_ "SigType" SG_ 2566799102 AuxValve14FailSafeModeCmd 4;
BA_ "SPN" SG_ 2566799102 AuxValve14StateCmd 2332;
BA_ "SPN" SG_ 2566799102 AuxValve14PortFlowCmd 2331;
BA_ "SPN" SG_ 2566798846 AuxValve13FailSafeModeCmd 2321;
BA_ "SigType" SG_ 2566798846 AuxValve13FailSafeModeCmd 4;
BA_ "SPN" SG_ 2566798846 AuxValve13StateCmd 2320;
BA_ "SPN" SG_ 2566798846 AuxValve13PortFlowCmd 2319;
BA_ "SPN" SG_ 2566798590 AuxValve12FailSafeModeCmd 2309;
BA_ "SigType" SG_ 2566798590 AuxValve12FailSafeModeCmd 4;
BA_ "SPN" SG_ 2566798590 AuxValve12StateCmd 2308;
BA_ "SPN" SG_ 2566798590 AuxValve12PortFlowCmd 2307;
BA_ "SPN" SG_ 2566798334 AuxValve11FailSafeModeCmd 2297;
BA_ "SigType" SG_ 2566798334 AuxValve11FailSafeModeCmd 4;
BA_ "SPN" SG_ 2566798334 AuxValve11StateCmd 2296;
BA_ "SPN" SG_ 2566798334 AuxValve11PortFlowCmd 2295;
BA_ "SPN" SG_ 2566798078 AuxValve10FailSafeModeCmd 2285;
BA_ "SigType" SG_ 2566798078 AuxValve10FailSafeModeCmd 4;
BA_ "SPN" SG_ 2566798078 AuxValve10StateCmd 2284;
BA_ "SPN" SG_ 2566798078 AuxValve10PortFlowCmd 2283;
BA_ "SPN" SG_ 2566797822 AuxValve9FailSafeModeCmd 2273;
BA_ "SigType" SG_ 2566797822 AuxValve9FailSafeModeCmd 4;
BA_ "SPN" SG_ 2566797822 AuxValve9StateCmd 2272;
BA_ "SPN" SG_ 2566797822 AuxValve9PortFlowCmd 2271;
BA_ "SPN" SG_ 2566797566 AuxValve8FailSafeModeCmd 2261;
BA_ "SigType" SG_ 2566797566 AuxValve8FailSafeModeCmd 4;
BA_ "SPN" SG_ 2566797566 AuxValve8StateCmd 2260;
BA_ "SPN" SG_ 2566797566 AuxValve8PortFlowCmd 2259;
BA_ "SPN" SG_ 2566797310 AuxValve7FailSafeModeCmd 1993;
BA_ "SigType" SG_ 2566797310 AuxValve7FailSafeModeCmd 4;
BA_ "SPN" SG_ 2566797310 AuxValve7StateCmd 1992;
BA_ "SPN" SG_ 2566797310 AuxValve7PortFlowCmd 1991;
BA_ "SPN" SG_ 2566797054 AuxValve6FailSafeModeCmd 1981;
BA_ "SigType" SG_ 2566797054 AuxValve6FailSafeModeCmd 4;
BA_ "SPN" SG_ 2566797054 AuxValve6StateCmd 1980;
BA_ "SPN" SG_ 2566797054 AuxValve6PortFlowCmd 1979;
BA_ "SPN" SG_ 2566796798 AuxValve5FailSafeModeCmd 1969;
BA_ "SigType" SG_ 2566796798 AuxValve5FailSafeModeCmd 4;
BA_ "SPN" SG_ 2566796798 AuxValve5StateCmd 1968;
BA_ "SPN" SG_ 2566796798 AuxValve5PortFlowCmd 1967;
BA_ "SPN" SG_ 2566796542 AuxValve4FailSafeModeCmd 1957;
BA_ "SigType" SG_ 2566796542 AuxValve4FailSafeModeCmd 4;
BA_ "SPN" SG_ 2566796542 AuxValve4StateCmd 1956;
BA_ "SPN" SG_ 2566796542 AuxValve4PortFlowCmd 1955;
BA_ "SPN" SG_ 2566796286 AuxValve3FailSafeModeCmd 1945;
BA_ "SigType" SG_ 2566796286 AuxValve3FailSafeModeCmd 4;
BA_ "SPN" SG_ 2566796286 AuxValve3StateCmd 1944;
BA_ "SPN" SG_ 2566796286 AuxValve3PortFlowCmd 1943;
BA_ "SPN" SG_ 2566796030 AuxValve2FailSafeModeCmd 1933;
BA_ "SigType" SG_ 2566796030 AuxValve2FailSafeModeCmd 4;
BA_ "SPN" SG_ 2566796030 AuxValve2StateCmd 1932;
BA_ "SPN" SG_ 2566796030 AuxValve2PortFlowCmd 1931;
BA_ "SPN" SG_ 2566795774 AuxValve1FailSafeModeCmd 1921;
BA_ "SigType" SG_ 2566795774 AuxValve1FailSafeModeCmd 4;
BA_ "SPN" SG_ 2566795774 AuxValve1StateCmd 1920;
BA_ "SPN" SG_ 2566795774 AuxValve1PortFlowCmd 1919;
BA_ "SPN" SG_ 2566795518 AuxValve0FailSafeModeCmd 1909;
BA_ "SigType" SG_ 2566795518 AuxValve0FailSafeModeCmd 4;
BA_ "SPN" SG_ 2566795518 AuxValve0StateCmd 1908;
BA_ "SPN" SG_ 2566795518 AuxValve0PortFlowCmd 1907;
BA_ "SPN" SG_ 2566795262 AuxValve15ReturnPortPress 2342;
BA_ "SPN" SG_ 2566795262 AuxValve15RetractPortPress 2341;
BA_ "SPN" SG_ 2566795262 AuxValve15ExtendPortPress 2340;
BA_ "SPN" SG_ 2566795262 AxValve15RetractPortMeasuredFlow 2336;
BA_ "SPN" SG_ 2566795262 AuxValve15ExtendPortMeasuredFlow 2335;
BA_ "SPN" SG_ 2566795006 AuxValve14ReturnPortPress 2330;
BA_ "SPN" SG_ 2566795006 AuxValve14RetractPortPress 2329;
BA_ "SPN" SG_ 2566795006 AuxValve14ExtendPortPress 2328;
BA_ "SPN" SG_ 2566795006 AxValve14RetractPortMeasuredFlow 2324;
BA_ "SPN" SG_ 2566795006 AuxValve14ExtendPortMeasuredFlow 2323;
BA_ "SPN" SG_ 2566794750 AuxValve13ReturnPortPress 2318;
BA_ "SPN" SG_ 2566794750 AuxValve13RetractPortPress 2317;
BA_ "SPN" SG_ 2566794750 AuxValve13ExtendPortPress 2316;
BA_ "SPN" SG_ 2566794750 AxValve13RetractPortMeasuredFlow 2312;
BA_ "SPN" SG_ 2566794750 AuxValve13ExtendPortMeasuredFlow 2311;
BA_ "SPN" SG_ 2566794494 AuxValve12ReturnPortPress 2306;
BA_ "SPN" SG_ 2566794494 AuxValve12RetractPortPress 2305;
BA_ "SPN" SG_ 2566794494 AuxValve12ExtendPortPress 2304;
BA_ "SPN" SG_ 2566794494 AxValve12RetractPortMeasuredFlow 2300;
BA_ "SPN" SG_ 2566794494 AuxValve12ExtendPortMeasuredFlow 2299;
BA_ "SPN" SG_ 2566794238 AuxValve11ReturnPortPress 2294;
BA_ "SPN" SG_ 2566794238 AuxValve11RetractPortPress 2293;
BA_ "SPN" SG_ 2566794238 AuxValve11ExtendPortPress 2292;
BA_ "SPN" SG_ 2566794238 AxValve11RetractPortMeasuredFlow 2288;
BA_ "SPN" SG_ 2566794238 AuxValve11ExtendPortMeasuredFlow 2287;
BA_ "SPN" SG_ 2566793982 AuxValve10ReturnPortPress 2282;
BA_ "SPN" SG_ 2566793982 AuxValve10RetractPortPress 2281;
BA_ "SPN" SG_ 2566793982 AuxValve10ExtendPortPress 2280;
BA_ "SPN" SG_ 2566793982 AxValve10RetractPortMeasuredFlow 2276;
BA_ "SPN" SG_ 2566793982 AuxValve10ExtendPortMeasuredFlow 2275;
BA_ "SPN" SG_ 2566793726 AuxValve9ReturnPortPress 2270;
BA_ "SPN" SG_ 2566793726 AuxValve9RetractPortPress 2269;
BA_ "SPN" SG_ 2566793726 AuxValve9ExtendPortPress 2268;
BA_ "SPN" SG_ 2566793726 AuxValve9RetractPortMeasuredFlow 2264;
BA_ "SPN" SG_ 2566793726 AuxValve9ExtendPortMeasuredFlow 2263;
BA_ "SPN" SG_ 2566793470 AuxValve8ReturnPortPress 2258;
BA_ "SPN" SG_ 2566793470 AuxValve8RetractPortPress 2257;
BA_ "SPN" SG_ 2566793470 AuxValve8ExtendPortPress 2256;
BA_ "SPN" SG_ 2566793470 AuxValve8RetractPortMeasuredFlow 1996;
BA_ "SPN" SG_ 2566793470 AuxValve8ExtendPortMeasuredFlow 1995;
BA_ "SPN" SG_ 2566793214 AuxValve7ReturnPortPress 1990;
BA_ "SPN" SG_ 2566793214 AuxValve7RetractPortPress 1989;
BA_ "SPN" SG_ 2566793214 AuxValve7ExtendPortPress 1988;
BA_ "SPN" SG_ 2566793214 AuxValve7RetractPortMeasuredFlow 1984;
BA_ "SPN" SG_ 2566793214 AuxValve7ExtendPortMeasuredFlow 1983;
BA_ "SPN" SG_ 2566792958 AuxValve6ReturnPortPress 1978;
BA_ "SPN" SG_ 2566792958 AuxValve6RetractPortPress 1977;
BA_ "SPN" SG_ 2566792958 AuxValve6ExtendPortPress 1976;
BA_ "SPN" SG_ 2566792958 AuxValve6RetractPortMeasuredFlow 1972;
BA_ "SPN" SG_ 2566792958 AuxValve6ExtendPortMeasuredFlow 1971;
BA_ "SPN" SG_ 2566792702 AuxValve5ReturnPortPress 1966;
BA_ "SPN" SG_ 2566792702 AuxValve5RetractPortPress 1965;
BA_ "SPN" SG_ 2566792702 AuxValve5ExtendPortPress 1964;
BA_ "SPN" SG_ 2566792702 AuxValve5RetractPortMeasuredFlow 1960;
BA_ "SPN" SG_ 2566792702 AuxValve5ExtendPortMeasuredFlow 1959;
BA_ "SPN" SG_ 2566792446 AuxValve4ReturnPortPress 1954;
BA_ "SPN" SG_ 2566792446 AuxValve4RetractPortPress 1953;
BA_ "SPN" SG_ 2566792446 AuxValve4ExtendPortPress 1952;
BA_ "SPN" SG_ 2566792446 AuxValve4RetractPortMeasuredFlow 1948;
BA_ "SPN" SG_ 2566792446 AuxValve4ExtendPortMeasuredFlow 1947;
BA_ "SPN" SG_ 2566792190 AuxValve3ReturnPortPress 1942;
BA_ "SPN" SG_ 2566792190 AuxValve3RetractPortPress 1941;
BA_ "SPN" SG_ 2566792190 AuxValve3ExtendPortPress 1940;
BA_ "SPN" SG_ 2566792190 AuxValve3RetractPortMeasuredFlow 1936;
BA_ "SPN" SG_ 2566792190 AuxValve3ExtendPortMeasuredFlow 1935;
BA_ "SPN" SG_ 2566791934 AuxValve2ReturnPortPress 1930;
BA_ "SPN" SG_ 2566791934 AuxValve2RetractPortPress 1929;
BA_ "SPN" SG_ 2566791934 AuxValve2ExtendPortPress 1928;
BA_ "SPN" SG_ 2566791934 AuxValve2RetractPortMeasuredFlow 1924;
BA_ "SPN" SG_ 2566791934 AuxValve2ExtendPortMeasuredFlow 1923;
BA_ "SPN" SG_ 2566791678 AuxValve1ReturnPortPress 1918;
BA_ "SPN" SG_ 2566791678 AuxValve1RetractPortPress 1917;
BA_ "SPN" SG_ 2566791678 AuxValve1ExtendPortPress 1916;
BA_ "SPN" SG_ 2566791678 AuxValve1RetractPortMeasuredFlow 1912;
BA_ "SPN" SG_ 2566791678 AuxValve1ExtendPortMeasuredFlow 1911;
BA_ "SPN" SG_ 2566791422 AuxValve0ReturnPortPress 1906;
BA_ "SPN" SG_ 2566791422 AuxValve0RetractPortPress 1905;
BA_ "SPN" SG_ 2566791422 AuxValve0ExtendPortPress 1904;
BA_ "SPN" SG_ 2566791422 AuxValve0RetractPortMeasuredFlow 1900;
BA_ "SPN" SG_ 2566791422 AuxValve0ExtendPortMeasuredFlow 1899;
BA_ "SPN" SG_ 2566791166 AuxValve15Exit_reasonCode 5815;
BA_ "SPN" SG_ 2566791166 AuxValve15FailSafeMode 2346;
BA_ "SigType" SG_ 2566791166 AuxValve15FailSafeMode 4;
BA_ "SPN" SG_ 2566791166 AuxValve15State 2339;
BA_ "SPN" SG_ 2566791166 AuxValve15RetractPortEstFlow 2338;
BA_ "SPN" SG_ 2566791166 AuxValve15ExtendPortEstFlow 2337;
BA_ "SPN" SG_ 2566790910 AuxValve14Exit_reasonCode 5814;
BA_ "SPN" SG_ 2566790910 AuxValve14FailSafeMode 2334;
BA_ "SigType" SG_ 2566790910 AuxValve14FailSafeMode 4;
BA_ "SPN" SG_ 2566790910 AuxValve14State 2327;
BA_ "SPN" SG_ 2566790910 AuxValve14RetractPortEstFlow 2326;
BA_ "SPN" SG_ 2566790910 AuxValve14ExtendPortEstFlow 2325;
BA_ "SPN" SG_ 2566790654 AuxValve13Exit_reasonCode 5813;
BA_ "SPN" SG_ 2566790654 AuxValve13FailSafeMode 2322;
BA_ "SigType" SG_ 2566790654 AuxValve13FailSafeMode 4;
BA_ "SPN" SG_ 2566790654 AuxValve13State 2315;
BA_ "SPN" SG_ 2566790654 AuxValve13RetractPortEstFlow 2314;
BA_ "SPN" SG_ 2566790654 AuxValve13ExtendPortEstFlow 2313;
BA_ "SPN" SG_ 2566790398 AuxValve12Exit_reasonCode 5812;
BA_ "SPN" SG_ 2566790398 AuxValve12FailSafeMode 2310;
BA_ "SigType" SG_ 2566790398 AuxValve12FailSafeMode 4;
BA_ "SPN" SG_ 2566790398 AuxValve12State 2303;
BA_ "SPN" SG_ 2566790398 AuxValve12RetractPortEstFlow 2302;
BA_ "SPN" SG_ 2566790398 AuxValve12ExtendPortEstFlow 2301;
BA_ "SPN" SG_ 2566790142 AuxValve11Exit_reasonCode 5811;
BA_ "SPN" SG_ 2566790142 AuxValve11FailSafeMode 2298;
BA_ "SigType" SG_ 2566790142 AuxValve11FailSafeMode 4;
BA_ "SPN" SG_ 2566790142 AuxValve11State 2291;
BA_ "SPN" SG_ 2566790142 AuxValve11RetractPortEstFlow 2290;
BA_ "SPN" SG_ 2566790142 AuxValve11ExtendPortEstFlow 2289;
BA_ "SPN" SG_ 2566789886 AuxValve10Exit_reasonCode 5810;
BA_ "SPN" SG_ 2566789886 AuxValve10FailSafeMode 2286;
BA_ "SigType" SG_ 2566789886 AuxValve10FailSafeMode 4;
BA_ "SPN" SG_ 2566789886 AuxValve10State 2279;
BA_ "SPN" SG_ 2566789886 AuxValve10RetractPortEstFlow 2278;
BA_ "SPN" SG_ 2566789886 AuxValve10ExtendPortEstFlow 2277;
BA_ "SPN" SG_ 2566789630 AuxValve9Exit_reasonCode 5809;
BA_ "SPN" SG_ 2566789630 AuxValve9FailSafeMode 2274;
BA_ "SigType" SG_ 2566789630 AuxValve9FailSafeMode 4;
BA_ "SPN" SG_ 2566789630 AuxValve9State 2267;
BA_ "SPN" SG_ 2566789630 AuxValve9RetractPortEstFlow 2266;
BA_ "SPN" SG_ 2566789630 AuxValve9ExtendPortEstFlow 2265;
BA_ "SPN" SG_ 2566789374 AuxValve8Exit_reasonCode 5808;
BA_ "SPN" SG_ 2566789374 AuxValve8FailSafeMode 2262;
BA_ "SigType" SG_ 2566789374 AuxValve8FailSafeMode 4;
BA_ "SPN" SG_ 2566789374 AuxValve8State 1999;
BA_ "SPN" SG_ 2566789374 AuxValve8RetractPortEstFlow 1998;
BA_ "SPN" SG_ 2566789374 AuxValve8ExtendPortEstFlow 1997;
BA_ "SPN" SG_ 2566789118 AuxValve7Exit_reasonCode 5807;
BA_ "SPN" SG_ 2566789118 AuxValve7FailSafeMode 1994;
BA_ "SigType" SG_ 2566789118 AuxValve7FailSafeMode 4;
BA_ "SPN" SG_ 2566789118 AuxValve7State 1987;
BA_ "SPN" SG_ 2566789118 AuxValve7RetractPortEstFlow 1986;
BA_ "SPN" SG_ 2566789118 AuxValve7ExtendPortEstFlow 1985;
BA_ "SPN" SG_ 2566788862 AuxValve6Exit_reasonCode 5806;
BA_ "SPN" SG_ 2566788862 AuxValve6FailSafeMode 1982;
BA_ "SigType" SG_ 2566788862 AuxValve6FailSafeMode 4;
BA_ "SPN" SG_ 2566788862 AuxValve6State 1975;
BA_ "SPN" SG_ 2566788862 AuxValve6RetractPortEstFlow 1974;
BA_ "SPN" SG_ 2566788862 AuxValve6ExtendPortEstFlow 1973;
BA_ "SPN" SG_ 2566788606 AuxValve5Exit_reasonCode 5805;
BA_ "SPN" SG_ 2566788606 AuxValve5FailSafeMode 1970;
BA_ "SigType" SG_ 2566788606 AuxValve5FailSafeMode 4;
BA_ "SPN" SG_ 2566788606 AuxValve5State 1963;
BA_ "SPN" SG_ 2566788606 AuxValve5RetractPortEstFlow 1962;
BA_ "SPN" SG_ 2566788606 AuxValve5ExtendPortEstFlow 1961;
BA_ "SPN" SG_ 2566788350 AuxValve4Exit_reasonCode 5804;
BA_ "SPN" SG_ 2566788350 AuxValve4FailSafeMode 1958;
BA_ "SigType" SG_ 2566788350 AuxValve4FailSafeMode 4;
BA_ "SPN" SG_ 2566788350 AuxValve4State 1951;
BA_ "SPN" SG_ 2566788350 AuxValve4RetractPortEstFlow 1950;
BA_ "SPN" SG_ 2566788350 AuxValve4ExtendPortEstFlow 1949;
BA_ "SPN" SG_ 2566788094 AuxValve3Exit_reasonCode 5803;
BA_ "SPN" SG_ 2566788094 AuxValve3FailSafeMode 1946;
BA_ "SigType" SG_ 2566788094 AuxValve3FailSafeMode 4;
BA_ "SPN" SG_ 2566788094 AuxValve3State 1939;
BA_ "SPN" SG_ 2566788094 AuxValve3RetractPortEstFlow 1938;
BA_ "SPN" SG_ 2566788094 AuxValve3ExtendPortEstFlow 1937;
BA_ "SPN" SG_ 2566787838 AuxValve2Exit_reasonCode 5802;
BA_ "SPN" SG_ 2566787838 AuxValve2FailSafeMode 1934;
BA_ "SigType" SG_ 2566787838 AuxValve2FailSafeMode 4;
BA_ "SPN" SG_ 2566787838 AuxValve2State 1927;
BA_ "SPN" SG_ 2566787838 AuxValve2RetractPortEstFlow 1926;
BA_ "SPN" SG_ 2566787838 AuxValve2ExtendPortEstFlow 1925;
BA_ "SPN" SG_ 2566787582 AuxValve1Exit_reasonCode 5801;
BA_ "SPN" SG_ 2566787582 AuxValve1FailSafeMode 1922;
BA_ "SigType" SG_ 2566787582 AuxValve1FailSafeMode 4;
BA_ "SPN" SG_ 2566787582 AuxValve1State 1915;
BA_ "SPN" SG_ 2566787582 AuxValve1RetractPortEstFlow 1914;
BA_ "SPN" SG_ 2566787582 AuxValve1ExtendPortEstFlow 1913;
BA_ "SPN" SG_ 2566787326 AuxValve0Exit_reasonCode 5800;
BA_ "SPN" SG_ 2566787326 AuxValve0FailSafeMode 1910;
BA_ "SigType" SG_ 2566787326 AuxValve0FailSafeMode 4;
BA_ "SPN" SG_ 2566787326 AuxValve0State 1903;
BA_ "SPN" SG_ 2566787326 AuxValve0RetractPortEstFlow 1902;
BA_ "SPN" SG_ 2566787326 AuxValve0ExtendPortEstFlow 1901;
BA_ "SPN" SG_ 2566787070 DistanceUnitCmd 2414;
BA_ "SigType" SG_ 2566787070 DistanceUnitCmd 4;
BA_ "SPN" SG_ 2566787070 AreaUnitCmd 2415;
BA_ "SigType" SG_ 2566787070 AreaUnitCmd 4;
BA_ "SPN" SG_ 2566787070 VolumeUnitCmd 2416;
BA_ "SigType" SG_ 2566787070 VolumeUnitCmd 4;
BA_ "SPN" SG_ 2566787070 MassUnitCmd 2417;
BA_ "SigType" SG_ 2566787070 MassUnitCmd 4;
BA_ "SPN" SG_ 2566787070 DateCmd 2412;
BA_ "SPN" SG_ 2566787070 DecimalSymbolCmd 2411;
BA_ "SigType" SG_ 2566787070 DecimalSymbolCmd 4;
BA_ "SPN" SG_ 2566787070 TimeCmd 2413;
BA_ "SigType" SG_ 2566787070 TimeCmd 4;
BA_ "SPN" SG_ 2566787070 LanguageCodeCmd 2410;
BA_ "SPN" SG_ 2566786814 DataDictionaryRow 2427;
BA_ "SPN" SG_ 2566786814 DataDictionaryColumn 2428;
BA_ "SPN" SG_ 2566786814 ImplementType 2425;
BA_ "SPN" SG_ 2566786814 ImplementPos 2426;
BA_ "SPN" SG_ 2566786814 DataFormat_ErrorCondition 2419;
BA_ "SigType" SG_ 2566786814 DataFormat_ErrorCondition 4;
BA_ "SPN" SG_ 2566786814 ProcessDataType 2420;
BA_ "SigType" SG_ 2566786814 ProcessDataType 4;
BA_ "SPN" SG_ 2566786814 ProcessDataModifier 2421;
BA_ "SPN" SG_ 2566786814 RepetitionRateParameter 2418;
BA_ "SPN" SG_ 2566785534 TrctrFcltyRspLmt_RqstSttsRprting 7444;
BA_ "SPN" SG_ 2566785278 TrctrFcltyRqLmt_RqstSttsRporting 7445;
BA_ "SigType" SG_ 2566770686 NumberOfMembers 3;
BA_ "SPN" SG_ 2566770430 NAMEOfWorkingSetMember 2845;
BA_ "SPN" SG_ 2566761470 PGNOfConfigurableMessageDesired 3330;
BA_ "SPN" SG_ 2566761470 MessageSelectionCtrl 3329;
BA_ "SigType" SG_ 2566761470 MessageSelectionCtrl 1;
BA_ "SPN" SG_ 2566754814 AutomaticTransferSwitchStatus 3547;
BA_ "SPN" SG_ 2566754814 UtilityCircuitBreakerStatus 3546;
BA_ "SPN" SG_ 2566754814 GeneratorCircuitBreakerStatus 3545;
BA_ "SPN" SG_ 2566754302 GeneratorTotalPercentKVAr 3592;
BA_ "SigType" SG_ 2566754302 GeneratorTotalPercentKVAr 1;
BA_ "SPN" SG_ 2566754302 GeneratorTotalPercentKVA 3591;
BA_ "SigType" SG_ 2566754302 GeneratorTotalPercentKVA 1;
BA_ "SPN" SG_ 2566754302 GeneratorTotalPercentKW 3590;
BA_ "SigType" SG_ 2566754302 GeneratorTotalPercentKW 1;
BA_ "SPN" SG_ 2566754046 GeneratorTotalKVArHoursImport 3594;
BA_ "SigType" SG_ 2566754046 GeneratorTotalKVArHoursImport 1;
BA_ "SPN" SG_ 2566754046 GeneratorTotalKVArHoursExport 3593;
BA_ "SigType" SG_ 2566754046 GeneratorTotalKVArHoursExport 1;
BA_ "SPN" SG_ 2566753790 UtilityTotalKVArHoursImport 3596;
BA_ "SigType" SG_ 2566753790 UtilityTotalKVArHoursImport 1;
BA_ "SPN" SG_ 2566753790 UtilityTotalKVArHoursExport 3595;
BA_ "SigType" SG_ 2566753790 UtilityTotalKVArHoursExport 1;
BA_ "SPN" SG_ 2566734846 MachineSelectedDirectionCmd 4312;
BA_ "SigType" SG_ 2566734846 MachineSelectedDirectionCmd 4;
BA_ "SPN" SG_ 2566734846 MchnSelectedSpeedExit_reasonCode 5818;
BA_ "SPN" SG_ 2566734846 MchineSelectedSpeedSetpointLimit 4311;
BA_ "SPN" SG_ 2566734846 MachineSelectedSpeedSetpointCmd 4310;
BA_ "SPN" SG_ 2566734590 ISOBUSCmplncCrtfctnMssgeRevision 7446;
BA_ "SPN" SG_ 2566734590 ISOBUSCmplncCrtfctnRfrenceNumber 4330;
BA_ "SPN" SG_ 2566734590 ISOBUSCmplncCrtfctonTypeTaskCtrl 4325;
BA_ "SPN" SG_ 2566734590 ISOBUSCmplncCrtfctnTypTCWrkn4326 4326;
BA_ "SPN" SG_ 2566734590 ISOBUSCmplncCrtfctnTypTCWrkngStM 4327;
BA_ "SPN" SG_ 2566734590 ISOBUSCmplncCrtfctnTypFileServer 4328;
BA_ "SPN" SG_ 2566734590 ISOBUSCmplncCrtfctnTypGPSRceiver 4329;
BA_ "SPN" SG_ 2566734590 ISOBUSCmplncCrtfcationTypeMinECU 4317;
BA_ "SPN" SG_ 2566734590 ISOBUSCmplncCrtfctnTypTECUClass1 4318;
BA_ "SPN" SG_ 2566734590 ISOBUSCmplncCrtfctnTypTECUClass2 4319;
BA_ "SPN" SG_ 2566734590 ISOBUSCmplncCrtfctnTypTECUClass3 4320;
BA_ "SPN" SG_ 2566734590 ISOBUSCmplncCrtfctnTypeClass3ECU 4321;
BA_ "SPN" SG_ 2566734590 ISOBUSCmplncCrtfctnTypVrtlTrmnal 4322;
BA_ "SPN" SG_ 2566734590 ISOBUSCmplncCrtfctnTypVTWrkn4323 4323;
BA_ "SPN" SG_ 2566734590 ISOBUSCmplncCrtfctnTypVTWrkngStM 4324;
BA_ "SPN" SG_ 2566734590 ISOBUSCmplncCrtfctonLaboratoryID 4316;
BA_ "SPN" SG_ 2566734590 ISOBUSCmplncCrtfctLaboratoryType 4315;
BA_ "SPN" SG_ 2566734590 ISOBUSCmplnceCertificateRevision 4314;
BA_ "SPN" SG_ 2566734590 ISOBUSCmplianceCertificationYear 4313;
BA_ "SPN" SG_ 2566718462 ImplementOperatingStateCmd 5139;
BA_ "SigType" SG_ 2566718462 ImplementOperatingStateCmd 4;
BA_ "SPN" SG_ 2566718206 StpAllImplmntOprtnsTrnstonNumber 7443;
BA_ "SPN" SG_ 2566718206 AllImplmntStpOprtngOprtnsSwtchSt 5140;
BA_ "SigType" SG_ 2566718206 AllImplmntStpOprtngOprtnsSwtchSt 4;
BA_ "SPN" SG_ 2566701566 TransOilTransCoolerOutletTemp 5938;
BA_ "SigType" SG_ 2566701566 TransOilTransCoolerOutletTemp 1;
BA_ "SPN" SG_ 2566701566 TransClutch2Press 5937;
BA_ "SigType" SG_ 2566701566 TransClutch2Press 1;
BA_ "SPN" SG_ 2499592446 TransShiftRail6Pos 5943;
BA_ "SigType" SG_ 2499592446 TransShiftRail6Pos 1;
BA_ "SPN" SG_ 2499592446 TransShiftRail5Pos 5942;
BA_ "SigType" SG_ 2499592446 TransShiftRail5Pos 1;
BA_ "SPN" SG_ 2499592446 TransShiftRail4Pos 5941;
BA_ "SigType" SG_ 2499592446 TransShiftRail4Pos 1;
BA_ "SPN" SG_ 2499592446 TransShiftRail3Pos 4220;
BA_ "SigType" SG_ 2499592446 TransShiftRail3Pos 1;
BA_ "SPN" SG_ 2499592446 TransShiftRail2Pos 4219;
BA_ "SigType" SG_ 2499592446 TransShiftRail2Pos 1;
BA_ "SPN" SG_ 2499592446 TransShiftRail1Pos 4218;
BA_ "SigType" SG_ 2499592446 TransShiftRail1Pos 1;
BA_ "SPN" SG_ 2499592190 TransHydPumpActuator2Percent 6582;
BA_ "SigType" SG_ 2499592190 TransHydPumpActuator2Percent 1;
BA_ "SPN" SG_ 2499592190 TransShiftRail6ActuatorStatus 5956;
BA_ "SigType" SG_ 2499592190 TransShiftRail6ActuatorStatus 5;
BA_ "SPN" SG_ 2499592190 TransShiftRail5ActuatorStatus 5955;
BA_ "SigType" SG_ 2499592190 TransShiftRail5ActuatorStatus 5;
BA_ "SPN" SG_ 2499592190 TransShiftRail4ActuatorStatus 5954;
BA_ "SigType" SG_ 2499592190 TransShiftRail4ActuatorStatus 5;
BA_ "SPN" SG_ 2499592190 TransShiftRail3ActuatorStatus 5953;
BA_ "SigType" SG_ 2499592190 TransShiftRail3ActuatorStatus 5;
BA_ "SPN" SG_ 2499592190 TransShiftRail2ActuatorStatus 5952;
BA_ "SigType" SG_ 2499592190 TransShiftRail2ActuatorStatus 5;
BA_ "SPN" SG_ 2499592190 TransShiftRail1ActuatorStatus 5951;
BA_ "SigType" SG_ 2499592190 TransShiftRail1ActuatorStatus 5;
BA_ "SPN" SG_ 2499592190 TrnsClutch2CoolingActuatorStatus 5950;
BA_ "SigType" SG_ 2499592190 TrnsClutch2CoolingActuatorStatus 5;
BA_ "SPN" SG_ 2499592190 TrnsClutch1CoolingActuatorStatus 5949;
BA_ "SigType" SG_ 2499592190 TrnsClutch1CoolingActuatorStatus 5;
BA_ "SPN" SG_ 2499592190 TransShiftActuator2Percent 5948;
BA_ "SigType" SG_ 2499592190 TransShiftActuator2Percent 1;
BA_ "SPN" SG_ 2499592190 TransShiftActuator1Percent 5947;
BA_ "SigType" SG_ 2499592190 TransShiftActuator1Percent 1;
BA_ "SPN" SG_ 2499592190 TransHydPumpActuator1Percent 5946;
BA_ "SigType" SG_ 2499592190 TransHydPumpActuator1Percent 1;
BA_ "SPN" SG_ 2499592190 TransClutch2ActuatorPercent 5945;
BA_ "SigType" SG_ 2499592190 TransClutch2ActuatorPercent 1;
BA_ "SPN" SG_ 2499592190 TransClutch1ActuatorPercent 5944;
BA_ "SigType" SG_ 2499592190 TransClutch1ActuatorPercent 1;
BA_ "SPN" SG_ 2365374206 DlCltchTrnsCrrntPreselectionGear 5958;
BA_ "SigType" SG_ 2365374206 DlCltchTrnsCrrntPreselectionGear 1;
BA_ "SPN" SG_ 2365374206 DlCltchTrnsSlctdPreselectionGear 5957;
BA_ "SigType" SG_ 2365374206 DlCltchTrnsSlctdPreselectionGear 1;
BA_ "SPN" SG_ 2365374206 DualClutchTransInputShaft2Speed 5961;
BA_ "SigType" SG_ 2365374206 DualClutchTransInputShaft2Speed 1;
BA_ "SPN" SG_ 2365374206 DualClutchTransInputShaft1Speed 5960;
BA_ "SigType" SG_ 2365374206 DualClutchTransInputShaft1Speed 1;
BA_ "SPN" SG_ 2566700542 TripDEF 6563;
BA_ "SigType" SG_ 2566700542 TripDEF 1;
BA_ "SPN" SG_ 2566700542 TotalDEFUsed 5963;
BA_ "SigType" SG_ 2566700542 TotalDEFUsed 1;
BA_ "SPN" SG_ 2566700286 TotalDEFUsed 5964;
BA_ "SigType" SG_ 2566700286 TotalDEFUsed 1;
BA_ "SPN" SG_ 2566700030 DEFCtrlModule2PwrSupply2 7523;
BA_ "SigType" SG_ 2566700030 DEFCtrlModule2PwrSupply2 5;
BA_ "SPN" SG_ 2566700030 DEFCtrlModule2PwrSupply1 7522;
BA_ "SigType" SG_ 2566700030 DEFCtrlModule2PwrSupply1 5;
BA_ "SPN" SG_ 2566700030 DEFCtrlModule2RelayCtrl 7521;
BA_ "SigType" SG_ 2566700030 DEFCtrlModule2RelayCtrl 5;
BA_ "SPN" SG_ 2566700030 DEFCtrlModuleCircuitBreaker 7417;
BA_ "SigType" SG_ 2566700030 DEFCtrlModuleCircuitBreaker 4;
BA_ "SPN" SG_ 2566700030 DEFCtrlModule1PwrSupply2 6309;
BA_ "SigType" SG_ 2566700030 DEFCtrlModule1PwrSupply2 5;
BA_ "SPN" SG_ 2566700030 DEFCtrlModule1PwrSupply1 5966;
BA_ "SigType" SG_ 2566700030 DEFCtrlModule1PwrSupply1 5;
BA_ "SPN" SG_ 2566700030 DEFCtrlModule1RelayCtrl 5965;
BA_ "SigType" SG_ 2566700030 DEFCtrlModule1RelayCtrl 5;
BA_ "SPN" SG_ 2566699774 DEFCtrlModule2PwrSupply2 7534;
BA_ "SigType" SG_ 2566699774 DEFCtrlModule2PwrSupply2 5;
BA_ "SPN" SG_ 2566699774 DEFCtrlModule2PwrSupply1 7533;
BA_ "SigType" SG_ 2566699774 DEFCtrlModule2PwrSupply1 5;
BA_ "SPN" SG_ 2566699774 DEFCtrlModule2RelayCtrl 7532;
BA_ "SigType" SG_ 2566699774 DEFCtrlModule2RelayCtrl 5;
BA_ "SPN" SG_ 2566699774 DEFCtrlModule1PwrSupply2 6310;
BA_ "SigType" SG_ 2566699774 DEFCtrlModule1PwrSupply2 5;
BA_ "SPN" SG_ 2566699774 DEFCtrlModule1PwrSupply1 5968;
BA_ "SigType" SG_ 2566699774 DEFCtrlModule1PwrSupply1 5;
BA_ "SPN" SG_ 2566699774 DEFCtrlModule1RelayCtrl 5967;
BA_ "SigType" SG_ 2566699774 DEFCtrlModule1RelayCtrl 5;
BA_ "SPN" SG_ 2566699518 SCRSysTimeSinceLastSysCleanEvent 6941;
BA_ "SigType" SG_ 2566699518 SCRSysTimeSinceLastSysCleanEvent 1;
BA_ "SPN" SG_ 2566699518 DPFTimeToNextActiveRegen 5978;
BA_ "SigType" SG_ 2566699518 DPFTimeToNextActiveRegen 1;
BA_ "SPN" SG_ 2566699262 SCRSysTimeSinceLastSysCleanEvent 6948;
BA_ "SigType" SG_ 2566699262 SCRSysTimeSinceLastSysCleanEvent 1;
BA_ "SPN" SG_ 2566699262 DPFTimeToNextActiveRegen 5979;
BA_ "SigType" SG_ 2566699262 DPFTimeToNextActiveRegen 1;
BA_ "SPN" SG_ 2566698750 SLICrnkngPrdctdMinBatteryVoltage 7497;
BA_ "SigType" SG_ 2566698750 SLICrnkngPrdctdMinBatteryVoltage 1;
BA_ "SPN" SG_ 2566698750 SLIBatteryPackHealth 5983;
BA_ "SigType" SG_ 2566698750 SLIBatteryPackHealth 1;
BA_ "SPN" SG_ 2566698750 SLIBatteryPackCapacity 5982;
BA_ "SigType" SG_ 2566698750 SLIBatteryPackCapacity 1;
BA_ "SPN" SG_ 2566698750 SLIBatteryPackStateOfCharge 5981;
BA_ "SigType" SG_ 2566698750 SLIBatteryPackStateOfCharge 1;
BA_ "SPN" SG_ 2566698494 FusedOutput29 6047;
BA_ "SigType" SG_ 2566698494 FusedOutput29 4;
BA_ "SPN" SG_ 2566698494 FusedOutput30 6046;
BA_ "SigType" SG_ 2566698494 FusedOutput30 4;
BA_ "SPN" SG_ 2566698494 FusedOutput31 6045;
BA_ "SigType" SG_ 2566698494 FusedOutput31 4;
BA_ "SPN" SG_ 2566698494 FusedOutput32 6044;
BA_ "SigType" SG_ 2566698494 FusedOutput32 4;
BA_ "SPN" SG_ 2566698494 FusedOutput25 6043;
BA_ "SigType" SG_ 2566698494 FusedOutput25 4;
BA_ "SPN" SG_ 2566698494 FusedOutput26 6042;
BA_ "SigType" SG_ 2566698494 FusedOutput26 4;
BA_ "SPN" SG_ 2566698494 FusedOutput27 6041;
BA_ "SigType" SG_ 2566698494 FusedOutput27 4;
BA_ "SPN" SG_ 2566698494 FusedOutput28 6040;
BA_ "SigType" SG_ 2566698494 FusedOutput28 4;
BA_ "SPN" SG_ 2566698494 FusedOutput21 6039;
BA_ "SigType" SG_ 2566698494 FusedOutput21 4;
BA_ "SPN" SG_ 2566698494 FusedOutput22 6038;
BA_ "SigType" SG_ 2566698494 FusedOutput22 4;
BA_ "SPN" SG_ 2566698494 FusedOutput23 6037;
BA_ "SigType" SG_ 2566698494 FusedOutput23 4;
BA_ "SPN" SG_ 2566698494 FusedOutput24 6036;
BA_ "SigType" SG_ 2566698494 FusedOutput24 4;
BA_ "SPN" SG_ 2566698494 FusedOutput17 6035;
BA_ "SigType" SG_ 2566698494 FusedOutput17 4;
BA_ "SPN" SG_ 2566698494 FusedOutput18 6034;
BA_ "SigType" SG_ 2566698494 FusedOutput18 4;
BA_ "SPN" SG_ 2566698494 FusedOutput19 6033;
BA_ "SigType" SG_ 2566698494 FusedOutput19 4;
BA_ "SPN" SG_ 2566698494 FusedOutput20 6032;
BA_ "SigType" SG_ 2566698494 FusedOutput20 4;
BA_ "SPN" SG_ 2566698494 FusedOutput13 6031;
BA_ "SigType" SG_ 2566698494 FusedOutput13 4;
BA_ "SPN" SG_ 2566698494 FusedOutput14 6030;
BA_ "SigType" SG_ 2566698494 FusedOutput14 4;
BA_ "SPN" SG_ 2566698494 FusedOutput15 6029;
BA_ "SigType" SG_ 2566698494 FusedOutput15 4;
BA_ "SPN" SG_ 2566698494 FusedOutput16 6028;
BA_ "SigType" SG_ 2566698494 FusedOutput16 4;
BA_ "SPN" SG_ 2566698494 FusedOutput9 6027;
BA_ "SigType" SG_ 2566698494 FusedOutput9 4;
BA_ "SPN" SG_ 2566698494 FusedOutput10 6026;
BA_ "SigType" SG_ 2566698494 FusedOutput10 4;
BA_ "SPN" SG_ 2566698494 FusedOutput11 6025;
BA_ "SigType" SG_ 2566698494 FusedOutput11 4;
BA_ "SPN" SG_ 2566698494 FusedOutput12 6024;
BA_ "SigType" SG_ 2566698494 FusedOutput12 4;
BA_ "SPN" SG_ 2566698494 FusedOutput5 6023;
BA_ "SigType" SG_ 2566698494 FusedOutput5 4;
BA_ "SPN" SG_ 2566698494 FusedOutput6 6022;
BA_ "SigType" SG_ 2566698494 FusedOutput6 4;
BA_ "SPN" SG_ 2566698494 FusedOutput7 6021;
BA_ "SigType" SG_ 2566698494 FusedOutput7 4;
BA_ "SPN" SG_ 2566698494 FusedOutput8 6020;
BA_ "SigType" SG_ 2566698494 FusedOutput8 4;
BA_ "SPN" SG_ 2566698494 FusedOutput1 6019;
BA_ "SigType" SG_ 2566698494 FusedOutput1 4;
BA_ "SPN" SG_ 2566698494 FusedOutput2 6018;
BA_ "SigType" SG_ 2566698494 FusedOutput2 4;
BA_ "SPN" SG_ 2566698494 FusedOutput3 6017;
BA_ "SigType" SG_ 2566698494 FusedOutput3 4;
BA_ "SPN" SG_ 2566698494 FusedOutput4 6016;
BA_ "SigType" SG_ 2566698494 FusedOutput4 4;
VAL_ 2558590718 ShutdownCmd 0 "Off" 1 "On" 2 "Reserved" 3 "Don't Care / Take No Action";
VAL_ 2558590718 PropulsionDisableReq 0 "Off" 1 "On" 2 "Reserved" 3 "Don't Care / Take No Action";
VAL_ 2558590718 HybrdSystmRgnrtvBrakingDisableRq 0 "Regenerative braking disable request is not active" 1 "Regenerative braking disable request is active" 2 "Reserved" 3 "Don't care / take no action";
VAL_ 2558590718 HybridSystemProtectionOverrideRq 0 "Not active" 1 "Active" 2 "Reserved" 3 "Don't care / take no action";
VAL_ 2350710526 TransOvCtrlModePriority_7038 0 "Highest priority" 1 "High priority" 2 "Medium priority" 3 "Low priority";
VAL_ 2350710526 TransOverrideCtrlMode_7037 0 "Override disabled" 1 "Speed control" 2 "Torque control" 3 "Speed/torque limit control";
VAL_ 2566801918 GroundBasedDirection 0 "Reverse" 1 "Forward" 2 "Error indication" 3 "Not available";
VAL_ 2566801662 KeySwitchNOTOFF 0 "Key Switch Off" 1 "Key Switch Not Off" 2 "Error indication" 3 "Not available";
VAL_ 2566801662 WheelBasedDirection 0 "Reverse" 1 "Forward" 2 "Error indication" 3 "Not available";
VAL_ 2566801406 ImplementInWorkState 0 "Implement is “out of work”" 1 "Implement is “in-work”" 2 "Error indication" 3 "Not available";
VAL_ 2566801406 ImplementTransportState 0 "Implement may Not be transported " 1 "Implement may be transported" 2 "Error indication" 3 "Not available";
VAL_ 2566801406 ImplementParkState 0 "Implement may Not be disconnected " 1 "Implement may be disconnected" 2 "Error indication" 3 "Not available";
VAL_ 2566801406 ImplementWorkState 0 "Implement is Not ready for field work " 1 "Implement is ready for field work" 2 "Error indication" 3 "Not available";
VAL_ 2566801406 MaintainECUPower 0 "No Further Requirement for ECU_PWR" 1 "Requirement for 2 more seconds of ECU_PWR" 2 "Reserved " 3 "Don’t Care";
VAL_ 2566801406 MaintainAcuatorPower 0 "No Further Requirement for PWR" 1 "Requirement for 2 more seconds of PWR" 2 "Reserved " 3 "Don’t Care";
VAL_ 2566801150 FrontHitchInworkIndication 0 "Hitch position is out-of-work " 1 "Hitch position is in-work" 2 "Error indication" 3 "Not available";
VAL_ 2566800894 RearHitchInworkIndication 0 "Hitch position is out-of-work " 1 "Hitch position is in-work" 2 "Error indication" 3 "Not available";
VAL_ 2566800638 FrontPowerTakeOffEngagement 0 "Power take off disengaged" 1 "Power take off engaged" 2 "Error indication" 3 "Not available";
VAL_ 2566800638 FrontPowerTakeOffMode 0 "Power take off mode is 540" 1 "Power take off mode is 1000" 2 "Error indication" 3 "Not available";
VAL_ 2566800638 FrontPowerTakeOffEconomyMode 0 "Power take off economy mode is disengaged" 1 "Power take off economy mode is engaged" 2 "Error indication" 3 "Not available";
VAL_ 2566800382 RearPowerTakeOffEngagement 0 "Power take off disengaged" 1 "Power take off engaged" 2 "Error indication" 3 "Not available";
VAL_ 2566800382 RearPowerTakeOffMode 0 "Power take off mode is 540" 1 "Power take off mode is 1000" 2 "Error indication" 3 "Not available";
VAL_ 2566800382 RearPowerTakeOffEconomyMode 0 "Power take off economy mode is disengaged" 1 "Power take off economy mode is engaged" 2 "Error indication" 3 "Not available";
VAL_ 2566800126 FrontPowerTakeOffModeCmd 0 "Select 540 rpm mode" 1 "Select 1000 rpm mode " 2 "Reserved" 3 "Don’t Care";
VAL_ 2566800126 RearPowerTakeOffModeCmd 0 "Select 540 rpm mode" 1 "Select 1000 rpm mode " 2 "Reserved" 3 "Don’t Care";
VAL_ 2566800126 FrontPowerTakeOffEconomyModeCmd 0 "Disengage Power take off‘s economy mode" 1 "Engage Power take off‘s economy mode" 2 "Reserved" 3 "Don’t Care";
VAL_ 2566800126 RearPowerTakeOffEconomyModeCmd 0 "Disengage Power take off‘s economy mode" 1 "Engage Power take off‘s economy mode" 2 "Reserved" 3 "Don’t Care";
VAL_ 2566800126 FrontPowerTakeOffEngagementCmd 0 "Disengage Power take off" 1 "Engage Power take off " 2 "Reserved" 3 "Don’t Care";
VAL_ 2566800126 RearPowerTakeOffEngagementCmd 0 "Disengage Power take off" 1 "Engage Power take off " 2 "Reserved" 3 "Don’t Care";
VAL_ 2566799358 AuxValve15FailSafeModeCmd 0 "Block" 1 "Float" 2 "Reserved" 3 "Don’t Care";
VAL_ 2566799358 AuxValve15StateCmd 0 "Block" 1 "Extend" 2 "Retract" 3 "Float" 15 "Don’t Care";
VAL_ 2566799102 AuxValve14FailSafeModeCmd 0 "Block" 1 "Float" 2 "Reserved" 3 "Don’t Care";
VAL_ 2566799102 AuxValve14StateCmd 0 "Block" 1 "Extend" 2 "Retract" 3 "Float" 15 "Don’t Care";
VAL_ 2566798846 AuxValve13FailSafeModeCmd 0 "Block" 1 "Float" 2 "Reserved" 3 "Don’t Care";
VAL_ 2566798846 AuxValve13StateCmd 0 "Block" 1 "Extend" 2 "Retract" 3 "Float" 15 "Don’t Care";
VAL_ 2566798590 AuxValve12FailSafeModeCmd 0 "Block" 1 "Float" 2 "Reserved" 3 "Don’t Care";
VAL_ 2566798590 AuxValve12StateCmd 0 "Block" 1 "Extend" 2 "Retract" 3 "Float" 15 "Don’t Care";
VAL_ 2566798334 AuxValve11FailSafeModeCmd 0 "Block" 1 "Float" 2 "Reserved" 3 "Don’t Care";
VAL_ 2566798334 AuxValve11StateCmd 0 "Block" 1 "Extend" 2 "Retract" 3 "Float" 15 "Don’t Care";
VAL_ 2566798078 AuxValve10FailSafeModeCmd 0 "Block" 1 "Float" 2 "Reserved" 3 "Don’t Care";
VAL_ 2566798078 AuxValve10StateCmd 0 "Block" 1 "Extend" 2 "Retract" 3 "Float" 15 "Don’t Care";
VAL_ 2566797822 AuxValve9FailSafeModeCmd 0 "Block" 1 "Float" 2 "Reserved" 3 "Don’t Care";
VAL_ 2566797822 AuxValve9StateCmd 0 "Block" 1 "Extend" 2 "Retract" 3 "Float" 15 "Don’t Care";
VAL_ 2566797566 AuxValve8FailSafeModeCmd 0 "Block" 1 "Float" 2 "Reserved" 3 "Don’t Care";
VAL_ 2566797566 AuxValve8StateCmd 0 "Block" 1 "Extend" 2 "Retract" 3 "Float" 15 "Don’t Care";
VAL_ 2566797310 AuxValve7FailSafeModeCmd 0 "Block" 1 "Float" 2 "Reserved" 3 "Don’t Care";
VAL_ 2566797310 AuxValve7StateCmd 0 "Block" 1 "Extend" 2 "Retract" 3 "Float" 15 "Don’t Care";
VAL_ 2566797054 AuxValve6FailSafeModeCmd 0 "Block" 1 "Float" 2 "Reserved" 3 "Don’t Care";
VAL_ 2566797054 AuxValve6StateCmd 0 "Block" 1 "Extend" 2 "Retract" 3 "Float" 15 "Don’t Care";
VAL_ 2566796798 AuxValve5FailSafeModeCmd 0 "Block" 1 "Float" 2 "Reserved" 3 "Don’t Care";
VAL_ 2566796798 AuxValve5StateCmd 0 "Block" 1 "Extend" 2 "Retract" 3 "Float" 15 "Don’t Care";
VAL_ 2566796542 AuxValve4FailSafeModeCmd 0 "Block" 1 "Float" 2 "Reserved" 3 "Don’t Care";
VAL_ 2566796542 AuxValve4StateCmd 0 "Block" 1 "Extend" 2 "Retract" 3 "Float" 15 "Don’t Care";
VAL_ 2566796286 AuxValve3FailSafeModeCmd 0 "Block" 1 "Float" 2 "Reserved" 3 "Don’t Care";
VAL_ 2566796286 AuxValve3StateCmd 0 "Block" 1 "Extend" 2 "Retract" 3 "Float" 15 "Don’t Care";
VAL_ 2566796030 AuxValve2FailSafeModeCmd 0 "Block" 1 "Float" 2 "Reserved" 3 "Don’t Care";
VAL_ 2566796030 AuxValve2StateCmd 0 "Block" 1 "Extend" 2 "Retract" 3 "Float" 15 "Don’t Care";
VAL_ 2566795774 AuxValve1FailSafeModeCmd 0 "Block" 1 "Float" 2 "Reserved" 3 "Don’t Care";
VAL_ 2566795774 AuxValve1StateCmd 0 "Block" 1 "Extend" 2 "Retract" 3 "Float" 15 "Don’t Care";
VAL_ 2566795518 AuxValve0FailSafeModeCmd 0 "Block" 1 "Float" 2 "Reserved" 3 "Don’t Care";
VAL_ 2566795518 AuxValve0StateCmd 0 "Block" 1 "Extend" 2 "Retract" 3 "Float" 15 "Don’t Care";
VAL_ 2566791166 AuxValve15FailSafeMode 0 "Block" 1 "Float" 2 "Error" 3 "Not available";
VAL_ 2566791166 AuxValve15State 0 "Blocked" 1 "Extend" 2 "Retract" 3 "Floating" 15 "Don’t Care";
VAL_ 2566790910 AuxValve14FailSafeMode 0 "Block" 1 "Float" 2 "Error indication" 3 "Not available";
VAL_ 2566790910 AuxValve14State 0 "Blocked" 1 "Extend" 2 "Retract" 3 "Floating" 15 "Don’t Care";
VAL_ 2566790654 AuxValve13FailSafeMode 0 "Block" 1 "Float" 2 "Error indication" 3 "Not available";
VAL_ 2566790654 AuxValve13State 0 "Blocked" 1 "Extend" 2 "Retract" 3 "Floating" 15 "Don’t Care";
VAL_ 2566790398 AuxValve12FailSafeMode 0 "Block" 1 "Float" 2 "Error indication" 3 "Not available";
VAL_ 2566790398 AuxValve12State 0 "Blocked" 1 "Extend" 2 "Retract" 3 "Floating" 15 "Don’t Care";
VAL_ 2566790142 AuxValve11FailSafeMode 0 "Block" 1 "Float" 2 "Error indication" 3 "Not available";
VAL_ 2566790142 AuxValve11State 0 "Blocked" 1 "Extend" 2 "Retract" 3 "Floating" 15 "Don’t Care";
VAL_ 2566789886 AuxValve10FailSafeMode 0 "Block" 1 "Float" 2 "Error indication" 3 "Not available";
VAL_ 2566789886 AuxValve10State 0 "Blocked" 1 "Extend" 2 "Retract" 3 "Floating" 15 "Don’t Care";
VAL_ 2566789630 AuxValve9FailSafeMode 0 "Block" 1 "Float" 2 "Error indication" 3 "Not available";
VAL_ 2566789630 AuxValve9State 0 "Blocked" 1 "Extend" 2 "Retract" 3 "Floating" 15 "Don’t Care";
VAL_ 2566789374 AuxValve8FailSafeMode 0 "Block" 1 "Float" 2 "Error indication" 3 "Not available";
VAL_ 2566789374 AuxValve8State 0 "Blocked" 1 "Extend" 2 "Retract" 3 "Floating" 15 "Don’t Care";
VAL_ 2566789118 AuxValve7FailSafeMode 0 "Block" 1 "Float" 2 "Error indication" 3 "Not available";
VAL_ 2566789118 AuxValve7State 0 "Blocked" 1 "Extend" 2 "Retract" 3 "Floating" 15 "Don’t Care";
VAL_ 2566788862 AuxValve6FailSafeMode 0 "Block" 1 "Float" 2 "Error indication" 3 "Not available";
VAL_ 2566788862 AuxValve6State 0 "Blocked" 1 "Extend" 2 "Retract" 3 "Floating" 15 "Don’t Care";
VAL_ 2566788606 AuxValve5FailSafeMode 0 "Block" 1 "Float" 2 "Error indication" 3 "Not available";
VAL_ 2566788606 AuxValve5State 0 "Blocked" 1 "Extend" 2 "Retract" 3 "Floating" 15 "Don’t Care";
VAL_ 2566788350 AuxValve4FailSafeMode 0 "Block" 1 "Float" 2 "Error indication" 3 "Not available";
VAL_ 2566788350 AuxValve4State 0 "Blocked" 1 "Extend" 2 "Retract" 3 "Floating" 15 "Don’t Care";
VAL_ 2566788094 AuxValve3FailSafeMode 0 "Block" 1 "Float" 2 "Error indication" 3 "Not available";
VAL_ 2566788094 AuxValve3State 0 "Blocked" 1 "Extend" 2 "Retract" 3 "Floating" 15 "Don’t Care";
VAL_ 2566787838 AuxValve2FailSafeMode 0 "Block" 1 "Float" 2 "Error indication" 3 "Not available";
VAL_ 2566787838 AuxValve2State 0 "Blocked" 1 "Extend" 2 "Retract" 3 "Floating" 15 "Don’t Care";
VAL_ 2566787582 AuxValve1FailSafeMode 0 "Block" 1 "Float" 2 "Error indication" 3 "Not available";
VAL_ 2566787582 AuxValve1State 0 "Blocked" 1 "Extend" 2 "Retract" 3 "Floating" 15 "Don’t Care";
VAL_ 2566787326 AuxValve0FailSafeMode 0 "Block" 1 "Float" 2 "Error indication" 3 "Not available";
VAL_ 2566787326 AuxValve0State 0 "Blocked" 1 "Extend" 2 "Retract" 3 "Floating" 15 "Don’t Care";
VAL_ 2566787070 DistanceUnitCmd 0 "Metric" 1 "Imperial" 2 "Reserved" 3 "No action";
VAL_ 2566787070 AreaUnitCmd 0 "Metric" 1 "Imperial" 2 "Reserved" 3 "No action";
VAL_ 2566787070 VolumeUnitCmd 0 "Metric" 1 "Imperial" 2 "US" 3 "No action";
VAL_ 2566787070 MassUnitCmd 0 "Metric" 1 "Imperial" 2 "Tons/pounds" 3 "No action";
VAL_ 2566787070 DecimalSymbolCmd 0 "Comma is used" 1 "Point is used" 2 "Reserved" 3 "No action";
VAL_ 2566787070 TimeCmd 0 "24 hour" 1 "12 hour" 2 "Reserved" 3 "No action";
VAL_ 2566786814 DataFormat_ErrorCondition 0 "Data format is Long Integer" 1 "Data format is Floating" 2 "Data format is unsigned Long Integer" 3 "Not Available or error";
VAL_ 2566786814 ProcessDataType 0 "Data is Set Point" 1 "Data is Actual values" 2 "Message is Set Point request" 3 "Message is Actual value request";
VAL_ 2566734846 MachineSelectedDirectionCmd 0 "Reverse" 1 "Forward" 2 "Reserved" 3 "Don't care";
VAL_ 2566734590 ISOBUSCmplncCrtfctLaboratoryType 0 "Non-certified laboratory/ self certification" 1 "EU certified laboratory" 2 "NA certified laboratory" 7 "Not available";
VAL_ 2566734590 ISOBUSCmplnceCertificateRevision 0 "First Revision" 1 "Second Revision" 2 "Third Revision" 3 "Fourth Revision" 7 "Not available";
VAL_ 2566718462 ImplementOperatingStateCmd 0 "Set implement to field working state" 1 "Set implement to transport state" 2 "Set implement to park state" 3 "Take no action";
VAL_ 2566718206 AllImplmntStpOprtngOprtnsSwtchSt 0 "All implements stop operations switch OFF" 1 "All implements stop operations switch ON" 2 "Error indication" 3 "Not available";
VAL_ 2499592190 TransShiftRail6ActuatorStatus 0 "off" 1 "on" 2 "error" 3 "not available";
VAL_ 2499592190 TransShiftRail5ActuatorStatus 0 "off" 1 "on" 2 "error" 3 "not available";
VAL_ 2499592190 TransShiftRail4ActuatorStatus 0 "off" 1 "on" 2 "error" 3 "not available";
VAL_ 2499592190 TransShiftRail3ActuatorStatus 0 "off" 1 "on" 2 "error" 3 "not available";
VAL_ 2499592190 TransShiftRail2ActuatorStatus 0 "off" 1 "on" 2 "error" 3 "not available";
VAL_ 2499592190 TransShiftRail1ActuatorStatus 0 "off" 1 "on" 2 "error" 3 "not available";
VAL_ 2499592190 TrnsClutch2CoolingActuatorStatus 0 "off" 1 "on" 2 "error" 3 "not available";
VAL_ 2499592190 TrnsClutch1CoolingActuatorStatus 0 "off" 1 "on" 2 "error" 3 "not available";
VAL_ 2566700030 DEFCtrlModule2PwrSupply2 0 "Off" 1 "On: The ECU is powering the DEF dosing unit power supply" 2 "Error" 3 "Unavailable";
VAL_ 2566700030 DEFCtrlModule2PwrSupply1 0 "Off" 1 "On: The ECU is powering the DEF dosing unit power supply" 2 "Error" 3 "Unavailable";
VAL_ 2566700030 DEFCtrlModule2RelayCtrl 0 "Off" 1 "On: The ECU is powering the DEF dosing unit relay" 2 "Error" 3 "Unavailable";
VAL_ 2566700030 DEFCtrlModuleCircuitBreaker 0 "off" 1 "on" 2 "error" 3 "not available";
VAL_ 2566700030 DEFCtrlModule1PwrSupply2 0 "Off" 1 "On: The ECU is powering the DEF dosing unit power supply" 2 "Error" 3 "Unavailable";
VAL_ 2566700030 DEFCtrlModule1PwrSupply1 0 "Off" 1 "On: The ECU is powering the DEF dosing unit power supply" 2 "Error" 3 "Unavailable";
VAL_ 2566700030 DEFCtrlModule1RelayCtrl 0 "Off" 1 "On: The ECU is powering the DEF dosing unit relay" 2 "Error" 3 "Unavailable";
VAL_ 2566699774 DEFCtrlModule2PwrSupply2 0 "Off" 1 "On: The ECU is powering the DEF dosing unit relay" 2 "Error" 3 "Unavailable";
VAL_ 2566699774 DEFCtrlModule2PwrSupply1 0 "Off" 1 "On: The ECU is powering the DEF dosing unit relay" 2 "Error" 3 "Unavailable";
VAL_ 2566699774 DEFCtrlModule2RelayCtrl 0 "Off" 1 "On: The ECU is powering the DEF dosing unit relay" 2 "Error" 3 "Unavailable";
VAL_ 2566699774 DEFCtrlModule1PwrSupply2 0 "Off" 1 "On: The ECU is powering the DEF dosing unit power supply" 2 "Error" 3 "Unavailable";
VAL_ 2566699774 DEFCtrlModule1PwrSupply1 0 "Off" 1 "On: The ECU is powering the DEF dosing unit power supply" 2 "Error" 3 "Unavailable";
VAL_ 2566699774 DEFCtrlModule1RelayCtrl 0 "Off" 1 "On: The ECU is powering the DEF dosing unit relay" 2 "Error" 3 "Unavailable";
VAL_ 2566698494 FusedOutput29 0 "Output not powered" 1 "Output powered" 2 "Reserved" 3 "Take no action";
VAL_ 2566698494 FusedOutput30 0 "Output not powered" 1 "Output powered" 2 "Reserved" 3 "Take no action";
VAL_ 2566698494 FusedOutput31 0 "Output not powered" 1 "Output powered" 2 "Reserved" 3 "Take no action";
VAL_ 2566698494 FusedOutput32 0 "Output not powered" 1 "Output powered" 2 "Reserved" 3 "Take no action";
VAL_ 2566698494 FusedOutput25 0 "Output not powered" 1 "Output powered" 2 "Reserved" 3 "Take no action";
VAL_ 2566698494 FusedOutput26 0 "Output not powered" 1 "Output powered" 2 "Reserved" 3 "Take no action";
VAL_ 2566698494 FusedOutput27 0 "Output not powered" 1 "Output powered" 2 "Reserved" 3 "Take no action";
VAL_ 2566698494 FusedOutput28 0 "Output not powered" 1 "Output powered" 2 "Reserved" 3 "Take no action";
VAL_ 2566698494 FusedOutput21 0 "Output not powered" 1 "Output powered" 2 "Reserved" 3 "Take no action";
VAL_ 2566698494 FusedOutput22 0 "Output not powered" 1 "Output powered" 2 "Reserved" 3 "Take no action";
VAL_ 2566698494 FusedOutput23 0 "Output not powered" 1 "Output powered" 2 "Reserved" 3 "Take no action";
VAL_ 2566698494 FusedOutput24 0 "Output not powered" 1 "Output powered" 2 "Reserved" 3 "Take no action";
VAL_ 2566698494 FusedOutput17 0 "Output not powered" 1 "Output powered" 2 "Reserved" 3 "Take no action";
VAL_ 2566698494 FusedOutput18 0 "Output not powered" 1 "Output powered" 2 "Reserved" 3 "Take no action";
VAL_ 2566698494 FusedOutput19 0 "Output not powered" 1 "Output powered" 2 "Reserved" 3 "Take no action";
VAL_ 2566698494 FusedOutput20 0 "Output not powered" 1 "Output powered" 2 "Reserved" 3 "Take no action";
VAL_ 2566698494 FusedOutput13 0 "Output not powered" 1 "Output powered" 2 "Reserved" 3 "Take no action";
VAL_ 2566698494 FusedOutput14 0 "Output not powered" 1 "Output powered" 2 "Reserved" 3 "Take no action";
VAL_ 2566698494 FusedOutput15 0 "Output not powered" 1 "Output powered" 2 "Reserved" 3 "Take no action";
VAL_ 2566698494 FusedOutput16 0 "Output not powered" 1 "Output powered" 2 "Reserved" 3 "Take no action";
VAL_ 2566698494 FusedOutput9 0 "Output not powered" 1 "Output powered" 2 "Reserved" 3 "Take no action";
VAL_ 2566698494 FusedOutput10 0 "Output not powered" 1 "Output powered" 2 "Reserved" 3 "Take no action";
VAL_ 2566698494 FusedOutput11 0 "Output not powered" 1 "Output powered" 2 "Reserved" 3 "Take no action";
VAL_ 2566698494 FusedOutput12 0 "Output not powered" 1 "Output powered" 2 "Reserved" 3 "Take no action";
VAL_ 2566698494 FusedOutput5 0 "Output not powered" 1 "Output powered" 2 "Reserved" 3 "Take no action";
VAL_ 2566698494 FusedOutput6 0 "Output not powered" 1 "Output powered" 2 "Reserved" 3 "Take no action";
VAL_ 2566698494 FusedOutput7 0 "Output not powered" 1 "Output powered" 2 "Reserved" 3 "Take no action";
VAL_ 2566698494 FusedOutput8 0 "Output not powered" 1 "Output powered" 2 "Reserved" 3 "Take no action";
VAL_ 2566698494 FusedOutput1 0 "Output not powered" 1 "Output powered" 2 "Reserved" 3 "Take no action";
VAL_ 2566698494 FusedOutput2 0 "Output not powered" 1 "Output powered" 2 "Reserved" 3 "Take no action";
VAL_ 2566698494 FusedOutput3 0 "Output not powered" 1 "Output powered" 2 "Reserved" 3 "Take no action";
VAL_ 2566698494 FusedOutput4 0 "Output not powered" 1 "Output powered" 2 "Reserved" 3 "Take no action";
